VERSION "FM29 IBUS1 + IBUS2, V390.1 20230120, generated by sunnypilot/webhud/tools/gen_ibus.py"

NS_ :

BS_:

BU_: ADAS AMP FloatingButtons GW ICC MFSS PWC_L PWC_R RAC Rotator

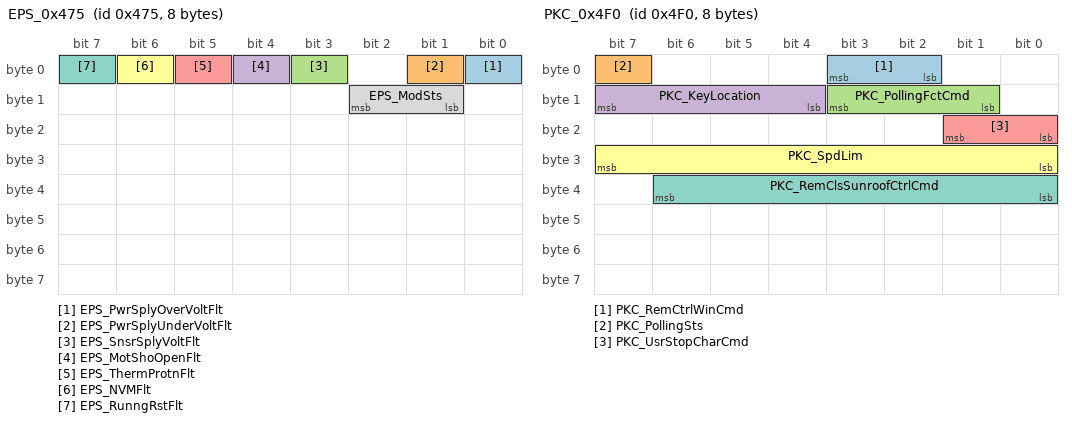
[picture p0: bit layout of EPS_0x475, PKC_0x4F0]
BO_ 1141 EPS_0x475: 8 GW
 SG_ EPS_PwrSplyOverVoltFlt : 0|1@0+ (1,0) [0|1] "" ICC
 SG_ EPS_PwrSplyUnderVoltFlt : 1|1@0+ (1,0) [0|1] "" ICC
 SG_ EPS_SnsrSplyVoltFlt : 3|1@0+ (1,0) [0|1] "" ICC
 SG_ EPS_MotShoOpenFlt : 4|1@0+ (1,0) [0|1] "" ICC
 SG_ EPS_ThermProtnFlt : 5|1@0+ (1,0) [0|1] "" ICC
 SG_ EPS_NVMFlt : 6|1@0+ (1,0) [0|1] "" ICC
 SG_ EPS_RunngRstFlt : 7|1@0+ (1,0) [0|1] "" ICC
 SG_ EPS_ModSts : 10|2@0+ (1,0) [0|3] "" ICC

BO_ 1170 PKC_0x492: 8 GW
 SG_ PKC_UsrID : 39|32@0+ (1,0) [0|4.29497e+09] "" ICC

BO_ 1264 PKC_0x4F0: 8 GW
 SG_ PKC_RemCtrlWinCmd : 3|2@0+ (1,0) [0|3] "" ICC
 SG_ PKC_PollingSts : 7|1@0+ (1,0) [0|1] "" ICC
 SG_ PKC_PollingFctCmd : 11|3@0+ (1,0) [0|7] "" ICC
 SG_ PKC_KeyLocation : 15|4@0+ (1,0) [0|15] "" ICC
 SG_ PKC_UsrStopCharCmd : 17|2@0+ (1,0) [0|3] "" ICC
 SG_ PKC_SpdLim : 31|8@0+ (1,0) [0|255] "km/h" ICC
 SG_ PKC_RemClsSunroofCtrlCmd : 38|7@0+ (1,0) [0|100] "%" ICC

BO_ 1265 DSMC_0x4F1: 8 GW
 SG_ DSMC_DrvrSeatTrackSwtSts : 9|2@0+ (1,0) [0|3] "" ICC
 SG_ DSMC_DrvrSeatHeiAdjSwtSts : 11|2@0+ (1,0) [0|3] "" ICC
 SG_ DSMC_DrvrSeatBackAdjSwtSts : 15|2@0+ (1,0) [0|3] "" ICC
 SG_ DSMC_OTARdy_Fb : 17|2@0+ (1,0) [0|3] "" ICC

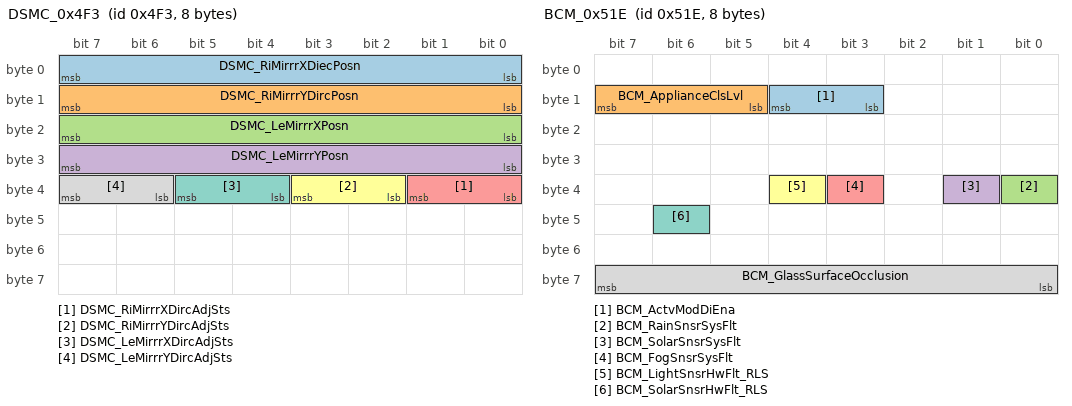
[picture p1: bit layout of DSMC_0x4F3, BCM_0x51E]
BO_ 1267 DSMC_0x4F3: 8 GW
 SG_ DSMC_RiMirrrXDiecPosn : 7|8@0+ (1,0) [0|100] "%" ICC
 SG_ DSMC_RiMirrrYDircPosn : 15|8@0+ (1,0) [0|100] "%" ICC
 SG_ DSMC_LeMirrrXPosn : 23|8@0+ (1,0) [0|100] "%" ICC
 SG_ DSMC_LeMirrrYPosn : 31|8@0+ (1,0) [0|100] "%" ICC
 SG_ DSMC_RiMirrrXDircAdjSts : 33|2@0+ (1,0) [0|3] "" ICC
 SG_ DSMC_RiMirrrYDircAdjSts : 35|2@0+ (1,0) [0|3] "" ICC
 SG_ DSMC_LeMirrrXDircAdjSts : 37|2@0+ (1,0) [0|3] "" ICC
 SG_ DSMC_LeMirrrYDircAdjSts : 39|2@0+ (1,0) [0|3] "" ICC

BO_ 1269 DSMC_0x4F5: 8 GW
 SG_ DSMC_DrvrSeatTrackPosn : 39|8@0+ (1,0) [0|100] "%" ICC
 SG_ DSMC_DrvrSeatHeiPosn : 47|8@0+ (1,0) [0|100] "%" ICC
 SG_ DSMC_DrvrSeatBackPosn : 55|8@0+ (1,0) [0|100] "%" ICC

BO_ 1272 TBOX_0x4F8: 8 GW
 SG_ TBOX_4F4_4F8_CheckSum : 7|8@0+ (1,0) [0|255] "" ICC
 SG_ TBOX_4F4_4F8_AliveCounter : 11|4@0+ (1,0) [0|14] "" ICC
 SG_ TBOX_Sw_upd : 13|2@0+ (1,0) [0|3] "" ICC
 SG_ TBOX_Flsflg : 18|3@0+ (1,0) [0|7] "" ICC
 SG_ TBOX_RemFlsh : 21|3@0+ (1,0) [0|7] "" ICC
 SG_ TBOX_FobdGWPartBUSUDSCom : 23|2@0+ (1,0) [0|3] "" ICC
 SG_ TBOX_RemChrgInsulFctReq : 25|2@0+ (1,0) [0|3] "" ICC
 SG_ TBOX_EHUSetTrvlMod : 27|2@0+ (1,0) [0|3] "" ICC
 SG_ TBOX_ResvACChrgOpenSts : 29|2@0+ (1,0) [0|3] "" ICC
 SG_ TBOX_RemKL15PwrOnReq : 31|2@0+ (1,0) [0|3] "" ICC
 SG_ TBOX_SetChrgEndSOC : 38|7@0+ (1,0) [0|100] "%" ICC
 SG_ TBOX_PreCondTriggerReq : 42|3@0+ (1,0) [0|7] "" ICC
 SG_ TBOX_BlowLvlReq : 45|3@0+ (1,0) [0|7] "" ICC
 SG_ TBOX_ICC_UpdStrt : 47|2@0+ (1,0) [0|3] "" ICC
 SG_ TBOX_VehiMod : 51|4@0+ (1,0) [0|15] "" ICC
 SG_ TBOX_Crash_cfm : 53|2@0+ (1,0) [0|3] "" ICC
 SG_ TBOX_SchedChrgnReq : 57|2@0+ (1,0) [0|3] "" ICC

BO_ 1273 TBOX_0x4F9: 8 GW
 SG_ TBOX_OTAResFb : 14|3@0+ (1,0) [0|7] "" ICC
 SG_ TBOX_SpdLim : 23|8@0+ (1,0) [0|255] "km/h" ICC
 SG_ TBOX_OTA_TiRng : 31|16@0+ (1,0) [0|65534] "mintue" ICC

BO_ 1287 VCU_0x507: 8 GW
 SG_ VCU_OTAVehInhb_QM_Fb : 5|2@0+ (1,0) [0|3] "" ICC
 SG_ VCU_OTAVehCdnChk_QM_sts : 7|2@0+ (1,0) [0|3] "" ICC
 SG_ VCU_DrvAvl : 8|1@0+ (1,0) [0|1] "" ICC
 SG_ VCU_CllsnSigSts : 9|1@0+ (1,0) [0|1] "" ICC
 SG_ VCU_VehSts_GB : 13|2@0+ (1,0) [0|3] "" ICC
 SG_ VCU_MCUOverTFlt_GB : 14|1@0+ (1,0) [0|1] "" ICC
 SG_ VCU_DrvrMotOverTFlt_GB : 15|1@0+ (1,0) [0|1] "" ICC
 SG_ VCU_SOCTooLoAlrm : 16|1@0+ (1,0) [0|1] "" ICC
 SG_ VCU_SOCJumpAlrm : 17|1@0+ (1,0) [0|1] "" ICC
 SG_ VCU_PwrBattPackMismatAlrm : 18|1@0+ (1,0) [0|1] "" ICC
 SG_ VCU_SOCTooHiAlrm : 19|1@0+ (1,0) [0|1] "" ICC
 SG_ VCU_DCDCEnaCmd : 20|1@0+ (1,0) [0|1] "" ICC
 SG_ VCU_PwrBattECCEnaCmd : 22|1@0+ (1,0) [0|1] "" ICC
 SG_ VCU_MstRlyCtrlCmd : 23|1@0+ (1,0) [0|1] "" ICC
 SG_ VCU_DCDCOutpVoltCmd : 31|8@0+ (0.1,0) [0|25.5] "V" ICC
 SG_ VCU_CCCnctnVolt : 39|8@0+ (0.1,0) [0|25.5] "V" ICC
 SG_ VCU_GearSig_GB : 43|4@0+ (1,0) [0|15] "" ICC
 SG_ VCU_DrvrMotNr_GB : 47|4@0+ (1,0) [0|15] "" ICC
 SG_ VCU_BattVolt : 55|16@0+ (0.001,0) [0|65.535] "V" ICC

BO_ 1298 PSM_0x512: 8 GW
 SG_ PSM_PassSeatHeatgSts : 4|3@0+ (1,0) [0|7] "" ICC
 SG_ PSM_PassSeatVentnSts : 7|3@0+ (1,0) [0|7] "" ICC
 SG_ PSM_PassSeatTrackAdjSts : 9|2@0+ (1,0) [0|3] "" ICC
 SG_ PSM_PassSeatBackAdjSts : 11|2@0+ (1,0) [0|3] "" ICC
 SG_ PSM_OTARdy_Fb : 13|2@0+ (1,0) [0|3] "" ICC

BO_ 1300 MFS_0x514: 8 MFSS
 SG_ MFS_0x514_CheckSum : 7|8@0+ (1,0) [0|255] "" ICC
 SG_ MFS_0x514_AliveCounter : 11|4@0+ (1,0) [0|14] "" ICC
 SG_ MFS_LeBtnNorth : 13|2@0+ (1,0) [0|3] "" ICC
 SG_ MFS_LeBtnSouth : 15|2@0+ (1,0) [0|3] "" ICC
 SG_ MFS_LeBtnWest : 17|2@0+ (1,0) [0|3] "" ICC
 SG_ MFS_LeBtnEast : 19|2@0+ (1,0) [0|3] "" ICC
 SG_ MFS_LeRollUp : 22|3@0+ (1,0) [0|7] "" ICC
 SG_ MFS_LeRollDwn : 26|3@0+ (1,0) [0|7] "" ICC
 SG_ MFS_LeRollPress : 28|2@0+ (1,0) [0|3] "" ICC
 SG_ MFS_RiBtnNorth : 30|2@0+ (1,0) [0|3] "" ICC
 SG_ MFS_RiBtnSouth : 33|2@0+ (1,0) [0|3] "" ICC
 SG_ MFS_RiBtnWest : 35|2@0+ (1,0) [0|3] "" ICC
 SG_ MFS_RiBtnEast : 37|2@0+ (1,0) [0|3] "" ICC
 SG_ MFS_RiRollUp : 42|3@0+ (1,0) [0|7] "" ICC
 SG_ MFS_RiRollDwn : 45|3@0+ (1,0) [0|7] "" ICC
 SG_ MFS_RiRollPress : 47|2@0+ (1,0) [0|3] "" ICC
 SG_ MFS_Ri_Fail : 49|2@0+ (1,0) [0|3] "" ICC
 SG_ MFS_Le_Fail : 51|2@0+ (1,0) [0|3] "" ICC

BO_ 1304 DSMC_0x518: 8 GW
 SG_ DSMC_DrvrSeatHeatgSts : 2|3@0+ (1,0) [0|7] "" ICC
 SG_ DSMC_DrvrSeatTrackAdjSts : 7|2@0+ (1,0) [0|3] "" ICC
 SG_ DSMC_DrvrSeatHeiAdjSts : 9|2@0+ (1,0) [0|3] "" ICC
 SG_ DSMC_DrvrSeatBackAdjSts : 11|2@0+ (1,0) [0|3] "" ICC
 SG_ DSMC_RearLeSeatHeatgSts : 26|3@0+ (1,0) [0|7] "" ICC
 SG_ DSMC_RearRiSeatHeatgSts : 29|3@0+ (1,0) [0|7] "" ICC

BO_ 1310 BCM_0x51E: 8 GW
 SG_ BCM_ActvModDiEna : 12|2@0+ (1,0) [0|3] "" ICC
 SG_ BCM_ApplianceClsLvl : 15|3@0+ (1,0) [0|7] "" ICC
 SG_ BCM_RainSnsrSysFlt : 32|1@0+ (1,0) [0|1] "" ICC
 SG_ BCM_SolarSnsrSysFlt : 33|1@0+ (1,0) [0|1] "" ICC
 SG_ BCM_FogSnsrSysFlt : 35|1@0+ (1,0) [0|1] "" ICC
 SG_ BCM_LightSnsrHwFlt_RLS : 36|1@0+ (1,0) [0|1] "" ICC
 SG_ BCM_SolarSnsrHwFlt_RLS : 46|1@0+ (1,0) [0|1] "" ICC
 SG_ BCM_GlassSurfaceOcclusion : 63|8@0+ (1,0) [0|255] "" ICC

BO_ 1314 DSMC_0x522: 8 GW
 SG_ DSMC_IninSts : 0|1@0+ (1,0) [0|1] "" ICC
 SG_ DSMC_CrtSts : 1|1@0+ (1,0) [0|1] "" ICC
 SG_ DSMC_SteerWhlYSts : 3|2@0+ (1,0) [0|3] "" ICC
 SG_ DSMC_SteerWhlZSts : 5|2@0+ (1,0) [0|3] "" ICC
 SG_ DSMC_SteerWhlYDirPosn : 15|8@0+ (1,0) [0|100] "%" ICC
 SG_ DSMC_SteerWhlZDirPosn : 23|8@0+ (1,0) [0|100] "%" ICC
 SG_ DSMC_RotationReqSteerClmnFb : 25|2@0+ (1,0) [0|1] "" ICC

BO_ 1315 PWC_R_0x523: 8 PWC_R
 SG_ PWC_R_ChrgSts : 18|3@0+ (1,0) [0|7] "" ICC
 SG_ PWC_R_PhnForgetRemdSts : 19|1@0+ (1,0) [0|1] "" ICC
 SG_ PWC_R_ModleSwtSts : 20|1@0+ (1,0) [0|1] "" ICC
 SG_ PWC_R_ChrgPhnChkSts : 25|1@0+ (1,0) [0|1] "" ICC

BO_ 1316 PWC_0x524: 8 PWC_L
 SG_ PWC_ChrgSts : 18|3@0+ (1,0) [0|7] "" ICC
 SG_ PWC_PhnForgetRemdSts : 19|1@0+ (1,0) [0|1] "" ICC
 SG_ PWC_ModleSwtSts : 20|1@0+ (1,0) [0|1] "" ICC
 SG_ PWC_ChrgPhnChkSts : 25|1@0+ (1,0) [0|1] "" ICC

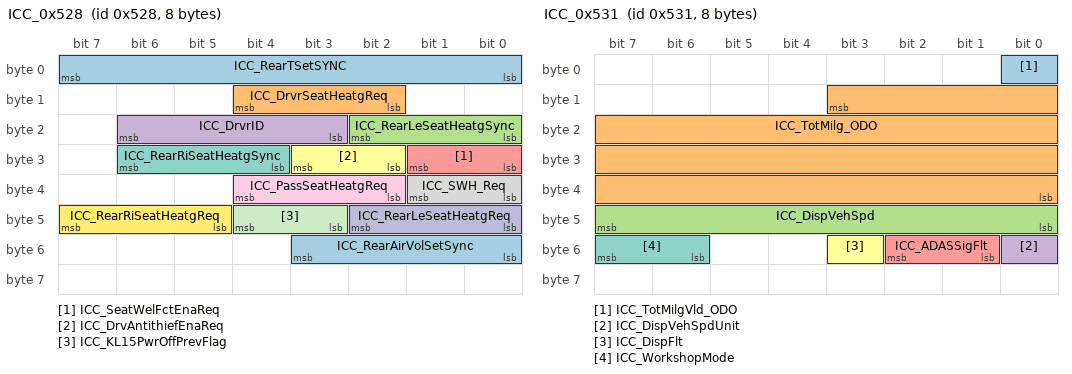
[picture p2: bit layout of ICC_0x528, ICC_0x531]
BO_ 1320 ICC_0x528: 8 ICC
 SG_ ICC_RearTSetSYNC : 7|8@0+ (0.5,0) [0|127.5] "Degree Celsius" ICC
 SG_ ICC_DrvrSeatHeatgReq : 12|3@0+ (1,0) [0|7] "" ICC
 SG_ ICC_RearLeSeatHeatgSync : 18|3@0+ (1,0) [0|7] "" ICC
 SG_ ICC_DrvrID : 22|4@0+ (1,0) [0|15] "" ICC
 SG_ ICC_SeatWelFctEnaReq : 25|2@0+ (1,0) [0|3] "" ICC
 SG_ ICC_DrvAntithiefEnaReq : 27|2@0+ (1,0) [0|3] "" ICC
 SG_ ICC_RearRiSeatHeatgSync : 30|3@0+ (1,0) [0|7] "" ICC
 SG_ ICC_SWH_Req : 33|2@0+ (1,0) [0|3] "" ICC
 SG_ ICC_PassSeatHeatgReq : 36|3@0+ (1,0) [0|7] "" ICC
 SG_ ICC_RearLeSeatHeatgReq : 42|3@0+ (1,0) [0|7] "" ICC
 SG_ ICC_KL15PwrOffPrevFlag : 44|2@0+ (1,0) [0|3] "" ICC
 SG_ ICC_RearRiSeatHeatgReq : 47|3@0+ (1,0) [0|7] "" ICC
 SG_ ICC_RearAirVolSetSync : 51|4@0+ (1,0) [0|15] "" ICC

BO_ 1321 ICC_0x529: 8 ICC
 SG_ ICC_CtrlSts_NFC : 0|1@0+ (1,0) [0|1] "" ICC
 SG_ ICC_CtrlSts_PWC : 1|1@0+ (1,0) [0|1] "" ICC
 SG_ ICC_DispUnit : 3|1@0+ (1,0) [0|1] "" ICC
 SG_ ICC_ReOperPanSwtCmd : 4|1@0+ (1,0) [0|1] "" ICC
 SG_ ICC_ReOperPanSwtSts : 5|1@0+ (1,0) [0|1] "" ICC
 SG_ ICC_SteerWhlPhnKeyBackLi : 7|2@0+ (1,0) [0|3] "" ICC
 SG_ ICC_BackgndBriLvl : 11|4@0+ (1,0) [0|15] "" ICC
 SG_ ICC_TempUnit : 15|1@0+ (1,0) [0|1] "" ICC
 SG_ ICC_V2G_Ena : 19|1@0+ (1,0) [0|1] "" ICC
 SG_ ICC_V2H_Ena : 20|1@0+ (1,0) [0|1] "" ICC
 SG_ ICC_V2V_Ena : 21|1@0+ (1,0) [0|1] "" ICC
 SG_ ICC_V2L_ChrgPortEna : 22|1@0+ (1,0) [0|1] "" ICC
 SG_ ICC_V2L_TrEna : 23|1@0+ (1,0) [0|1] "" ICC
 SG_ ICC_ReOperPanLockCmd : 33|1@0+ (1,0) [0|1] "" ICC
 SG_ ICC_RollingCounter : 39|5@0+ (1,0) [0|31] "" ICC
 SG_ ICC_WiprSrvPosn : 41|2@0+ (1,0) [0|3] "" ICC
 SG_ ICC_SpclTerrainModReq : 44|3@0+ (1,0) [0|7] "" ICC
 SG_ ICC_NavOnSts : 46|2@0+ (1,0) [0|3] "" ICC
 SG_ ICC_DoorCtrlSwtSts : 49|2@0+ (1,0) [0|3] "" ICC
 SG_ ICC_CrtLanguage : 55|6@0+ (1,0) [0|63] "" ICC
 SG_ ICC_NavBarShift : 62|7@0+ (1,0) [0|100] "" ICC

BO_ 1328 ICC_0x530: 8 ICC
 SG_ ICC_DrvrTSet : 7|8@0+ (0.5,0) [0|127.5] "Degree Celsius" ICC
 SG_ ICC_PassTSet : 15|8@0+ (0.5,0) [0|127.5] "Degree Celsius" ICC
 SG_ ICC_VSPVoiceTypSwt : 17|1@0+ (1,0) [0|1] "" ICC
 SG_ ICC_ECCAUTOReq : 19|1@0+ (1,0) [0|1] "" ICC
 SG_ ICC_DrvrSYNCReq : 20|1@0+ (1,0) [0|1] "" ICC
 SG_ ICC_ACSwtReq : 21|1@0+ (1,0) [0|1] "" ICC
 SG_ ICC_AirVolSet : 27|4@0+ (1,0) [0|15] "" ICC
 SG_ ICC_ECCIntExtCircReq : 28|1@0+ (1,0) [0|1] "" ICC
 SG_ ICC_AirClnSwtReq : 29|1@0+ (1,0) [0|1] "" ICC
 SG_ ICC_MaxFrntDefrstSet : 30|1@0+ (1,0) [0|1] "" ICC
 SG_ ICC_VSPCtrlCmd : 31|1@0+ (1,0) [0|1] "" ICC
 SG_ ICC_NavCtryCod : 39|8@0+ (1,0) [0|255] "" ICC
 SG_ ICC_NavRoadTyp : 43|4@0+ (1,0) [0|15] "" ICC
 SG_ ICC_NavSpdLimUnit : 45|2@0+ (1,0) [0|3] "" ICC
 SG_ ICC_NavSpdLimSts : 47|2@0+ (1,0) [0|3] "" ICC
 SG_ ICC_NavSpdLim : 53|6@0+ (1,0) [0|63] "" ICC
 SG_ ICC_BlowWinBtn : 55|1@0+ (1,0) [0|1] "" ICC
 SG_ ICC_NavSpdLimExitDst : 63|8@0+ (10,0) [0|2550] "m" ICC

BO_ 1329 ICC_0x531: 8 ICC
 SG_ ICC_TotMilgVld_ODO : 0|1@0+ (1,0) [0|1] "" ICC
 SG_ ICC_TotMilg_ODO : 11|28@0+ (0.01,0) [0|2e+06] "km" ICC
 SG_ ICC_DispVehSpd : 47|8@0+ (1,0) [0|255] "" ICC
 SG_ ICC_DispVehSpdUnit : 48|1@0+ (1,0) [0|1] "" ICC
 SG_ ICC_ADASSigFlt : 50|2@0+ (1,0) [0|3] "" ICC
 SG_ ICC_DispFlt : 51|1@0+ (1,0) [0|1] "" ICC
 SG_ ICC_WorkshopMode : 55|2@0+ (1,0) [0|3] "" ICC

BO_ 1330 ICC_0x532: 8 ICC
 SG_ ICC_MilgOffs_ODO : 7|8@0+ (1,0) [0|255] "km" ICC
 SG_ ICC_DispTotMilg_ODO : 11|28@0+ (0.01,0) [0|2e+06] "km" ICC
 SG_ ICC_MilgDataVld_ODO : 40|1@0+ (1,0) [0|1] "" ICC
 SG_ ICC_MilgRstCntr_ODO : 42|2@0+ (1,0) [0|3] "" ICC

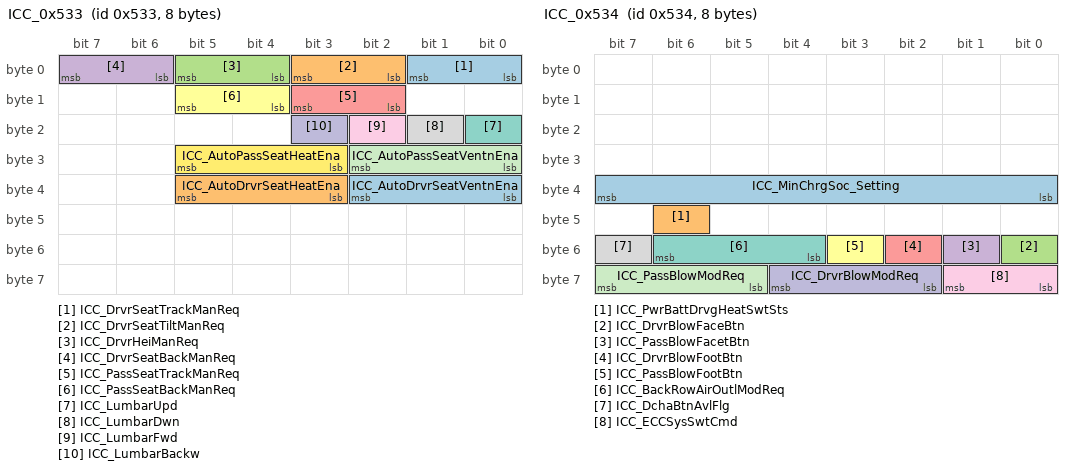
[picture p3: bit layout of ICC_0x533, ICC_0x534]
BO_ 1331 ICC_0x533: 8 ICC
 SG_ ICC_DrvrSeatTrackManReq : 1|2@0+ (1,0) [0|3] "" ICC
 SG_ ICC_DrvrSeatTiltManReq : 3|2@0+ (1,0) [0|3] "" ICC
 SG_ ICC_DrvrHeiManReq : 5|2@0+ (1,0) [0|3] "" ICC
 SG_ ICC_DrvrSeatBackManReq : 7|2@0+ (1,0) [0|3] "" ICC
 SG_ ICC_PassSeatTrackManReq : 11|2@0+ (1,0) [0|3] "" ICC
 SG_ ICC_PassSeatBackManReq : 13|2@0+ (1,0) [0|3] "" ICC
 SG_ ICC_LumbarUpd : 16|1@0+ (1,0) [0|1] "" ICC
 SG_ ICC_LumbarDwn : 17|1@0+ (1,0) [0|1] "" ICC
 SG_ ICC_LumbarFwd : 18|1@0+ (1,0) [0|1] "" ICC
 SG_ ICC_LumbarBackw : 19|1@0+ (1,0) [0|1] "" ICC
 SG_ ICC_AutoPassSeatVentnEna : 26|3@0+ (1,0) [0|7] "" ICC
 SG_ ICC_AutoPassSeatHeatEna : 29|3@0+ (1,0) [0|7] "" ICC
 SG_ ICC_AutoDrvrSeatVentnEna : 34|3@0+ (1,0) [0|7] "" ICC
 SG_ ICC_AutoDrvrSeatHeatEna : 37|3@0+ (1,0) [0|7] "" ICC

BO_ 1332 ICC_0x534: 8 ICC
 SG_ ICC_MinChrgSoc_Setting : 39|8@0+ (1,0) [0|255] "%" ICC
 SG_ ICC_PwrBattDrvgHeatSwtSts : 46|1@0+ (1,0) [0|1] "" ICC
 SG_ ICC_DrvrBlowFaceBtn : 48|1@0+ (1,0) [0|1] "" ICC
 SG_ ICC_PassBlowFacetBtn : 49|1@0+ (1,0) [0|1] "" ICC
 SG_ ICC_DrvrBlowFootBtn : 50|1@0+ (1,0) [0|1] "" ICC
 SG_ ICC_PassBlowFootBtn : 51|1@0+ (1,0) [0|1] "" ICC
 SG_ ICC_BackRowAirOutlModReq : 54|3@0+ (1,0) [0|7] "" ICC
 SG_ ICC_DchaBtnAvlFlg : 55|1@0+ (1,0) [0|1] "" ICC
 SG_ ICC_ECCSysSwtCmd : 57|2@0+ (1,0) [0|3] "" ICC
 SG_ ICC_DrvrBlowModReq : 60|3@0+ (1,0) [0|7] "" ICC
 SG_ ICC_PassBlowModReq : 63|3@0+ (1,0) [0|7] "" ICC

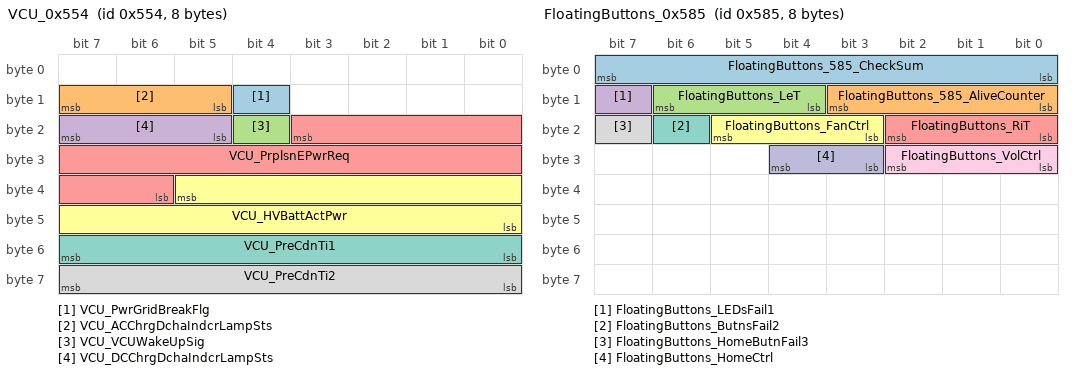
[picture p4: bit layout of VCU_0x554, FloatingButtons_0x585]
BO_ 1364 VCU_0x554: 8 GW
 SG_ VCU_PwrGridBreakFlg : 12|1@0+ (1,0) [0|1] "" ICC
 SG_ VCU_ACChrgDchaIndcrLampSts : 15|3@0+ (1,0) [0|7] "" ICC
 SG_ VCU_VCUWakeUpSig : 20|1@0+ (1,0) [0|1] "" ICC
 SG_ VCU_DCChrgDchaIndcrLampSts : 23|3@0+ (1,0) [0|7] "" ICC
 SG_ VCU_PrplsnEPwrReq : 19|14@0+ (0.1,-600) [-600|600] "KW" ICC
 SG_ VCU_HVBattActPwr : 37|14@0+ (0.1,-600) [-600|600] "KW" ICC
 SG_ VCU_PreCdnTi1 : 55|8@0+ (1,0) [0|255] "min" ICC
 SG_ VCU_PreCdnTi2 : 63|8@0+ (1,0) [0|255] "min" ICC

BO_ 1379 ICC_0x563: 8 ICC
 SG_ ICC_0x563_CheckSum : 7|8@0+ (1,0) [0|255] "" ICC
 SG_ ICC_0x563_AliveCounter : 11|4@0+ (1,0) [0|14] "" ICC
 SG_ ICC_CID_Pos_Learn : 14|3@0+ (1,0) [0|7] "" ICC
 SG_ ICC_CID_Command_Valid : 15|1@0+ (1,0) [0|1] "" ICC
 SG_ ICC_CID_Target_Position : 23|8@0+ (1.8,0) [0|360] "" ICC
 SG_ ICC_CID_Rot_Speed : 31|8@0+ (1,-100) [-100|100] "" ICC

BO_ 1400 VCU_0x578: 8 GW
 SG_ VCU_NotChrgModECCCnseEgy : 7|16@0+ (0.1,0) [0|6553.5] "kWh" ICC
 SG_ VCU_NotChrgModVehDrvCnseEgy : 23|16@0+ (0.1,0) [0|6553.5] "kWh" ICC
 SG_ VCU_NotChrgModBHMCnseEgy : 39|16@0+ (0.1,0) [0|6553.5] "kWh" ICC
 SG_ VCU_NotChrgModExtDchaCnseEgy : 55|16@0+ (0.1,0) [0|6553.5] "kWh" ICC

BO_ 1401 VCU_0x579: 8 GW
 SG_ VCU_NotChrgModAcsyCnseEgy : 7|16@0+ (0.1,0) [0|6553.5] "kWh" ICC
 SG_ VCU_NotChrgModVehTotCnseEgy : 23|16@0+ (0.1,0) [0|6553.5] "kWh" ICC
 SG_ VCU_ChrgModECCCnseEgy : 39|16@0+ (0.1,0) [0|6553.5] "kWh" ICC
 SG_ VCU_ChrgModVehChrgEgy : 55|16@0+ (0.1,0) [0|6553.5] "kWh" ICC

BO_ 1402 VCU_0x57A: 8 GW
 SG_ VCU_ChrgModBattHeatgMngCnseEgy : 7|16@0+ (0.1,0) [0|6553.5] "kWh" ICC
 SG_ VCU_ChrgModAcsyCnseEgy : 23|16@0+ (0.1,0) [0|6553.5] "kWh" ICC
 SG_ VCU_ChrgModChrgEffCnseEgy : 39|16@0+ (0.1,0) [0|6553.5] "kWh" ICC
 SG_ VCU_ChrgModVehTotChrgEgy : 55|16@0+ (0.1,0) [0|6553.5] "kWh" ICC

BO_ 1403 VCU_0x57B: 8 GW
 SG_ VCU_NotChrgModECCCnseEgyPerc : 7|12@0+ (0.1,0) [0|100] "%" ICC
 SG_ VCU_NotChrgModVehDrvCnseEgyPerc : 11|12@0+ (0.1,0) [0|100] "%" ICC
 SG_ VCU_NotChrgModBHMCnseEgyPerc : 31|12@0+ (0.1,0) [0|100] "%" ICC
 SG_ VCU_NotChrgModExtDchaCnseEgyPerc : 35|12@0+ (0.1,0) [0|100] "%" ICC
 SG_ VCU_NotChrgModAcsyCnseEgyPerc : 51|12@0+ (0.1,0) [0|100] "%" ICC

BO_ 1404 VCU_0x57C: 8 GW
 SG_ VCU_ChrgModECCCnseEgyPerc : 7|12@0+ (0.1,0) [0|100] "%" ICC
 SG_ VCU_ChrgModVehChrgEgyPerc : 11|12@0+ (0.1,0) [0|100] "%" ICC
 SG_ VCU_ChrgModBHMCnseEgyPerc : 31|12@0+ (0.1,0) [0|100] "%" ICC
 SG_ VCU_ChrgModAcsyCnseEgyPerc : 35|12@0+ (0.1,0) [0|100] "%" ICC
 SG_ VCU_ActEgyCnsTyp : 53|2@0+ (1,0) [0|3] "" ICC
 SG_ VCU_ChrgModChrgEffCnseEgyPerc : 51|12@0+ (0.1,0) [0|100] "%" ICC

BO_ 1413 FloatingButtons_0x585: 8 FloatingButtons
 SG_ FloatingButtons_585_CheckSum : 7|8@0+ (1,0) [0|255] "" ICC
 SG_ FloatingButtons_585_AliveCounter : 11|4@0+ (1,0) [0|14] "" ICC
 SG_ FloatingButtons_LeT : 14|3@0+ (1,0) [0|7] "" ICC
 SG_ FloatingButtons_LEDsFail1 : 15|1@0+ (1,0) [0|1] "" ICC
 SG_ FloatingButtons_RiT : 18|3@0+ (1,0) [0|7] "" ICC
 SG_ FloatingButtons_FanCtrl : 21|3@0+ (1,0) [0|7] "" ICC
 SG_ FloatingButtons_ButnsFail2 : 22|1@0+ (1,0) [0|1] "" ICC
 SG_ FloatingButtons_HomeButnFail3 : 23|1@0+ (1,0) [0|1] "" ICC
 SG_ FloatingButtons_VolCtrl : 26|3@0+ (1,0) [0|7] "" ICC
 SG_ FloatingButtons_HomeCtrl : 28|2@0+ (1,0) [0|3] "" ICC

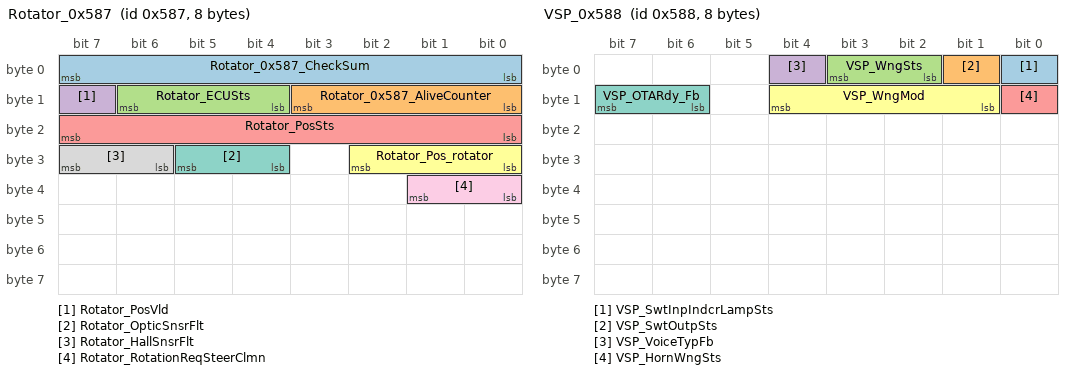
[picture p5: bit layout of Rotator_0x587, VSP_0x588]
BO_ 1415 Rotator_0x587: 8 Rotator
 SG_ Rotator_0x587_CheckSum : 7|8@0+ (1,0) [0|255] "" ICC
 SG_ Rotator_0x587_AliveCounter : 11|4@0+ (1,0) [0|14] "" ICC
 SG_ Rotator_ECUSts : 14|3@0+ (1,0) [0|7] "" ICC
 SG_ Rotator_PosVld : 15|1@0+ (1,0) [0|1] "" ICC
 SG_ Rotator_PosSts : 23|8@0+ (1.8,0) [0|90] "" ICC
 SG_ Rotator_Pos_rotator : 26|3@0+ (1,0) [0|7] "" ICC
 SG_ Rotator_OpticSnsrFlt : 29|2@0+ (1,0) [0|3] "" ICC
 SG_ Rotator_HallSnsrFlt : 31|2@0+ (1,0) [0|3] "" ICC
 SG_ Rotator_RotationReqSteerClmn : 33|2@0+ (1,0) [0|1] "" ICC

BO_ 1416 VSP_0x588: 8 GW
 SG_ VSP_SwtInpIndcrLampSts : 0|1@0+ (1,0) [0|1] "" ICC
 SG_ VSP_SwtOutpSts : 1|1@0+ (1,0) [0|1] "" ICC
 SG_ VSP_WngSts : 3|2@0+ (1,0) [0|3] "" ICC
 SG_ VSP_VoiceTypFb : 4|1@0+ (1,0) [0|1] "" ICC
 SG_ VSP_HornWngSts : 8|1@0+ (1,0) [0|1] "" ICC
 SG_ VSP_WngMod : 12|4@0+ (1,0) [0|15] "" ICC
 SG_ VSP_OTARdy_Fb : 15|2@0+ (1,0) [0|3] "" ICC

BO_ 1450 TBOX_0x5AA: 8 GW
 SG_ TBOX_Wifi_ConnectSts : 13|2@0+ (1,0) [0|3] "" ICC
 SG_ TBOX_Wifi_ConnectStrgthSts : 22|7@0+ (1,-100) [-100|-30] "dBm" ICC

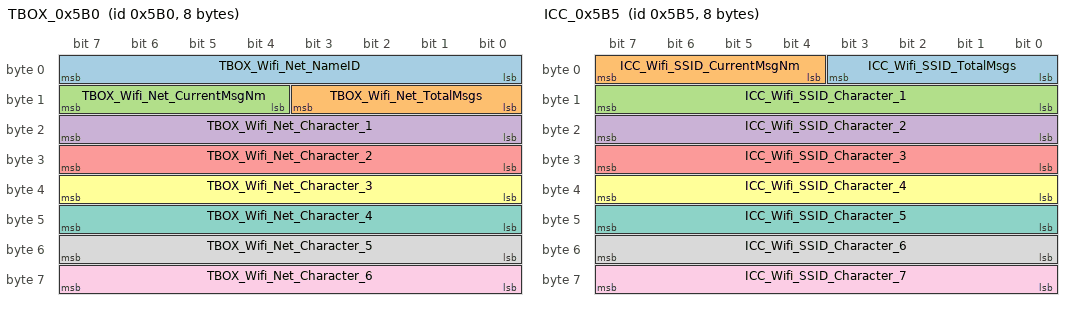
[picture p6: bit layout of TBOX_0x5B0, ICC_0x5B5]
BO_ 1456 TBOX_0x5B0: 8 GW
 SG_ TBOX_Wifi_Net_NameID : 7|8@0+ (1,0) [0|255] "" ICC
 SG_ TBOX_Wifi_Net_TotalMsgs : 11|4@0+ (1,0) [0|15] "" ICC
 SG_ TBOX_Wifi_Net_CurrentMsgNm : 15|4@0+ (1,0) [0|15] "" ICC
 SG_ TBOX_Wifi_Net_Character_1 : 23|8@0+ (1,0) [0|255] "" ICC
 SG_ TBOX_Wifi_Net_Character_2 : 31|8@0+ (1,0) [0|255] "" ICC
 SG_ TBOX_Wifi_Net_Character_3 : 39|8@0+ (1,0) [0|255] "" ICC
 SG_ TBOX_Wifi_Net_Character_4 : 47|8@0+ (1,0) [0|255] "" ICC
 SG_ TBOX_Wifi_Net_Character_5 : 55|8@0+ (1,0) [0|255] "" ICC
 SG_ TBOX_Wifi_Net_Character_6 : 63|8@0+ (1,0) [0|255] "" ICC

BO_ 1461 ICC_0x5B5: 8 ICC
 SG_ ICC_Wifi_SSID_TotalMsgs : 3|4@0+ (1,0) [0|15] "" ICC
 SG_ ICC_Wifi_SSID_CurrentMsgNm : 7|4@0+ (1,0) [0|15] "" ICC
 SG_ ICC_Wifi_SSID_Character_1 : 15|8@0+ (1,0) [0|255] "" ICC
 SG_ ICC_Wifi_SSID_Character_2 : 23|8@0+ (1,0) [0|255] "" ICC
 SG_ ICC_Wifi_SSID_Character_3 : 31|8@0+ (1,0) [0|255] "" ICC
 SG_ ICC_Wifi_SSID_Character_4 : 39|8@0+ (1,0) [0|255] "" ICC
 SG_ ICC_Wifi_SSID_Character_5 : 47|8@0+ (1,0) [0|255] "" ICC
 SG_ ICC_Wifi_SSID_Character_6 : 55|8@0+ (1,0) [0|255] "" ICC
 SG_ ICC_Wifi_SSID_Character_7 : 63|8@0+ (1,0) [0|255] "" ICC

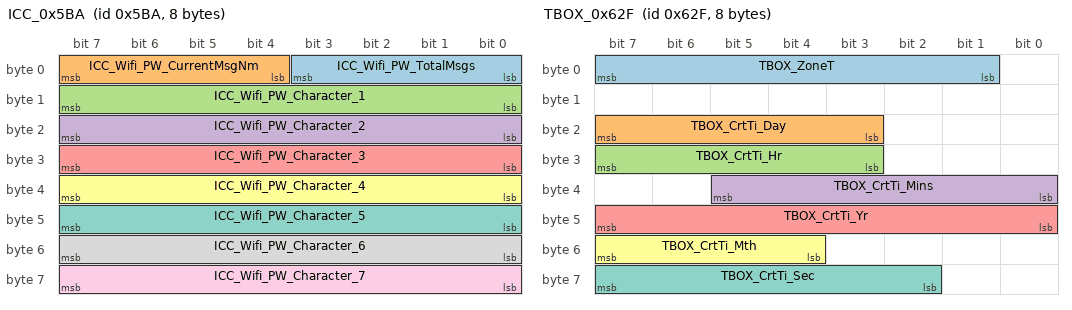
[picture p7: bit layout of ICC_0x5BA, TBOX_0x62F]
BO_ 1466 ICC_0x5BA: 8 ICC
 SG_ ICC_Wifi_PW_TotalMsgs : 3|4@0+ (1,0) [0|15] "" ICC
 SG_ ICC_Wifi_PW_CurrentMsgNm : 7|4@0+ (1,0) [0|15] "" ICC
 SG_ ICC_Wifi_PW_Character_1 : 15|8@0+ (1,0) [0|255] "" ICC
 SG_ ICC_Wifi_PW_Character_2 : 23|8@0+ (1,0) [0|255] "" ICC
 SG_ ICC_Wifi_PW_Character_3 : 31|8@0+ (1,0) [0|255] "" ICC
 SG_ ICC_Wifi_PW_Character_4 : 39|8@0+ (1,0) [0|255] "" ICC
 SG_ ICC_Wifi_PW_Character_5 : 47|8@0+ (1,0) [0|255] "" ICC
 SG_ ICC_Wifi_PW_Character_6 : 55|8@0+ (1,0) [0|255] "" ICC
 SG_ ICC_Wifi_PW_Character_7 : 63|8@0+ (1,0) [0|255] "" ICC

BO_ 1471 TBOX_0x5BF: 8 GW
 SG_ TBOX_Wifi_Net_StrgthID : 7|8@0+ (1,0) [0|255] "" ICC
 SG_ TBOX_Wifi_Net_StrgthSts : 14|7@0+ (1,-100) [-100|-30] "" ICC
 SG_ TBOX_Wifi_Net_Encryp : 17|2@0+ (1,0) [0|3] "" ICC

BO_ 1480 TBOX_0x5C8: 8 GW
 SG_ TBOX_OTA_ownCondchk : 1|2@0+ (1,0) [0|3] "" ICC
 SG_ TBOX_TerminalRemWakeupSig : 2|1@0+ (1,0) [0|1] "" ICC
 SG_ TBOX_RemSCModReq : 4|2@0+ (1,0) [0|3] "" ICC
 SG_ TBOX_RemPwrBattOpenHeatgReq : 6|2@0+ (1,0) [0|3] "" ICC
 SG_ TBOX_RemPwrBattResvHeatgReq : 7|1@0+ (1,0) [0|1] "" ICC
 SG_ TBOX_RemInsdInfoDispEna : 12|1@0+ (1,0) [0|1] "" ICC
 SG_ TBOX_RemECCDefrstModReq : 14|2@0+ (1,0) [0|3] "" ICC
 SG_ TBOX_RemECCResvDefrstReq : 15|1@0+ (1,0) [0|1] "" ICC
 SG_ TBOX_RemECCSetT : 31|8@0+ (0.5,0) [0|127.5] "Degree Celsius" ICC
 SG_ TBOX_RemResvECCSetT : 39|8@0+ (0.5,0) [0|127.5] "Degree Celsius" ICC
 SG_ TBOX_RemSOCMax : 47|8@0+ (1,0) [0|100] "" ICC
 SG_ TBOX_4GSigIND : 49|2@0+ (1,0) [0|3] "" ICC
 SG_ TBOX_Conn_Typ : 52|3@0+ (1,0) [0|7] "" ICC
 SG_ TBOX_TSPNotConn : 53|1@0+ (1,0) [0|1] "" ICC
 SG_ TBOX_EHUNotCONN : 54|1@0+ (1,0) [0|1] "" ICC
 SG_ TBOX_WIFIError : 55|1@0+ (1,0) [0|1] "" ICC
 SG_ TBOX_InnerBattError : 56|1@0+ (1,0) [0|1] "" ICC
 SG_ TBOX_VoltLow : 57|1@0+ (1,0) [0|1] "" ICC
 SG_ TBOX_VoltHigh : 58|1@0+ (1,0) [0|1] "" ICC
 SG_ TBOX_4GLoss : 59|1@0+ (1,0) [0|1] "" ICC
 SG_ TBOX_RemSWH_Req : 61|2@0+ (1,0) [0|3] "" ICC
 SG_ TBOX_OTAInhbReq : 63|2@0+ (1,0) [0|3] "" ICC

BO_ 1514 VCU_0x5EA: 8 GW
 SG_ VCU_TripMilg : 23|16@0+ (0.1,0) [0|6550] "km" ICC
 SG_ VCU_TripAvgEgyConsmd : 39|10@0+ (1,0) [0|1023] "Wh/km" ICC

BO_ 1552 ICC_0x610: 8 ICC
 SG_ ICC_UsrSetChrgRmnMilg : 7|8@0+ (1,0) [0|255] "" ICC
 SG_ ICC_EPedlSts : 9|2@0+ (1,0) [0|3] "" ICC
 SG_ ICC_AccelMod : 11|2@0+ (1,0) [0|3] "" ICC
 SG_ ICC_BoostMode : 13|2@0+ (1,0) [0|3] "" ICC
 SG_ ICC_EgyCnseClrFlg : 15|2@0+ (1,0) [0|3] "" ICC
 SG_ ICC_VehiMod : 21|4@0+ (1,0) [0|15] "" ICC
 SG_ ICC_EgyCnseStcClrFlg : 23|2@0+ (1,0) [0|3] "" ICC
 SG_ ICC_UsrSetDchaEndDrvgMilg : 17|10@0+ (1,0) [0|800] "km" ICC
 SG_ ICC_PollingFctOpenSts : 33|2@0+ (1,0) [0|3] "" ICC
 SG_ ICC_KickFctOpenSts : 35|2@0+ (1,0) [0|3] "" ICC
 SG_ ICC_UsrSetChrgGunAntithft : 36|1@0+ (1,0) [0|1] "" ICC
 SG_ ICC_ChrgInsulFctReq : 38|2@0+ (1,0) [0|3] "" ICC
 SG_ ICC_StopChrgBtn : 39|1@0+ (1,0) [0|1] "" ICC
 SG_ ICC_DrvModSig : 42|3@0+ (1,0) [0|7] "" ICC
 SG_ ICC_SetACChrgLmtCrt : 49|2@0+ (1,0) [0|3] "" ICC
 SG_ ICC_SetTrvlMod : 51|2@0+ (1,0) [0|3] "" ICC
 SG_ ICC_RegenLvl : 54|2@0+ (1,0) [0|3] "" ICC
 SG_ ICC_SetChrgEndSOC : 62|7@0+ (1,0) [0|100] "%" ICC
 SG_ ICC_StartChrgBtn : 63|1@0+ (1,0) [0|1] "" ICC

BO_ 1583 TBOX_0x62F: 8 GW
 SG_ TBOX_ZoneT : 7|7@0+ (15,-720) [-720|1185] "min" ICC
 SG_ TBOX_CrtTi_Day : 23|5@0+ (1,1) [1|31] "day" ICC
 SG_ TBOX_CrtTi_Hr : 31|5@0+ (1,0) [0|23] "hour" ICC
 SG_ TBOX_CrtTi_Mins : 37|6@0+ (1,0) [0|59] "mintue" ICC
 SG_ TBOX_CrtTi_Yr : 47|8@0+ (1,2015) [2015|2270] "year" ICC
 SG_ TBOX_CrtTi_Mth : 55|4@0+ (1,1) [1|12] "month" ICC
 SG_ TBOX_CrtTi_Sec : 63|6@0+ (1,0) [0|59] "second" ICC

BO_ 1649 PWC_R_0x671: 8 PWC_R
 SG_ PWC_R_SwVersS : 15|8@0+ (1,0) [0|255] "" ICC
 SG_ PWC_R_PartVers : 23|32@0+ (1,0) [0|4.29497e+09] "" ICC
 SG_ PWC_R_HwVers : 55|8@0+ (1,0) [0|255] "" ICC
 SG_ PWC_R_SwVersM : 63|8@0+ (1,0) [0|255] "" ICC

BO_ 1652 PWC_0x674: 8 PWC_L
 SG_ PWC_SwVersS : 15|8@0+ (1,0) [0|255] "" ICC
 SG_ PWC_PartVers : 23|32@0+ (1,0) [0|4.29497e+09] "" ICC
 SG_ PWC_HwVers : 55|8@0+ (1,0) [0|255] "" ICC
 SG_ PWC_SwVersM : 63|8@0+ (1,0) [0|255] "" ICC

BO_ 1653 AMP_0x675: 8 AMP
 SG_ AMP_CalHwVers : 7|8@0+ (1,0) [0|255] "" ICC
 SG_ AMP_SwVersS : 15|8@0+ (1,0) [0|255] "" ICC
 SG_ AMP_PartVers : 23|32@0+ (1,0) [0|4.29497e+09] "" ICC
 SG_ AMP_HwVers : 55|8@0+ (1,0) [0|255] "" ICC
 SG_ AMP_SwVersM : 63|8@0+ (1,0) [0|255] "" ICC

BO_ 1672 MFS_0x688: 8 MFSS
 SG_ MFS_SwVersS : 7|8@0+ (1,0) [0|255] "" ICC
 SG_ MFS_PartVers : 23|32@0+ (1,0) [0|4.29497e+09] "" ICC
 SG_ MFS_HwVers : 55|8@0+ (1,0) [0|255] "" ICC
 SG_ MFS_SwVersM : 63|8@0+ (1,0) [0|255] "" ICC

BO_ 1675 RAC_0x68B: 8 RAC
 SG_ RAC_SwVersS : 15|8@0+ (1,0) [0|255] "" ICC
 SG_ RAC_PartVers : 23|32@0+ (1,0) [0|4.29497e+09] "" ICC
 SG_ RAC_HwVers : 55|8@0+ (1,0) [0|255] "" ICC
 SG_ RAC_SwVersM : 63|8@0+ (1,0) [0|255] "" ICC

BO_ 1696 BMS_PVIU_EnergyCounterActual: 8 GW
 SG_ BMS_mxCounterActEnergy : 7|8@0+ (1,0) [0|255] "" ICC
 SG_ BMS_mxEnergyActValue1 : 15|24@0+ (1,0) [0|1.67772e+07] "Wh" ICC
 SG_ BMS_mxEnergyActValue2 : 39|24@0+ (1,0) [0|1.67772e+07] "Wh" ICC
 SG_ DCDC_ActTemp : 63|8@0+ (1,-40) [-40|210] "Degree Celsius" ICC

BO_ 1756 BMS_PVIU_EnergyCounterHistory: 8 GW
 SG_ BMS_mxCounterEnergy : 7|8@0+ (1,0) [0|255] "" ICC
 SG_ BMS_mxEnergyValue1 : 15|24@0+ (1,0) [0|1.67772e+07] "Wh" ICC
 SG_ BMS_mxEnergyValue2 : 39|24@0+ (1,0) [0|1.67772e+07] "Wh" ICC

BO_ 1757 BMS_PVIU_ActualPower: 8 GW
 SG_ BMS_PVIU_actPower : 7|10@0+ (1,0) [0|1023] "W" ICC
 SG_ BMS_PVIU_EnergyOverall : 23|24@0+ (1,0) [0|1.67772e+07] "kWh" ICC
 SG_ BMS_PVIU_ActEngyYear : 47|24@0+ (1,0) [0|1.67772e+07] "Wh" ICC

BO_ 1760 BCM_0x6E0: 8 GW
 SG_ BCM_VIN_Byte1 : 15|8@0+ (1,0) [0|255] "" ICC
 SG_ BCM_VIN_Byte2 : 23|8@0+ (1,0) [0|255] "" ICC
 SG_ BCM_VIN_Byte3 : 31|8@0+ (1,0) [0|255] "" ICC
 SG_ BCM_VIN_Byte4 : 39|8@0+ (1,0) [0|255] "" ICC
 SG_ BCM_VIN_Byte5 : 47|8@0+ (1,0) [0|255] "" ICC
 SG_ BCM_VIN_Byte6 : 55|8@0+ (1,0) [0|255] "" ICC
 SG_ BCM_VIN_Byte7 : 63|8@0+ (1,0) [0|255] "" ICC

BO_ 233 BMS_ActualPack_U_I: 8 GW
 SG_ BMS_Bat_HVmeasure_CheckSum : 7|8@0+ (1,0) [0|255] "" ICC
 SG_ BMS_Bat_HVmeasure_AliveCounter : 11|4@0+ (1,0) [0|14] "" ICC
 SG_ BMS_Bat_HVmeasure_Current : 39|16@0- (0.05,0) [-1250|1250] "A" ICC
 SG_ BMS_Bat_Hvmeasure_V_Pack : 55|16@0+ (0.01,0) [0|655.35] "V" ICC

BO_ 261 VCU_0x105: 8 GW
 SG_ VCU_105_CheckSum : 7|8@0+ (1,0) [0|255] "" ICC
 SG_ VCU_105_AliveCounter : 11|4@0+ (1,0) [0|14] "" ICC
 SG_ VCU_DmdTqFltFlg : 15|1@0+ (1,0) [0|1] "" ICC
 SG_ VCU_AllwMntnIndcrLamp : 16|1@0+ (1,0) [0|1] "" ICC
 SG_ VCU_AlrmLamp_FS : 17|1@0+ (1,0) [0|1] "" ICC
 SG_ VCU_VehTqDistbnRat : 45|14@0+ (0.01,0) [0|100] "" ICC

BO_ 279 ADAS_0x117: 8 ADAS
 SG_ ADAS_117_CheckSum : 7|8@0+ (1,0) [0|255] "" ICC
 SG_ ADAS_117_AliveCounter : 11|4@0+ (1,0) [0|14] "" ICC
 SG_ ADAS_OTARdy_Fb : 13|2@0+ (1,0) [0|3] "" ICC
 SG_ ADAS_OTAInhbRdy : 15|2@0+ (1,0) [0|3] "" ICC
 SG_ ADAS_LgtCtrl_Sts : 18|3@0+ (1,0) [0|7] "" ICC
 SG_ ADAS_LgtCtrl_StsVld : 20|2@0+ (1,0) [0|3] "" ICC
 SG_ ADAS_LgtCtrl_DrvrOvrdSts : 21|1@0+ (1,0) [0|1] "" ICC
 SG_ ADAS_LgtCtrl_DrvrOvrdVld : 23|2@0+ (1,0) [0|3] "" ICC
 SG_ ADAS_HAP_EmgyStandstillVld : 25|2@0+ (1,0) [0|3] "" ICC
 SG_ ADAS_HAP_EmgyEPBVld : 27|2@0+ (1,0) [0|3] "" ICC
 SG_ ADAS_HAP_EmgyStandstillReq : 28|1@0+ (1,0) [0|1] "" ICC
 SG_ ADAS_ParkStandstillReq : 29|1@0+ (1,0) [0|1] "" ICC
 SG_ ADAS_ParkStandstillVld : 31|2@0+ (1,0) [0|3] "" ICC
 SG_ ADAS_ParkGearReq : 35|4@0+ (1,0) [0|15] "" ICC
 SG_ ADAS_ParkGearReqVld : 37|2@0+ (1,0) [0|3] "" ICC
 SG_ ADAS_ISA_CutOffReqVld : 39|2@0+ (1,0) [0|3] "" ICC
 SG_ ADAS_LgtCtrl_Typ : 43|4@0+ (1,0) [0|15] "" ICC
 SG_ ADAS_HAP_EmgyEPBReq : 44|1@0+ (1,0) [0|1] "" ICC
 SG_ ADAS_ISA_CutOffReq : 46|1@0+ (1,0) [0|1] "" ICC
 SG_ ADAS_ISA_SpdLmt_VCU : 63|8@0+ (1,0) [0|255] "kph" ICC

BO_ 280 ADAS_0x118: 8 ADAS
 SG_ ADAS_118_CheckSum : 7|8@0+ (1,0) [0|255] "" ICC
 SG_ ADAS_118_AliveCounter : 11|4@0+ (1,0) [0|14] "" ICC
 SG_ ADAS_LgtCtrl_ESP_Sts : 18|3@0+ (1,0) [0|7] "" ICC
 SG_ ADAS_LgtCtrl_ESP_Vld : 20|2@0+ (1,0) [0|3] "" ICC
 SG_ ADAS_ESP_DrvrOvrdSts : 21|1@0+ (1,0) [0|1] "" ICC
 SG_ ADAS_ESP_DrvrOvrdVld : 23|2@0+ (1,0) [0|3] "" ICC
 SG_ ADAS_HBAReq : 26|3@0+ (1,0) [0|7] "" ICC
 SG_ ADAS_HBAVld : 28|2@0+ (1,0) [0|3] "" ICC
 SG_ ADAS_ESP_StandstillReq : 29|1@0+ (1,0) [0|1] "" ICC
 SG_ ADAS_ESP_StandstillVld : 31|2@0+ (1,0) [0|3] "" ICC
 SG_ ADAS_JerkReq : 33|2@0+ (1,0) [0|3] "" ICC
 SG_ ADAS_JerkReqVld : 35|2@0+ (1,0) [0|3] "" ICC
 SG_ ADAS_BrkPrefillReq : 37|2@0+ (1,0) [0|3] "" ICC
 SG_ ADAS_BrkPrefillVld : 39|2@0+ (1,0) [0|3] "" ICC
 SG_ ADAS_AEB_ActvTyp : 43|4@0+ (1,0) [0|15] "" ICC
 SG_ ADAS_AEB_DecelVld : 45|2@0+ (1,0) [0|3] "" ICC
 SG_ ADAS_AEB_DecelReq : 55|16@0+ (0.0004882,-16) [-16|15.9942] "m/s2" ICC

BO_ 281 iBooster_0x119: 8 GW
 SG_ iBooster_119_CheckSum : 7|8@0+ (1,0) [0|255] "" ICC
 SG_ iBooster_119_AliveCounter : 11|4@0+ (1,0) [0|14] "" ICC
 SG_ iBooster_OTARdy_Fb : 13|2@0+ (1,0) [0|3] "" ICC
 SG_ iBooster_WarnOn : 16|1@0+ (1,0) [0|1] "" ICC
 SG_ iBooster_BrkPedlAppldFlg : 19|1@0+ (1,0) [0|1] "" ICC
 SG_ iBooster_BrkPedlAppldVld : 25|2@0+ (1,0) [0|3] "" ICC

BO_ 369 ICC_0x171: 8 ICC
 SG_ ICC_Start_X_Coordinate : 7|16@0+ (1,0) [0|65534] "" ICC
 SG_ ICC_Start_Y_Coordinate : 23|16@0+ (1,0) [0|65534] "" ICC
 SG_ ICC_dX_Coordinate : 39|16@0+ (1,0) [0|65534] "" ICC
 SG_ ICC_dY_Coordinate : 55|16@0+ (1,0) [0|65534] "" ICC

BO_ 416 VCU_0x1A0: 8 GW
 SG_ VCU_ECC_PwrMax : 23|16@0+ (0.01,0) [0|20] "KW" ICC
 SG_ VCU_ECC_PwrMin : 39|16@0+ (0.01,0) [0|20] "KW" ICC
 SG_ VCU_DCDCPwrLimCmd : 55|11@0+ (0.01,0) [0|20] "KW" ICC

BO_ 425 ECC_0x1A9: 8 GW
 SG_ ECC_VCU_ReqChgPwrLim : 15|3@0+ (1,0) [0|7] "" ICC
 SG_ ECC_VCU_PwrReq : 23|16@0+ (0.01,0) [0|20] "KW" ICC
 SG_ ECC_OTARdy_Fb : 33|2@0+ (1,0) [0|3] "" ICC

BO_ 438 PKC_0x1B6: 8 GW
 SG_ PKC_1B6_CheckSum : 7|8@0+ (1,0) [0|255] "" ICC
 SG_ PKC_1B6_AliveCounter : 11|4@0+ (1,0) [0|14] "" ICC
 SG_ PKC_TpMnvrCancel : 13|2@0+ (1,0) [0|3] "" ICC
 SG_ PKC_TpActDeactInp : 15|2@0+ (1,0) [0|3] "" ICC
 SG_ PKC_RemPwrOnOffReq : 17|2@0+ (1,0) [0|3] "" ICC
 SG_ PKC_RemDrvgReq : 21|4@0+ (1,0) [0|15] "" ICC
 SG_ PKC_RemChrgDchaGunUnlckCmd : 23|2@0+ (1,0) [0|3] "" ICC
 SG_ PKC_RmteDviceBattLvl : 31|8@0+ (1,0) [0|100] "%" ICC
 SG_ PKC_BLE_Online : 32|1@0+ (1,0) [0|1] "" ICC
 SG_ PKC_DviceRngeDist : 34|2@0+ (1,0) [0|3] "" ICC
 SG_ PKC_DviceAliveCnt : 39|4@0+ (1,0) [0|15] "" ICC
 SG_ PKC_MnvreEnblInput : 41|2@0+ (1,0) [0|3] "" ICC
 SG_ PKC_RapActDeactInp : 47|2@0+ (1,0) [0|3] "" ICC
 SG_ PKC_MnvrRemsumeKey : 49|2@0+ (1,0) [0|3] "" ICC
 SG_ PKC_MnvrRtnStartKey : 51|2@0+ (1,0) [0|3] "" ICC
 SG_ PKC_AuthUsr : 59|2@0+ (1,0) [0|3] "" ICC
 SG_ PKC_AlcInterlockReqPromt : 61|2@0+ (1,0) [0|3] "" ICC
 SG_ PKC_NFCReminderPromt : 63|2@0+ (1,0) [0|3] "" ICC

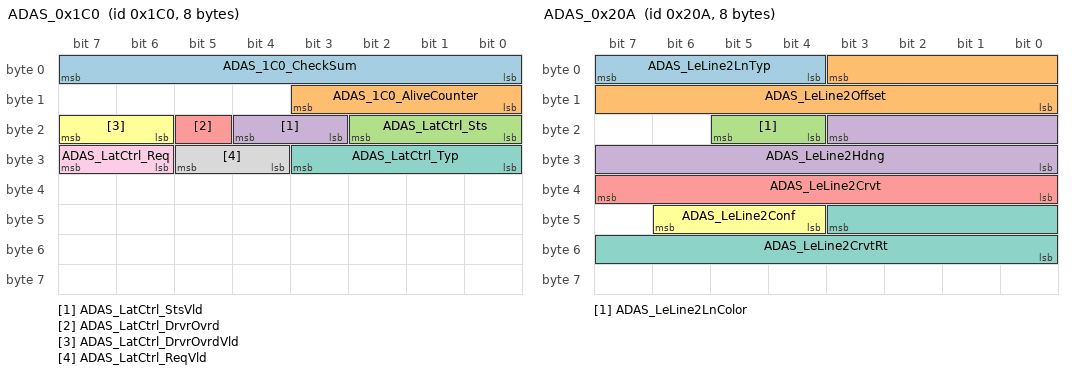
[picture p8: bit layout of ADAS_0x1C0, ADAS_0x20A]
BO_ 448 ADAS_0x1C0: 8 ADAS
 SG_ ADAS_1C0_CheckSum : 7|8@0+ (1,0) [0|255] "" ICC
 SG_ ADAS_1C0_AliveCounter : 11|4@0+ (1,0) [0|14] "" ICC
 SG_ ADAS_LatCtrl_Sts : 18|3@0+ (1,0) [0|7] "" ICC
 SG_ ADAS_LatCtrl_StsVld : 20|2@0+ (1,0) [0|3] "" ICC
 SG_ ADAS_LatCtrl_DrvrOvrd : 21|1@0+ (1,0) [0|1] "" ICC
 SG_ ADAS_LatCtrl_DrvrOvrdVld : 23|2@0+ (1,0) [0|3] "" ICC
 SG_ ADAS_LatCtrl_Typ : 27|4@0+ (1,0) [0|15] "" ICC
 SG_ ADAS_LatCtrl_ReqVld : 29|2@0+ (1,0) [0|3] "" ICC
 SG_ ADAS_LatCtrl_Req : 31|2@0+ (1,0) [0|3] "" ICC

BO_ 522 ADAS_0x20A: 8 ADAS
 SG_ ADAS_LeLine2LnTyp : 7|4@0+ (1,0) [0|15] "" ICC
 SG_ ADAS_LeLine2Offset : 3|12@0+ (0.0125,0) [0|50] "m" ICC
 SG_ ADAS_LeLine2LnColor : 21|2@0+ (1,0) [0|3] "" ICC
 SG_ ADAS_LeLine2Hdng : 19|12@0+ (0.05,0) [0|180] "deg" ICC
 SG_ ADAS_LeLine2Crvt : 39|8@0+ (50,-3150) [-3150|3200] "m" ICC
 SG_ ADAS_LeLine2Conf : 46|3@0+ (1,0) [0|7] "" ICC
 SG_ ADAS_LeLine2CrvtRt : 43|12@0+ (0.05,0) [0|180] "xx" ICC

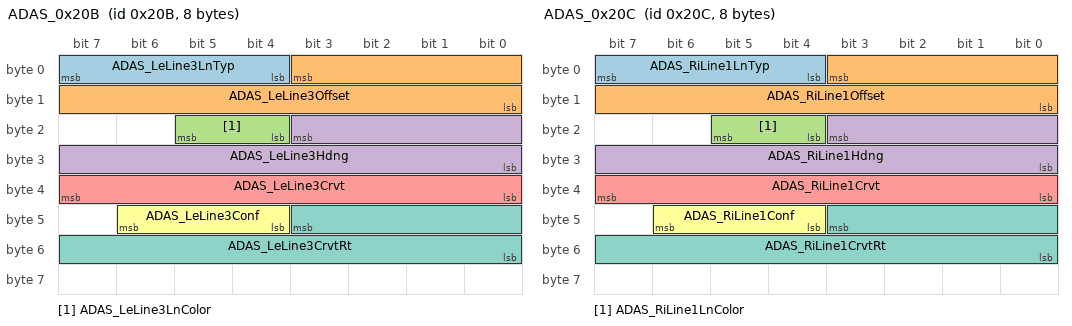
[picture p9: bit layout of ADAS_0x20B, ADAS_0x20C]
BO_ 523 ADAS_0x20B: 8 ADAS
 SG_ ADAS_LeLine3LnTyp : 7|4@0+ (1,0) [0|15] "" ICC
 SG_ ADAS_LeLine3Offset : 3|12@0+ (0.0125,0) [0|50] "m" ICC
 SG_ ADAS_LeLine3LnColor : 21|2@0+ (1,0) [0|3] "" ICC
 SG_ ADAS_LeLine3Hdng : 19|12@0+ (0.05,0) [0|180] "deg" ICC
 SG_ ADAS_LeLine3Crvt : 39|8@0+ (50,-3150) [-3150|3200] "m" ICC
 SG_ ADAS_LeLine3Conf : 46|3@0+ (1,0) [0|7] "" ICC
 SG_ ADAS_LeLine3CrvtRt : 43|12@0+ (0.0125,0) [0|50] "xx" ICC

BO_ 524 ADAS_0x20C: 8 ADAS
 SG_ ADAS_RiLine1LnTyp : 7|4@0+ (1,0) [0|15] "" ICC
 SG_ ADAS_RiLine1Offset : 3|12@0+ (0.0125,0) [0|50] "m" ICC
 SG_ ADAS_RiLine1LnColor : 21|2@0+ (1,0) [0|3] "" ICC
 SG_ ADAS_RiLine1Hdng : 19|12@0+ (0.05,0) [0|180] "deg" ICC
 SG_ ADAS_RiLine1Crvt : 39|8@0+ (50,-3150) [-3150|3200] "m" ICC
 SG_ ADAS_RiLine1Conf : 46|3@0+ (1,0) [0|7] "" ICC
 SG_ ADAS_RiLine1CrvtRt : 43|12@0+ (0.0125,0) [0|50] "xx" ICC

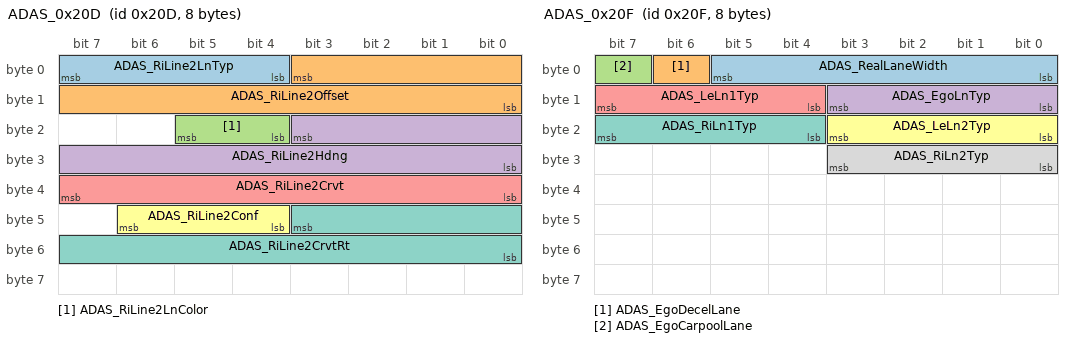
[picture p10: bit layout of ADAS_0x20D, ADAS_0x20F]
BO_ 525 ADAS_0x20D: 8 ADAS
 SG_ ADAS_RiLine2LnTyp : 7|4@0+ (1,0) [0|15] "" ICC
 SG_ ADAS_RiLine2Offset : 3|12@0+ (0.0125,0) [0|50] "m" ICC
 SG_ ADAS_RiLine2LnColor : 21|2@0+ (1,0) [0|3] "" ICC
 SG_ ADAS_RiLine2Hdng : 19|12@0+ (0.05,0) [0|180] "deg" ICC
 SG_ ADAS_RiLine2Crvt : 39|8@0+ (50,-3150) [-3150|3200] "m" ICC
 SG_ ADAS_RiLine2Conf : 46|3@0+ (1,0) [0|7] "" ICC
 SG_ ADAS_RiLine2CrvtRt : 43|12@0+ (0.0125,0) [0|50] "xx" ICC

BO_ 526 ADAS_0x20E: 8 ADAS
 SG_ ADAS_RiLine3LnTyp : 7|4@0+ (1,0) [0|15] "" ICC
 SG_ ADAS_RiLine3Offset : 3|12@0+ (0.0125,0) [0|50] "m" ICC
 SG_ ADAS_RiLine3LnColor : 21|2@0+ (1,0) [0|3] "" ICC
 SG_ ADAS_RiLine3Hdng : 19|12@0+ (0.05,0) [0|180] "deg" ICC
 SG_ ADAS_RiLine3Crvt : 39|8@0+ (50,-3150) [-3150|3200] "m" ICC
 SG_ ADAS_RiLine3Conf : 46|3@0+ (1,0) [0|7] "" ICC
 SG_ ADAS_RiLine3CrvtRt : 43|12@0+ (0.0125,0) [0|50] "xx" ICC

BO_ 527 ADAS_0x20F: 8 ADAS
 SG_ ADAS_RealLaneWidth : 5|6@0+ (0.1,0) [0|6.3] "m" ICC
 SG_ ADAS_EgoDecelLane : 6|1@0+ (1,0) [0|1] "" ICC
 SG_ ADAS_EgoCarpoolLane : 7|1@0+ (1,0) [0|1] "" ICC
 SG_ ADAS_EgoLnTyp : 11|4@0+ (1,0) [0|15] "" ICC
 SG_ ADAS_LeLn1Typ : 15|4@0+ (1,0) [0|15] "" ICC
 SG_ ADAS_LeLn2Typ : 19|4@0+ (1,0) [0|15] "" ICC
 SG_ ADAS_RiLn1Typ : 23|4@0+ (1,0) [0|15] "" ICC
 SG_ ADAS_RiLn2Typ : 27|4@0+ (1,0) [0|15] "" ICC

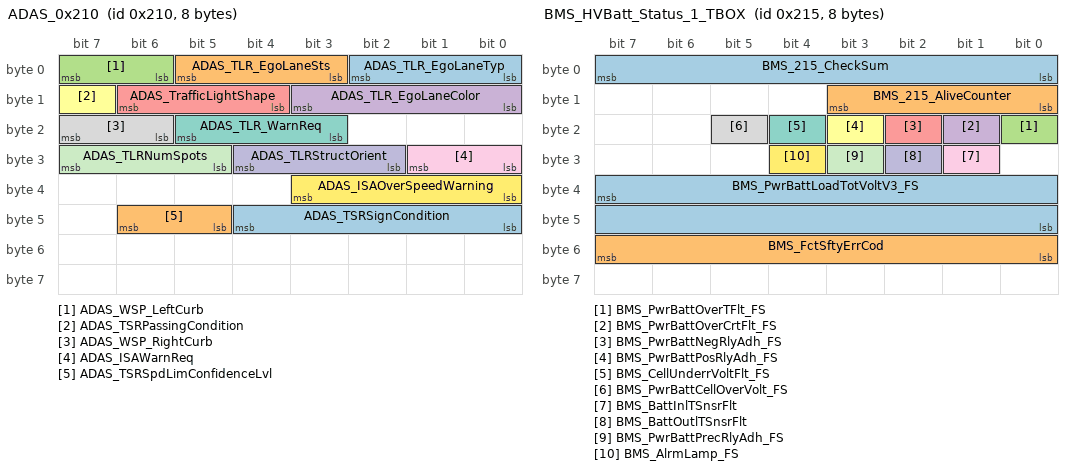
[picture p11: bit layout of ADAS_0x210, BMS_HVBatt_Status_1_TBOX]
BO_ 528 ADAS_0x210: 8 ADAS
 SG_ ADAS_TLR_EgoLaneTyp : 2|3@0+ (1,0) [0|7] "" ICC
 SG_ ADAS_TLR_EgoLaneSts : 5|3@0+ (1,0) [0|7] "" ICC
 SG_ ADAS_WSP_LeftCurb : 7|2@0+ (1,0) [0|3] "" ICC
 SG_ ADAS_TLR_EgoLaneColor : 11|4@0+ (1,0) [0|15] "" ICC
 SG_ ADAS_TrafficLightShape : 14|3@0+ (1,0) [0|7] "" ICC
 SG_ ADAS_TSRPassingCondition : 15|1@0+ (1,0) [0|1] "" ICC
 SG_ ADAS_TLR_WarnReq : 21|3@0+ (1,0) [0|7] "" ICC
 SG_ ADAS_WSP_RightCurb : 23|2@0+ (1,0) [0|3] "" ICC
 SG_ ADAS_ISAWarnReq : 25|2@0+ (1,0) [0|3] "" ICC
 SG_ ADAS_TLRStructOrient : 28|3@0+ (1,0) [0|7] "" ICC
 SG_ ADAS_TLRNumSpots : 31|3@0+ (1,0) [0|7] "" ICC
 SG_ ADAS_ISAOverSpeedWarning : 35|4@0+ (1,0) [0|15] "" ICC
 SG_ ADAS_TSRSignCondition : 44|5@0+ (1,0) [0|31] "" ICC
 SG_ ADAS_TSRSpdLimConfidenceLvl : 46|2@0+ (1,0) [0|3] "" ICC

BO_ 533 BMS_HVBatt_Status_1_TBOX: 8 GW
 SG_ BMS_215_CheckSum : 7|8@0+ (1,0) [0|255] "" ICC
 SG_ BMS_215_AliveCounter : 11|4@0+ (1,0) [0|14] "" ICC
 SG_ BMS_PwrBattOverTFlt_FS : 16|1@0+ (1,0) [0|1] "" ICC
 SG_ BMS_PwrBattOverCrtFlt_FS : 17|1@0+ (1,0) [0|1] "" ICC
 SG_ BMS_PwrBattNegRlyAdh_FS : 18|1@0+ (1,0) [0|1] "" ICC
 SG_ BMS_PwrBattPosRlyAdh_FS : 19|1@0+ (1,0) [0|1] "" ICC
 SG_ BMS_CellUnderrVoltFlt_FS : 20|1@0+ (1,0) [0|1] "" ICC
 SG_ BMS_PwrBattCellOverVolt_FS : 21|1@0+ (1,0) [0|1] "" ICC
 SG_ BMS_BattInlTSnsrFlt : 25|1@0+ (1,0) [0|1] "" ICC
 SG_ BMS_BattOutlTSnsrFlt : 26|1@0+ (1,0) [0|1] "" ICC
 SG_ BMS_PwrBattPrecRlyAdh_FS : 27|1@0+ (1,0) [0|1] "" ICC
 SG_ BMS_AlrmLamp_FS : 28|1@0+ (1,0) [0|1] "" ICC
 SG_ BMS_PwrBattLoadTotVoltV3_FS : 39|16@0+ (0.02,0) [0|1310.7] "V" ICC
 SG_ BMS_FctSftyErrCod : 55|8@0+ (1,0) [0|255] "" ICC

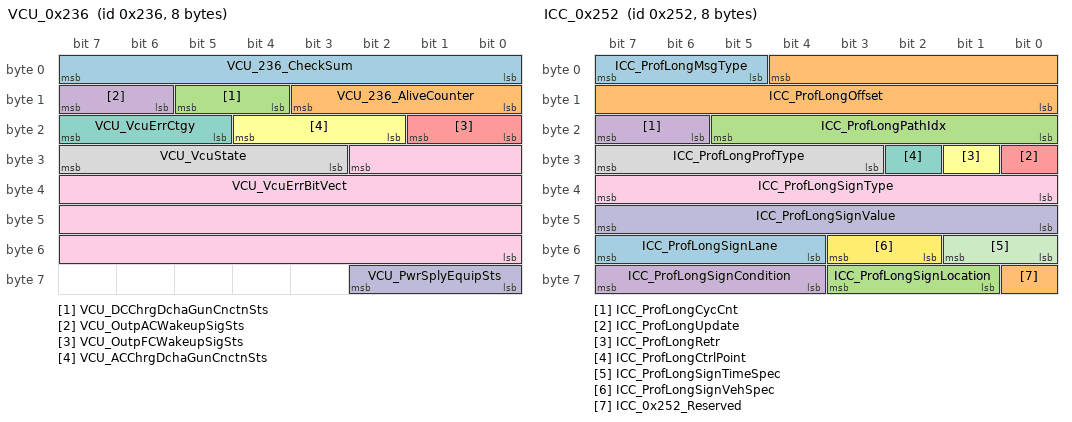
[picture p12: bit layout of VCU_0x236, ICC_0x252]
BO_ 566 VCU_0x236: 8 GW
 SG_ VCU_236_CheckSum : 7|8@0+ (1,0) [0|255] "" ICC
 SG_ VCU_236_AliveCounter : 11|4@0+ (1,0) [0|14] "" ICC
 SG_ VCU_DCChrgDchaGunCnctnSts : 13|2@0+ (1,0) [0|3] "" ICC
 SG_ VCU_OutpACWakeupSigSts : 15|2@0+ (1,0) [0|3] "" ICC
 SG_ VCU_OutpFCWakeupSigSts : 17|2@0+ (1,0) [0|3] "" ICC
 SG_ VCU_ACChrgDchaGunCnctnSts : 20|3@0+ (1,0) [0|7] "" ICC
 SG_ VCU_VcuErrCtgy : 23|3@0+ (1,0) [0|7] "" ICC
 SG_ VCU_VcuState : 31|5@0+ (1,0) [0|31] "" ICC
 SG_ VCU_VcuErrBitVect : 26|27@0+ (1,0) [0|1.34218e+08] "" ICC
 SG_ VCU_PwrSplyEquipSts : 58|3@0+ (1,0) [0|7] "" ICC

BO_ 586 BMS_HVBattCurrent_TBOX: 8 GW
 SG_ BMS_24A_CheckSum : 7|8@0+ (1,0) [0|255] "" ICC
 SG_ BMS_24A_AliveCounter : 11|4@0+ (1,0) [0|14] "" ICC
 SG_ BMS_PwrBattChrgDchaCrt1 : 23|16@0+ (0.04,-1000) [-1000|1621.4] "A" ICC
 SG_ BMS_PwrBattChrgDchaCrt2 : 39|16@0+ (0.04,-1000) [-1000|1621.4] "A" ICC
 SG_ BMS_PwrBattIntTotVoltV1 : 55|16@0+ (0.02,0) [0|1310.7] "V" ICC

BO_ 592 ICC_0x250: 8 ICC
 SG_ ICC_SegMsgType : 7|3@0+ (1,0) [0|7] "" ICC
 SG_ ICC_SegOffset : 4|13@0+ (1,0) [0|8190] "m" ICC
 SG_ ICC_SegPathIdx : 21|6@0+ (1,0) [8|63] "" ICC
 SG_ ICC_SegCycCnt : 23|2@0+ (1,0) [0|3] "" ICC
 SG_ ICC_SegUpdate : 24|1@0+ (1,0) [0|1] "" ICC
 SG_ ICC_SegRetr : 25|1@0+ (1,0) [0|1] "" ICC
 SG_ ICC_SegBuildUpArea : 27|2@0+ (1,0) [0|3] "" ICC
 SG_ ICC_SegBridge : 29|2@0+ (1,0) [0|3] "" ICC
 SG_ ICC_SegTunnel : 31|2@0+ (1,0) [0|3] "" ICC
 SG_ ICC_SegFuncRoadClass : 34|3@0+ (1,0) [0|7] "" ICC
 SG_ ICC_SegRelProbb : 39|5@0+ (3.3333,0) [0|100] "%" ICC
 SG_ ICC_SegFormOfWay : 43|4@0+ (1,0) [0|15] "" ICC
 SG_ ICC_SegCmplxInsct : 45|2@0+ (1,0) [0|3] "" ICC
 SG_ ICC_SegPartOfCalcRoute : 47|2@0+ (1,0) [0|3] "" ICC
 SG_ ICC_SegEffSpdLmtType : 50|3@0+ (1,0) [0|7] "" ICC
 SG_ ICC_SegEffSpdLmt : 55|5@0+ (1,0) [0|31] "km/h or mph" ICC
 SG_ ICC_SegNumOfLaneDrvDir : 58|3@0+ (1,0) [0|7] "" ICC
 SG_ ICC_SegNumOfLaneOppDir : 60|2@0+ (1,0) [0|3] "" ICC
 SG_ ICC_SegDividedRoad : 62|2@0+ (1,0) [0|3] "" ICC

BO_ 593 ICC_0x251: 8 ICC
 SG_ ICC_StubMsgType : 7|3@0+ (1,0) [0|7] "" ICC
 SG_ ICC_StubOffset : 4|13@0+ (1,0) [0|8190] "m" ICC
 SG_ ICC_StubPathIdx : 21|6@0+ (1,0) [8|63] "" ICC
 SG_ ICC_StubCycCnt : 23|2@0+ (1,0) [0|3] "" ICC
 SG_ ICC_StubUpdate : 24|1@0+ (1,0) [0|1] "" ICC
 SG_ ICC_StubRetr : 25|1@0+ (1,0) [0|1] "" ICC
 SG_ ICC_StubStubPathIdx : 31|6@0+ (1,0) [0|63] "" ICC
 SG_ ICC_StubFuncRoadClass : 34|3@0+ (1,0) [0|7] "" ICC
 SG_ ICC_StubRelProbb : 39|5@0+ (3.333,0) [0|100] "%" ICC
 SG_ ICC_StubFormOfWay : 43|4@0+ (1,0) [0|15] "" ICC
 SG_ ICC_StubCmplxInsct : 45|2@0+ (1,0) [0|3] "" ICC
 SG_ ICC_StubPartOfCalcRout : 47|2@0+ (1,0) [0|3] "" ICC
 SG_ ICC_StubTurnAngl : 55|8@0+ (1.417,0) [0|358.583] "degrees" ICC
 SG_ ICC_StubNumOfLaneDrvDir : 58|3@0+ (1,0) [0|7] "" ICC
 SG_ ICC_StubNumOfLaneOppDir : 60|2@0+ (1,0) [0|3] "" ICC
 SG_ ICC_StubRtOfWay : 62|2@0+ (1,0) [0|3] "" ICC
 SG_ ICC_StubLastStub : 63|1@0+ (1,0) [0|1] "" ICC

BO_ 594 ICC_0x252: 8 ICC
 SG_ ICC_ProfLongMsgType : 7|3@0+ (1,0) [0|7] "" ICC
 SG_ ICC_ProfLongOffset : 4|13@0+ (1,0) [0|8190] "m" ICC
 SG_ ICC_ProfLongPathIdx : 21|6@0+ (1,0) [8|63] "" ICC
 SG_ ICC_ProfLongCycCnt : 23|2@0+ (1,0) [0|3] "" ICC
 SG_ ICC_ProfLongUpdate : 24|1@0+ (1,0) [0|1] "" ICC
 SG_ ICC_ProfLongRetr : 25|1@0+ (1,0) [0|1] "" ICC
 SG_ ICC_ProfLongCtrlPoint : 26|1@0+ (1,0) [0|1] "" ICC
 SG_ ICC_ProfLongProfType : 31|5@0+ (1,0) [0|31] "" ICC
 SG_ ICC_ProfLongSignType : 39|8@0+ (1,0) [0|255] "" ICC
 SG_ ICC_ProfLongSignValue : 47|8@0+ (1,0) [0|255] "" ICC
 SG_ ICC_ProfLongSignTimeSpec : 49|2@0+ (1,0) [0|3] "" ICC
 SG_ ICC_ProfLongSignVehSpec : 51|2@0+ (1,0) [0|3] "" ICC
 SG_ ICC_ProfLongSignLane : 55|4@0+ (1,0) [0|15] "" ICC
 SG_ ICC_0x252_Reserved : 56|1@0+ (1,0) [0|1] "" ICC
 SG_ ICC_ProfLongSignLocation : 59|3@0+ (1,0) [0|7] "" ICC
 SG_ ICC_ProfLongSignCondition : 63|4@0+ (1,0) [0|15] "" ICC

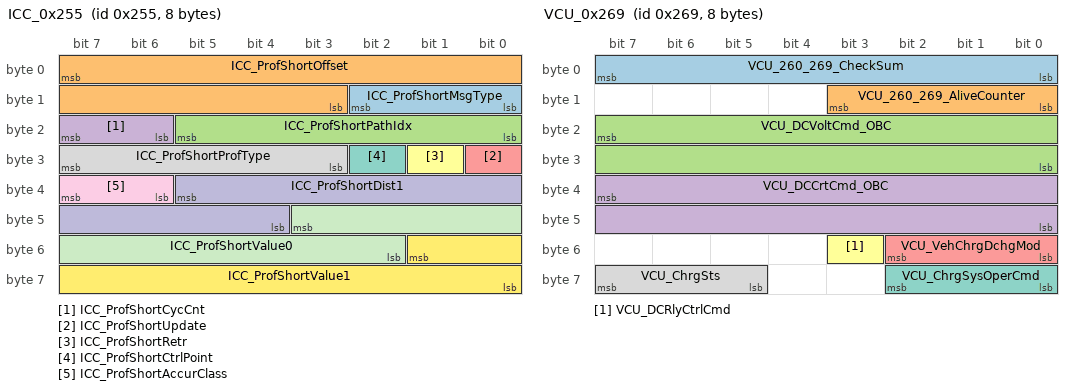
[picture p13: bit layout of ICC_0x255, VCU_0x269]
BO_ 597 ICC_0x255: 8 ICC
 SG_ ICC_ProfShortMsgType : 10|3@0+ (1,0) [0|7] "" ICC
 SG_ ICC_ProfShortOffset : 7|13@0+ (1,0) [0|8190] "m" ICC
 SG_ ICC_ProfShortPathIdx : 21|6@0+ (1,0) [8|63] "" ICC
 SG_ ICC_ProfShortCycCnt : 23|2@0+ (1,0) [0|3] "" ICC
 SG_ ICC_ProfShortUpdate : 24|1@0+ (1,0) [0|1] "" ICC
 SG_ ICC_ProfShortRetr : 25|1@0+ (1,0) [0|1] "" ICC
 SG_ ICC_ProfShortCtrlPoint : 26|1@0+ (1,0) [0|1] "" ICC
 SG_ ICC_ProfShortProfType : 31|5@0+ (1,0) [0|31] "" ICC
 SG_ ICC_ProfShortAccurClass : 39|2@0+ (1,0) [0|3] "" ICC
 SG_ ICC_ProfShortDist1 : 37|10@0+ (1,0) [0|1022] "m" ICC
 SG_ ICC_ProfShortValue0 : 43|10@0+ (1,0) [0|1023] "" ICC
 SG_ ICC_ProfShortValue1 : 49|10@0+ (1,0) [0|1023] "" ICC

BO_ 617 VCU_0x269: 8 GW
 SG_ VCU_260_269_CheckSum : 7|8@0+ (1,0) [0|255] "" ICC
 SG_ VCU_260_269_AliveCounter : 11|4@0+ (1,0) [0|14] "" ICC
 SG_ VCU_DCVoltCmd_OBC : 23|16@0+ (0.02,0) [0|1310.7] "V" ICC
 SG_ VCU_DCCrtCmd_OBC : 39|16@0+ (0.02,0) [0|1310.7] "A" ICC
 SG_ VCU_VehChrgDchgMod : 50|3@0+ (1,0) [0|7] "" ICC
 SG_ VCU_DCRlyCtrlCmd : 51|1@0+ (1,0) [0|1] "" ICC
 SG_ VCU_ChrgSysOperCmd : 58|3@0+ (1,0) [0|7] "" ICC
 SG_ VCU_ChrgSts : 63|3@0+ (1,0) [0|7] "" ICC

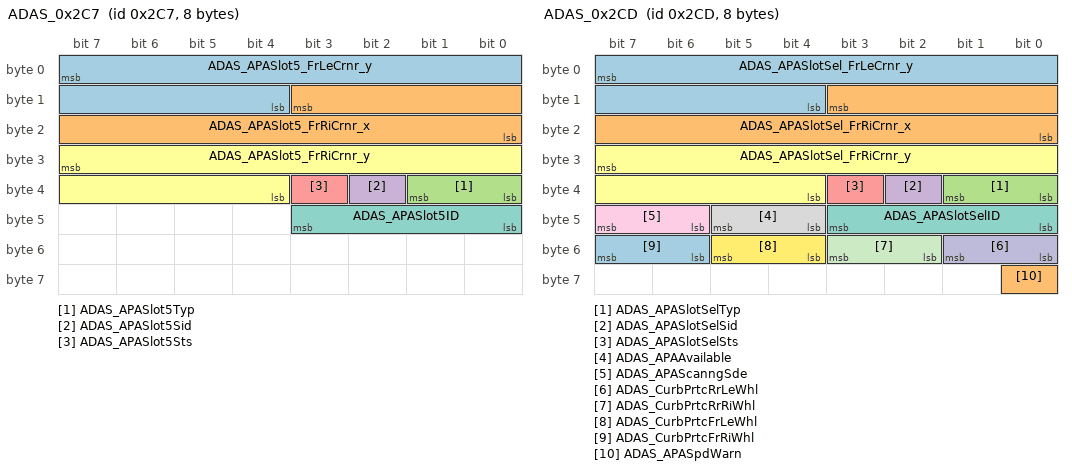
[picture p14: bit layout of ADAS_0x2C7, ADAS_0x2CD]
BO_ 711 ADAS_0x2C7: 8 ADAS
 SG_ ADAS_APASlot5_FrLeCrnr_y : 7|12@0+ (0.05,-100) [-100|100] "m" ICC
 SG_ ADAS_APASlot5_FrRiCrnr_x : 11|12@0+ (0.05,-100) [-100|100] "m" ICC
 SG_ ADAS_APASlot5Typ : 33|2@0+ (1,0) [0|3] "" ICC
 SG_ ADAS_APASlot5Sid : 34|1@0+ (1,0) [0|1] "" ICC
 SG_ ADAS_APASlot5Sts : 35|1@0+ (1,0) [0|1] "" ICC
 SG_ ADAS_APASlot5_FrRiCrnr_y : 31|12@0+ (0.05,-100) [-100|100] "m" ICC
 SG_ ADAS_APASlot5ID : 43|4@0+ (1,0) [0|15] "" ICC

BO_ 714 ADAS_0x2CA: 8 ADAS
 SG_ ADAS_APASlotSel_ReLeCrnr_x : 7|12@0+ (0.05,-100) [-100|100] "m" ICC
 SG_ ADAS_APASlotSel_ReLeCrnr_y : 11|12@0+ (0.05,-100) [-100|100] "m" ICC
 SG_ ADAS_APASlotSel_ReRiCrnr_x : 31|12@0+ (0.05,-100) [-100|100] "m" ICC
 SG_ ADAS_APASlotSel_ReRiCrnr_y : 35|12@0+ (0.05,-100) [-100|100] "m" ICC
 SG_ ADAS_APASlotSel_FrLeCrnr_x : 55|12@0+ (0.05,-100) [-100|100] "m" ICC

BO_ 717 ADAS_0x2CD: 8 ADAS
 SG_ ADAS_APASlotSel_FrLeCrnr_y : 7|12@0+ (0.05,-100) [-100|100] "m" ICC
 SG_ ADAS_APASlotSel_FrRiCrnr_x : 11|12@0+ (0.05,-100) [-100|100] "m" ICC
 SG_ ADAS_APASlotSelTyp : 33|2@0+ (1,0) [0|3] "" ICC
 SG_ ADAS_APASlotSelSid : 34|1@0+ (1,0) [0|1] "" ICC
 SG_ ADAS_APASlotSelSts : 35|1@0+ (1,0) [0|1] "" ICC
 SG_ ADAS_APASlotSel_FrRiCrnr_y : 31|12@0+ (0.05,-100) [-100|100] "m" ICC
 SG_ ADAS_APASlotSelID : 43|4@0+ (1,0) [0|15] "" ICC
 SG_ ADAS_APAAvailable : 45|2@0+ (1,0) [0|3] "" ICC
 SG_ ADAS_APAScanngSde : 47|2@0+ (1,0) [0|3] "" ICC
 SG_ ADAS_CurbPrtcRrLeWhl : 49|2@0+ (1,0) [0|3] "" ICC
 SG_ ADAS_CurbPrtcRrRiWhl : 51|2@0+ (1,0) [0|3] "" ICC
 SG_ ADAS_CurbPrtcFrLeWhl : 53|2@0+ (1,0) [0|3] "" ICC
 SG_ ADAS_CurbPrtcFrRiWhl : 55|2@0+ (1,0) [0|3] "" ICC
 SG_ ADAS_APASpdWarn : 56|1@0+ (1,0) [0|1] "" ICC

BO_ 720 ADAS_0x2D0: 8 ADAS
 SG_ ADAS_APASlot1_ReLeCrnr_x : 7|12@0+ (0.05,-100) [-100|100] "m" ICC
 SG_ ADAS_APASlot1_ReLeCrnr_y : 11|12@0+ (0.05,-100) [-100|100] "m" ICC
 SG_ ADAS_APASlot1_ReRiCrnr_x : 31|12@0+ (0.05,-100) [-100|100] "m" ICC
 SG_ ADAS_APASlot1_ReRiCrnr_y : 35|12@0+ (0.05,-100) [-100|100] "m" ICC
 SG_ ADAS_APASlot1_FrLeCrnr_x : 55|12@0+ (0.05,-100) [-100|100] "m" ICC

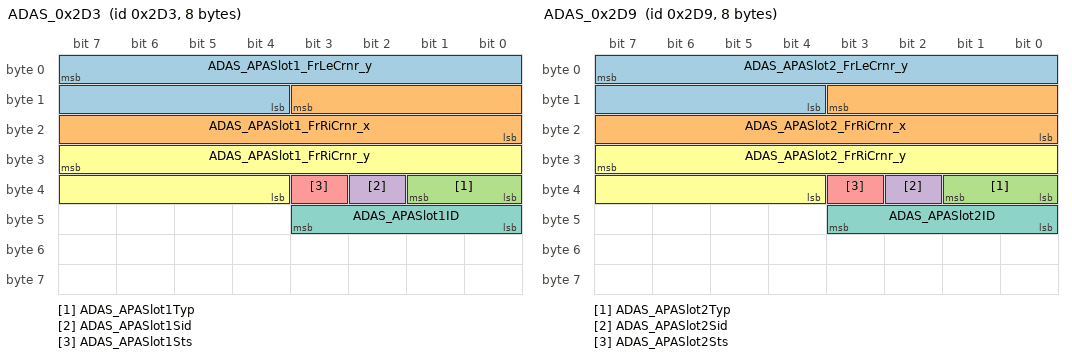
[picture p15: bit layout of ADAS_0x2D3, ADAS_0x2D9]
BO_ 723 ADAS_0x2D3: 8 ADAS
 SG_ ADAS_APASlot1_FrLeCrnr_y : 7|12@0+ (0.05,-100) [-100|100] "m" ICC
 SG_ ADAS_APASlot1_FrRiCrnr_x : 11|12@0+ (0.05,-100) [-100|100] "m" ICC
 SG_ ADAS_APASlot1Typ : 33|2@0+ (1,0) [0|3] "" ICC
 SG_ ADAS_APASlot1Sid : 34|1@0+ (1,0) [0|1] "" ICC
 SG_ ADAS_APASlot1Sts : 35|1@0+ (1,0) [0|1] "" ICC
 SG_ ADAS_APASlot1_FrRiCrnr_y : 31|12@0+ (0.05,-100) [-100|100] "m" ICC
 SG_ ADAS_APASlot1ID : 43|4@0+ (1,0) [0|15] "" ICC

BO_ 726 ADAS_0x2D6: 8 ADAS
 SG_ ADAS_APASlot2_ReLeCrnr_x : 7|12@0+ (0.05,-100) [-100|100] "m" ICC
 SG_ ADAS_APASlot2_ReLeCrnr_y : 11|12@0+ (0.05,-100) [-100|100] "m" ICC
 SG_ ADAS_APASlot2_ReRiCrnr_x : 31|12@0+ (0.05,-100) [-100|100] "m" ICC
 SG_ ADAS_APASlot2_ReRiCrnr_y : 35|12@0+ (0.05,-100) [-100|100] "m" ICC
 SG_ ADAS_APASlot2_FrLeCrnr_x : 55|12@0+ (0.05,-100) [-100|100] "m" ICC

BO_ 729 ADAS_0x2D9: 8 ADAS
 SG_ ADAS_APASlot2_FrLeCrnr_y : 7|12@0+ (0.05,-100) [-100|100] "m" ICC
 SG_ ADAS_APASlot2_FrRiCrnr_x : 11|12@0+ (0.05,-100) [-100|100] "m" ICC
 SG_ ADAS_APASlot2Typ : 33|2@0+ (1,0) [0|3] "" ICC
 SG_ ADAS_APASlot2Sid : 34|1@0+ (1,0) [0|1] "" ICC
 SG_ ADAS_APASlot2Sts : 35|1@0+ (1,0) [0|1] "" ICC
 SG_ ADAS_APASlot2_FrRiCrnr_y : 31|12@0+ (0.05,-100) [-100|100] "m" ICC
 SG_ ADAS_APASlot2ID : 43|4@0+ (1,0) [0|15] "" ICC

BO_ 732 ADAS_0x2DC: 8 ADAS
 SG_ ADAS_APASlot3_ReLeCrnr_x : 7|12@0+ (0.05,-100) [-100|100] "m" ICC
 SG_ ADAS_APASlot3_ReLeCrnr_y : 11|12@0+ (0.05,-100) [-100|100] "m" ICC
 SG_ ADAS_APASlot3_ReRiCrnr_x : 31|12@0+ (0.05,-100) [-100|100] "m" ICC
 SG_ ADAS_APASlot3_ReRiCrnr_y : 35|12@0+ (0.05,-100) [-100|100] "m" ICC
 SG_ ADAS_APASlot3_FrLeCrnr_x : 55|12@0+ (0.05,-100) [-100|100] "m" ICC

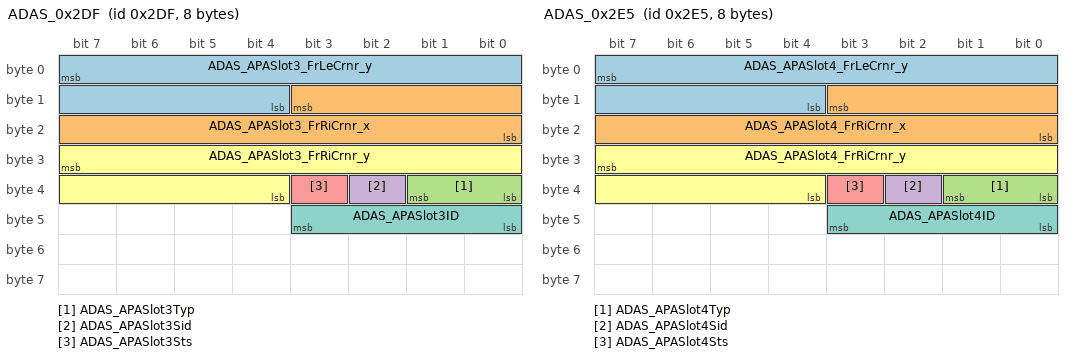
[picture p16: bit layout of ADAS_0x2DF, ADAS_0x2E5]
BO_ 735 ADAS_0x2DF: 8 ADAS
 SG_ ADAS_APASlot3_FrLeCrnr_y : 7|12@0+ (0.05,-100) [-100|100] "m" ICC
 SG_ ADAS_APASlot3_FrRiCrnr_x : 11|12@0+ (0.05,-100) [-100|100] "m" ICC
 SG_ ADAS_APASlot3Typ : 33|2@0+ (1,0) [0|3] "" ICC
 SG_ ADAS_APASlot3Sid : 34|1@0+ (1,0) [0|1] "" ICC
 SG_ ADAS_APASlot3Sts : 35|1@0+ (1,0) [0|1] "" ICC
 SG_ ADAS_APASlot3_FrRiCrnr_y : 31|12@0+ (0.05,-100) [-100|100] "m" ICC
 SG_ ADAS_APASlot3ID : 43|4@0+ (1,0) [0|15] "" ICC

BO_ 738 ADAS_0x2E2: 8 ADAS
 SG_ ADAS_APASlot4_ReLeCrnr_x : 7|12@0+ (0.05,-100) [-100|100] "m" ICC
 SG_ ADAS_APASlot4_ReLeCrnr_y : 11|12@0+ (0.05,-100) [-100|100] "m" ICC
 SG_ ADAS_APASlot4_ReRiCrnr_x : 31|12@0+ (0.05,-100) [-100|100] "m" ICC
 SG_ ADAS_APASlot4_ReRiCrnr_y : 35|12@0+ (0.05,-100) [-100|100] "m" ICC
 SG_ ADAS_APASlot4_FrLeCrnr_x : 55|12@0+ (0.05,-100) [-100|100] "m" ICC

BO_ 741 ADAS_0x2E5: 8 ADAS
 SG_ ADAS_APASlot4_FrLeCrnr_y : 7|12@0+ (0.05,-100) [-100|100] "m" ICC
 SG_ ADAS_APASlot4_FrRiCrnr_x : 11|12@0+ (0.05,-100) [-100|100] "m" ICC
 SG_ ADAS_APASlot4Typ : 33|2@0+ (1,0) [0|3] "" ICC
 SG_ ADAS_APASlot4Sid : 34|1@0+ (1,0) [0|1] "" ICC
 SG_ ADAS_APASlot4Sts : 35|1@0+ (1,0) [0|1] "" ICC
 SG_ ADAS_APASlot4_FrRiCrnr_y : 31|12@0+ (0.05,-100) [-100|100] "m" ICC
 SG_ ADAS_APASlot4ID : 43|4@0+ (1,0) [0|15] "" ICC

BO_ 744 ADAS_0x2E8: 8 ADAS
 SG_ ADAS_APASlot5_ReLeCrnr_x : 7|12@0+ (0.05,-100) [-100|100] "m" ICC
 SG_ ADAS_APASlot5_ReLeCrnr_y : 11|12@0+ (0.05,-100) [-100|100] "m" ICC
 SG_ ADAS_APASlot5_ReRiCrnr_x : 31|12@0+ (0.05,-100) [-100|100] "m" ICC
 SG_ ADAS_APASlot5_ReRiCrnr_y : 35|12@0+ (0.05,-100) [-100|100] "m" ICC
 SG_ ADAS_APASlot5_FrLeCrnr_x : 55|12@0+ (0.05,-100) [-100|100] "m" ICC

BO_ 745 ADAS_0x2E9: 8 ADAS
 SG_ ADAS_APASlot6_ReLeCrnr_x : 7|12@0+ (0.05,-100) [-100|100] "m" ICC
 SG_ ADAS_APASlot6_ReLeCrnr_y : 11|12@0+ (0.05,-100) [-100|100] "m" ICC
 SG_ ADAS_APASlot6_ReRiCrnr_x : 31|12@0+ (0.05,-100) [-100|100] "m" ICC
 SG_ ADAS_APASlot6_ReRiCrnr_y : 35|12@0+ (0.05,-100) [-100|100] "m" ICC
 SG_ ADAS_APASlot6_FrLeCrnr_x : 55|12@0+ (0.05,-100) [-100|100] "m" ICC

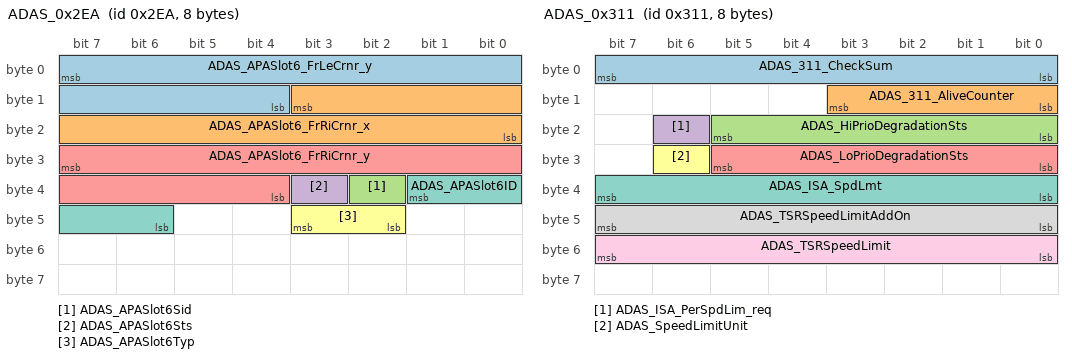
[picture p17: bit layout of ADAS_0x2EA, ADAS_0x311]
BO_ 746 ADAS_0x2EA: 8 ADAS
 SG_ ADAS_APASlot6_FrLeCrnr_y : 7|12@0+ (0.05,-100) [-100|100] "m" ICC
 SG_ ADAS_APASlot6_FrRiCrnr_x : 11|12@0+ (0.05,-100) [-100|100] "m" ICC
 SG_ ADAS_APASlot6Sid : 34|1@0+ (1,0) [0|1] "" ICC
 SG_ ADAS_APASlot6Sts : 35|1@0+ (1,0) [0|1] "" ICC
 SG_ ADAS_APASlot6_FrRiCrnr_y : 31|12@0+ (0.05,-100) [-100|100] "m" ICC
 SG_ ADAS_APASlot6Typ : 43|2@0+ (1,0) [0|3] "" ICC
 SG_ ADAS_APASlot6ID : 33|4@0+ (1,0) [0|15] "" ICC

BO_ 784 CIM_0x310: 8 GW
 SG_ CIM_310_CheckSum : 7|8@0+ (1,0) [0|255] "" ICC
 SG_ CIM_310_AliveCounter : 11|4@0+ (1,0) [0|14] "" ICC
 SG_ CIM_TurnLampSwtSts : 18|3@0+ (1,0) [0|7] "" ICC
 SG_ CIM_HiBeamSwtSts : 20|2@0+ (1,0) [0|3] "" ICC
 SG_ CIM_FrntWshrSwtSts : 22|2@0+ (1,0) [0|3] "" ICC
 SG_ CIM_FrntWiprSwtSts : 26|3@0+ (1,0) [0|7] "" ICC

BO_ 785 ADAS_0x311: 8 ADAS
 SG_ ADAS_311_CheckSum : 7|8@0+ (1,0) [0|255] "" ICC
 SG_ ADAS_311_AliveCounter : 11|4@0+ (1,0) [0|14] "" ICC
 SG_ ADAS_HiPrioDegradationSts : 21|6@0+ (1,0) [0|63] "" ICC
 SG_ ADAS_ISA_PerSpdLim_req : 22|1@0+ (1,0) [0|1] "" ICC
 SG_ ADAS_LoPrioDegradationSts : 29|6@0+ (1,0) [0|63] "" ICC
 SG_ ADAS_SpeedLimitUnit : 30|1@0+ (1,0) [0|1] "" ICC
 SG_ ADAS_ISA_SpdLmt : 39|8@0+ (1,0) [0|255] "kph" ICC
 SG_ ADAS_TSRSpeedLimitAddOn : 47|8@0+ (1,0) [0|255] "" ICC
 SG_ ADAS_TSRSpeedLimit : 55|8@0+ (1,0) [0|255] "" ICC

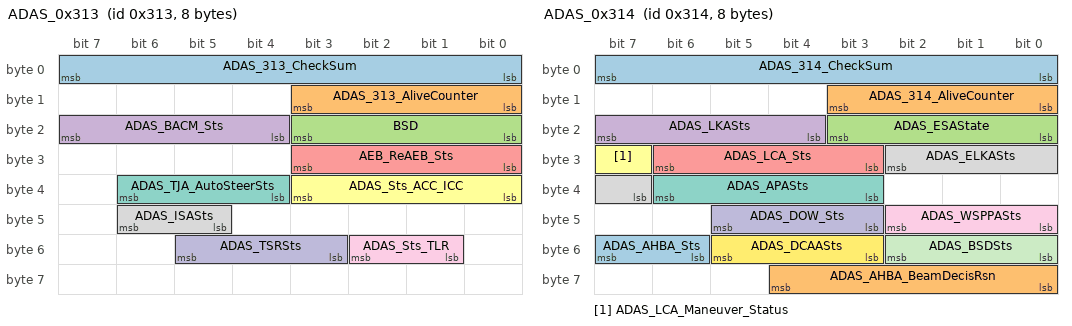
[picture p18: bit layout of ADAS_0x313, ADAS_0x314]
BO_ 787 ADAS_0x313: 8 ADAS
 SG_ ADAS_313_CheckSum : 7|8@0+ (1,0) [0|255] "" ICC
 SG_ ADAS_313_AliveCounter : 11|4@0+ (1,0) [0|14] "" ICC
 SG_ BSD : 19|4@0+ (1,0) [0|15] "" ICC
 SG_ ADAS_BACM_Sts : 23|4@0+ (1,0) [0|15] "" ICC
 SG_ AEB_ReAEB_Sts : 27|4@0+ (1,0) [0|15] "" ICC
 SG_ ADAS_Sts_ACC_ICC : 35|4@0+ (1,0) [0|15] "" ICC
 SG_ ADAS_TJA_AutoSteerSts : 38|3@0+ (1,0) [0|7] "" ICC
 SG_ ADAS_ISASts : 46|2@0+ (1,0) [0|3] "" ICC
 SG_ ADAS_Sts_TLR : 50|2@0+ (1,0) [0|3] "" ICC
 SG_ ADAS_TSRSts : 53|3@0+ (1,0) [0|7] "" ICC

BO_ 788 ADAS_0x314: 8 ADAS
 SG_ ADAS_314_CheckSum : 7|8@0+ (1,0) [0|255] "" ICC
 SG_ ADAS_314_AliveCounter : 11|4@0+ (1,0) [0|14] "" ICC
 SG_ ADAS_ESAState : 19|4@0+ (1,0) [0|15] "" ICC
 SG_ ADAS_LKASts : 23|4@0+ (1,0) [0|15] "" ICC
 SG_ ADAS_LCA_Sts : 30|4@0+ (1,0) [0|15] "" ICC
 SG_ ADAS_LCA_Maneuver_Status : 31|1@0+ (1,0) [0|1] "" ICC
 SG_ ADAS_APASts : 38|4@0+ (1,0) [0|15] "" ICC
 SG_ ADAS_ELKASts : 26|4@0+ (1,0) [0|7] "" ICC
 SG_ ADAS_WSPPASts : 42|3@0+ (1,0) [0|7] "" ICC
 SG_ ADAS_DOW_Sts : 45|3@0+ (1,0) [0|7] "" ICC
 SG_ ADAS_BSDSts : 50|3@0+ (1,0) [0|7] "" ICC
 SG_ ADAS_DCAASts : 53|3@0+ (1,0) [0|7] "" ICC
 SG_ ADAS_AHBA_Sts : 55|2@0+ (1,0) [0|3] "" ICC
 SG_ ADAS_AHBA_BeamDecisRsn : 60|5@0+ (1,0) [0|15] "" ICC

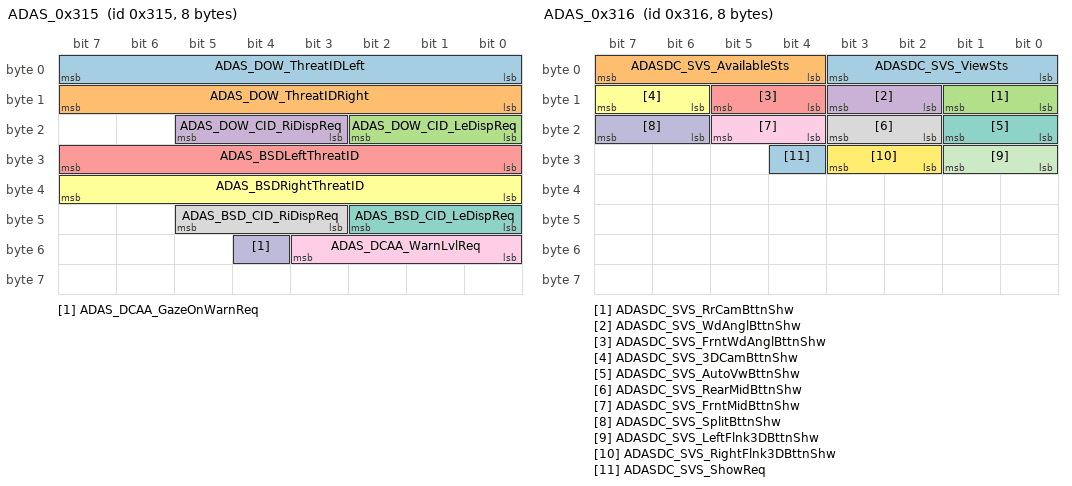
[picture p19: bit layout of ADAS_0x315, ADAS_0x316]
BO_ 789 ADAS_0x315: 8 ADAS
 SG_ ADAS_DOW_ThreatIDLeft : 7|8@0+ (1,0) [0|255] "" ICC
 SG_ ADAS_DOW_ThreatIDRight : 15|8@0+ (1,0) [0|255] "" ICC
 SG_ ADAS_DOW_CID_LeDispReq : 18|3@0+ (1,0) [0|7] "" ICC
 SG_ ADAS_DOW_CID_RiDispReq : 21|3@0+ (1,0) [0|7] "" ICC
 SG_ ADAS_BSDLeftThreatID : 31|8@0+ (1,0) [0|255] "" ICC
 SG_ ADAS_BSDRightThreatID : 39|8@0+ (1,0) [0|255] "" ICC
 SG_ ADAS_BSD_CID_LeDispReq : 42|3@0+ (1,0) [0|7] "" ICC
 SG_ ADAS_BSD_CID_RiDispReq : 45|3@0+ (1,0) [0|7] "" ICC
 SG_ ADAS_DCAA_WarnLvlReq : 51|4@0+ (1,0) [0|15] "" ICC
 SG_ ADAS_DCAA_GazeOnWarnReq : 52|1@0+ (1,0) [0|1] "" ICC

BO_ 790 ADAS_0x316: 8 ADAS
 SG_ ADASDC_SVS_ViewSts : 3|4@0+ (1,0) [0|15] "" ICC
 SG_ ADASDC_SVS_AvailableSts : 7|4@0+ (1,0) [0|15] "" ICC
 SG_ ADASDC_SVS_RrCamBttnShw : 9|2@0+ (1,0) [0|1] "" ICC
 SG_ ADASDC_SVS_WdAnglBttnShw : 11|2@0+ (1,0) [0|1] "" ICC
 SG_ ADASDC_SVS_FrntWdAnglBttnShw : 13|2@0+ (1,0) [0|1] "" ICC
 SG_ ADASDC_SVS_3DCamBttnShw : 15|2@0+ (1,0) [0|1] "" ICC
 SG_ ADASDC_SVS_AutoVwBttnShw : 17|2@0+ (1,0) [0|1] "" ICC
 SG_ ADASDC_SVS_RearMidBttnShw : 19|2@0+ (1,0) [0|1] "" ICC
 SG_ ADASDC_SVS_FrntMidBttnShw : 21|2@0+ (1,0) [0|1] "" ICC
 SG_ ADASDC_SVS_SplitBttnShw : 23|2@0+ (1,0) [0|1] "" ICC
 SG_ ADASDC_SVS_LeftFlnk3DBttnShw : 25|2@0+ (1,0) [0|1] "" ICC
 SG_ ADASDC_SVS_RightFlnk3DBttnShw : 27|2@0+ (1,0) [0|1] "" ICC
 SG_ ADASDC_SVS_ShowReq : 28|1@0+ (1,0) [0|1] "" ICC

CM_ SG_ 1141 EPS_PwrSplyOverVoltFlt "High fault of EPS supply voltage_C20C917_Voltage High Error.";
CM_ SG_ 1141 EPS_PwrSplyUnderVoltFlt "Low fault of EPS supply voltage_C20CA16_Voltage Low Error.";
CM_ SG_ 1141 EPS_SnsrSplyVoltFlt "EPS sensor power supply voltage faulty_C20CB01_C20CC01_Sensor Supply Voltage Error.";
CM_ SG_ 1141 EPS_MotShoOpenFlt "EPS motor short circuit or open fault_C20D196_C20D201_Motor Short or Open Error.";
CM_ SG_ 1141 EPS_ThermProtnFlt "EPS thermal protection fail_C20D698_EPS Thermal Protection Error.";
CM_ SG_ 1141 EPS_NVMFlt "EPS nonvolatile memory faulty_C20D804_NVM Error.";
CM_ SG_ 1141 EPS_RunngRstFlt "EPS operation reset faila_C20D901_Running Reset Error.";
CM_ SG_ 1141 EPS_ModSts "EPS mode status";
CM_ BO_ 1141 "IBUS1, cyclic every 100 ms, sent by GW";
CM_ SG_ 1170 PKC_UsrID "User ID";
CM_ BO_ 1170 "IBUS1, cyclic every 100 ms, sent by GW";
CM_ SG_ 1264 PKC_RemCtrlWinCmd "Remote window regulator command";
CM_ SG_ 1264 PKC_PollingSts "Polling state (PKC)";
CM_ SG_ 1264 PKC_PollingFctCmd "Polling function command";
CM_ SG_ 1264 PKC_KeyLocation "The phone key is outside the vehicle";
CM_ SG_ 1264 PKC_UsrStopCharCmd "Mobile user termination charging request";
CM_ SG_ 1264 PKC_SpdLim "Signal which set the speed limit on ICC";
CM_ SG_ 1264 PKC_RemClsSunroofCtrlCmd "sunroof control via PKC in percentage";
CM_ BO_ 1264 "IBUS1, CE every 100 ms, sent by GW";
CM_ SG_ 1265 DSMC_DrvrSeatTrackSwtSts "State of the driver seat slide switch";
CM_ SG_ 1265 DSMC_DrvrSeatHeiAdjSwtSts "Driver seat height adjustment switch state";
CM_ SG_ 1265 DSMC_DrvrSeatBackAdjSwtSts "State of driver's seat backrest adjustment switch";
CM_ SG_ 1265 DSMC_OTARdy_Fb "DSMC OTA ready status feedback";
CM_ BO_ 1265 "IBUS1, cyclic every 100 ms, sent by GW";
CM_ SG_ 1267 DSMC_RiMirrrXDiecPosn "Position of right rearview mirror inxdirection";
CM_ SG_ 1267 DSMC_RiMirrrYDircPosn "Position of right rearview mirror in Y direction";
CM_ SG_ 1267 DSMC_LeMirrrXPosn "Position of left rearview mirror inxdirection";
CM_ SG_ 1267 DSMC_LeMirrrYPosn "Left rearview mirror Y direction position";
CM_ SG_ 1267 DSMC_RiMirrrXDircAdjSts "Adjustment state of right rearview mirror inxdirection";
CM_ SG_ 1267 DSMC_RiMirrrYDircAdjSts "Adjustment state of right rearview mirror in Y direction";
CM_ SG_ 1267 DSMC_LeMirrrXDircAdjSts "Adjustment state of left rearview mirror inxdirection";
CM_ SG_ 1267 DSMC_LeMirrrYDircAdjSts "Adjustment state of left rearview mirror in Y direction";
CM_ BO_ 1267 "IBUS1, cyclic every 100 ms, sent by GW";
CM_ SG_ 1269 DSMC_DrvrSeatTrackPosn "Driver seat slide position";
CM_ SG_ 1269 DSMC_DrvrSeatHeiPosn "Driver seat height position";
CM_ SG_ 1269 DSMC_DrvrSeatBackPosn "Driver's seat backrest position";
CM_ BO_ 1269 "IBUS1, cyclic every 100 ms, sent by GW";
CM_ SG_ 1272 TBOX_4F4_4F8_CheckSum "TBOX_4F8_message checksum ( E2E data ID:0xC2 )";
CM_ SG_ 1272 TBOX_4F4_4F8_AliveCounter "TBOX_4F8_message counter";
CM_ SG_ 1272 TBOX_Flsflg "TBOX Flash flag";
CM_ SG_ 1272 TBOX_FobdGWPartBUSUDSCom "Forbidden UDS communication of some network segments of GW";
CM_ SG_ 1272 TBOX_RemChrgInsulFctReq "Remote charging insulation function request";
CM_ SG_ 1272 TBOX_EHUSetTrvlMod "TBOX Setup Travel Mode";
CM_ SG_ 1272 TBOX_ResvACChrgOpenSts "TBOX reservation AC charging on state";
CM_ SG_ 1272 TBOX_RemKL15PwrOnReq "TBOX remote KL15 power-on request";
CM_ SG_ 1272 TBOX_SetChrgEndSOC "TBOX Set charge cut-off SOC value";
CM_ SG_ 1272 TBOX_PreCondTriggerReq "TBOX sends a trigger [PreCondTrigger] to start pre-conditioning to VCU";
CM_ SG_ 1272 TBOX_BlowLvlReq "TBOX send blowlevel to ECC";
CM_ SG_ 1272 TBOX_VehiMod "Vehicle Mode(TBD)";
CM_ SG_ 1272 TBOX_Crash_cfm "Crash comfirm signal from TBOX to ESP.";
CM_ SG_ 1272 TBOX_SchedChrgnReq "TBOX send the Scheduled Charging Request to VCU";
CM_ BO_ 1272 "IBUS1, CE every 100 ms, sent by GW";
CM_ SG_ 1273 TBOX_OTAResFb "OTA flash finished result feedback";
CM_ SG_ 1273 TBOX_SpdLim "Signal which set the speed limit on ICC";
CM_ SG_ 1273 TBOX_OTA_TiRng "TBOX OTA flash Time range to ICC";
CM_ BO_ 1273 "IBUS1, cyclic every 200 ms, sent by GW";
CM_ SG_ 1287 VCU_OTAVehInhb_QM_Fb "QM group OTA vehicle Inhibit feedback";
CM_ SG_ 1287 VCU_OTAVehCdnChk_QM_sts "QM group OTA vehicle condition check status";
CM_ SG_ 1287 VCU_DrvAvl "Driving effective";
CM_ SG_ 1287 VCU_CllsnSigSts "Impact signal state_P103C00_E03";
CM_ SG_ 1287 VCU_VehSts_GB "Vehicle state (national standard)";
CM_ SG_ 1287 VCU_MCUOverTFlt_GB "MCU over-temperature fault (national standard)";
CM_ SG_ 1287 VCU_DrvrMotOverTFlt_GB "Over temperature fault of driving motor (national standard)";
CM_ SG_ 1287 VCU_SOCTooLoAlrm "Alarm if SOC is too low_P101221_E00";
CM_ SG_ 1287 VCU_SOCJumpAlrm "SOC jump alarming_P101327_E00";
CM_ SG_ 1287 VCU_PwrBattPackMismatAlrm "Power pack mismatch alarming_P101101_E00";
CM_ SG_ 1287 VCU_SOCTooHiAlrm "Overhigh SOC alarm_P101222_E00";
CM_ SG_ 1287 VCU_DCDCEnaCmd "DCDC Enable Command";
CM_ SG_ 1287 VCU_PwrBattECCEnaCmd "Power battery air conditioning system enable command";
CM_ SG_ 1287 VCU_MstRlyCtrlCmd "VCU main relay control command";
CM_ SG_ 1287 VCU_DCDCOutpVoltCmd "DCDC output voltage command";
CM_ SG_ 1287 VCU_CCCnctnVolt "CC connection voltage value";
CM_ SG_ 1287 VCU_GearSig_GB "Gear signal (national standard)";
CM_ SG_ 1287 VCU_DrvrMotNr_GB "Number of driving motors (national standard)";
CM_ SG_ 1287 VCU_BattVolt "Battery voltage";
CM_ BO_ 1287 "IBUS1, cyclic every 100 ms, sent by GW";
CM_ SG_ 1298 PSM_PassSeatHeatgSts "Heating state of front passenger seat";
CM_ SG_ 1298 PSM_PassSeatVentnSts "Passenger Seat Fan State";
CM_ SG_ 1298 PSM_PassSeatTrackAdjSts "Adjustment state of passenger seat slide";
CM_ SG_ 1298 PSM_PassSeatBackAdjSts "Adjustment state of front passenger seat backrest";
CM_ SG_ 1298 PSM_OTARdy_Fb "PSM OTA ready status feedback";
CM_ BO_ 1298 "IBUS1, cyclic every 100 ms, sent by GW";
CM_ SG_ 1300 MFS_0x514_CheckSum "MFS_0x514_Message check (0xC5)_CheckSum";
CM_ SG_ 1300 MFS_0x514_AliveCounter "MFS_0x514_Message counterAliveCounter";
CM_ SG_ 1300 MFS_LeRollUp "Left roller (up)";
CM_ SG_ 1300 MFS_LeRollDwn "Left roller (roll-down)";
CM_ SG_ 1300 MFS_LeRollPress "Left roller (pressed)- Mute(press)";
CM_ SG_ 1300 MFS_RiBtnNorth "ACC on/off";
CM_ SG_ 1300 MFS_RiRollUp "Right roller (top rolling)";
CM_ SG_ 1300 MFS_RiRollDwn "Right roller (roll-down)";
CM_ SG_ 1300 MFS_RiRollPress "Right roller (pressed-OK,Confirm(press)";
CM_ SG_ 1300 MFS_Ri_Fail "Button Failure right buttons";
CM_ SG_ 1300 MFS_Le_Fail "Button Failure left buttons";
CM_ BO_ 1300 "IBUS1, cyclic every 50 ms, sent by MFSS";
CM_ SG_ 1304 DSMC_DrvrSeatHeatgSts "Driver's seat heating status";
CM_ SG_ 1304 DSMC_DrvrSeatTrackAdjSts "Driver seat slide adjustment state";
CM_ SG_ 1304 DSMC_DrvrSeatHeiAdjSts "Driver seat height adjustment state";
CM_ SG_ 1304 DSMC_DrvrSeatBackAdjSts "Driver seat backrest adjustment state";
CM_ SG_ 1304 DSMC_RearLeSeatHeatgSts "Rear seat heating status_Left";
CM_ SG_ 1304 DSMC_RearRiSeatHeatgSts "Rear seat heating status_Right";
CM_ BO_ 1304 "IBUS1, cyclic every 100 ms, sent by GW";
CM_ SG_ 1310 BCM_ActvModDiEna "Active mode disable enable bit";
CM_ SG_ 1310 BCM_ApplianceClsLvl "Electrical appliance closing level";
CM_ SG_ 1310 BCM_RainSnsrSysFlt "Rain sensor system fault";
CM_ SG_ 1310 BCM_SolarSnsrSysFlt "Sunlight sensor system fault";
CM_ SG_ 1310 BCM_FogSnsrSysFlt "Humidity sensor system fault";
CM_ SG_ 1310 BCM_LightSnsrHwFlt_RLS "Error status light sensorLight sensor hardware fault";
CM_ SG_ 1310 BCM_SolarSnsrHwFlt_RLS "Error status solar sensorSunlight sensor hardware fault";
CM_ SG_ 1310 BCM_GlassSurfaceOcclusion "Shield degree of glass surface";
CM_ BO_ 1310 "IBUS1, cyclic every 100 ms, sent by GW";
CM_ SG_ 1314 DSMC_IninSts "DSMC initialization state";
CM_ SG_ 1314 DSMC_CrtSts "Current status of DSMC";
CM_ SG_ 1314 DSMC_SteerWhlYSts "Y-axis state of steering wheel column";
CM_ SG_ 1314 DSMC_SteerWhlZSts "Z-axis state of steering wheel column";
CM_ SG_ 1314 DSMC_SteerWhlYDirPosn "Y direction of the steering wheel column";
CM_ SG_ 1314 DSMC_SteerWhlZDirPosn "Z direction of the steering wheel column";
CM_ BO_ 1314 "IBUS1, CE every 100 ms, sent by GW";
CM_ SG_ 1315 PWC_R_ChrgSts "Charging state";
CM_ SG_ 1315 PWC_R_PhnForgetRemdSts "Mobile phone forgetting reminder state";
CM_ SG_ 1315 PWC_R_ModleSwtSts "Module switch status";
CM_ SG_ 1315 PWC_R_ChrgPhnChkSts "Detection state of rechargeable mobile phone";
CM_ BO_ 1315 "IBUS1, cyclic every 100 ms, sent by PWC_R";
CM_ SG_ 1316 PWC_ChrgSts "Charging state";
CM_ SG_ 1316 PWC_PhnForgetRemdSts "Mobile phone forgetting reminder state";
CM_ SG_ 1316 PWC_ModleSwtSts "Module switch status";
CM_ SG_ 1316 PWC_ChrgPhnChkSts "Detection state of rechargeable mobile phone";
CM_ BO_ 1316 "IBUS1, cyclic every 100 ms, sent by PWC_L";
CM_ SG_ 1320 ICC_DrvrSeatHeatgReq "Driver seat heating requestSeat heating request on driver seatValues:Off/Low/Medium/High.";
CM_ SG_ 1320 ICC_RearLeSeatHeatgSync "Rear seat heating diplay from ICC to RAC for Display synchronisation";
CM_ SG_ 1320 ICC_DrvrID "Driver IDDriver memory postion request for 1 out 10 saved memory positionsValues:No request/Mem1/Mem2/?. /Mem10/Recall1/Recall2/? /Recall11.";
CM_ SG_ 1320 ICC_SeatWelFctEnaReq "Seat courtesy function enable requestUnactive/Active.";
CM_ SG_ 1320 ICC_DrvAntithiefEnaReq "Driver Seat Anti-theft Function Enabling RequestUnactive/Active.";
CM_ SG_ 1320 ICC_RearRiSeatHeatgSync "Rear seat heating diplay from ICC to RAC for Display synchronisation";
CM_ SG_ 1320 ICC_SWH_Req "SWH on/off request";
CM_ SG_ 1320 ICC_PassSeatHeatgReq "Front passenger seat heating requestSeat heating request on Panssenger seatValues:Off/Low/Medium/High.";
CM_ SG_ 1320 ICC_RearLeSeatHeatgReq "Rear seat heating request_Left";
CM_ SG_ 1320 ICC_KL15PwrOffPrevFlag "ICC will sent an active flag as long as Entertainment Mode, Pet Mode, Karaoke Mode or Camping Mode is activated";
CM_ SG_ 1320 ICC_RearRiSeatHeatgReq "Rear seat heating request_Right";
CM_ BO_ 1320 "IBUS1, cyclic every 100 ms, sent by ICC";
CM_ SG_ 1321 ICC_CtrlSts_NFC "NFC state switch";
CM_ SG_ 1321 ICC_CtrlSts_PWC "Wireless charge state switch";
CM_ SG_ 1321 ICC_DispUnit "meters display units";
CM_ SG_ 1321 ICC_SteerWhlPhnKeyBackLi "Steering wheel phone button backlight";
CM_ SG_ 1321 ICC_BackgndBriLvl "Brightness level of background lightLight intensity level.";
CM_ SG_ 1321 ICC_TempUnit "Temperature Unit Setting";
CM_ SG_ 1321 ICC_V2G_Ena "ICC_V2GEnable";
CM_ SG_ 1321 ICC_V2H_Ena "ICC_V2HEnable";
CM_ SG_ 1321 ICC_V2V_Ena "ICC_V2VEnable";
CM_ SG_ 1321 ICC_V2L_ChrgPortEna "ICC_V2LChargePortEnable";
CM_ SG_ 1321 ICC_V2L_TrEna "ICC_V2LTrunkEnable";
CM_ SG_ 1321 ICC_ReOperPanLockCmd "Rear operating panel locking instruction";
CM_ SG_ 1321 ICC_RollingCounter "Rolling counter";
CM_ SG_ 1321 ICC_WiprSrvPosn "Wiper service location";
CM_ SG_ 1321 ICC_SpclTerrainModReq "ICC all terrain driving mode request";
CM_ SG_ 1321 ICC_NavOnSts "Navigation ON state";
CM_ SG_ 1321 ICC_DoorCtrlSwtSts "Door control switch state";
CM_ SG_ 1321 ICC_CrtLanguage "ICC current language";
CM_ SG_ 1321 ICC_NavBarShift "Navigation bar gear value";
CM_ BO_ 1321 "IBUS1, cyclic every 100 ms, sent by ICC";
CM_ SG_ 1328 ICC_DrvrTSet "Main driving temperature setting";
CM_ SG_ 1328 ICC_PassTSet "Temperature setting of front passenger";
CM_ SG_ 1328 ICC_VSPVoiceTypSwt "VSP sound type switching switch";
CM_ SG_ 1328 ICC_ECCAUTOReq "Air conditioning AUTO request";
CM_ SG_ 1328 ICC_DrvrSYNCReq "Driver SYNC request";
CM_ SG_ 1328 ICC_ACSwtReq "A/C switch request";
CM_ SG_ 1328 ICC_AirVolSet "Air volume setting";
CM_ SG_ 1328 ICC_ECCIntExtCircReq "Requirement of A/C interior/exterior circulation";
CM_ SG_ 1328 ICC_AirClnSwtReq "Air purification switch request";
CM_ SG_ 1328 ICC_MaxFrntDefrstSet "MaxFront defroster setting";
CM_ SG_ 1328 ICC_VSPCtrlCmd "VSP control instruction";
CM_ SG_ 1328 ICC_NavCtryCod "Navigation-country code";
CM_ SG_ 1328 ICC_NavRoadTyp "Navigation-road typeRoad type from navigation.";
CM_ SG_ 1328 ICC_NavSpdLimUnit "Navigation-speed limit unitSpeed limit unit from naviation.";
CM_ SG_ 1328 ICC_NavSpdLimSts "Navigation-Speed limit stateNavigation state.";
CM_ SG_ 1328 ICC_NavSpdLim "Navigation-speed limitSpeed limit from navigation.";
CM_ SG_ 1328 ICC_BlowWinBtn "Window blowing button";
CM_ SG_ 1328 ICC_NavSpdLimExitDst "Navigation-Speed limit exit distance";
CM_ BO_ 1328 "IBUS1, NoMsgSendType, sent by ICC";
CM_ SG_ 1329 ICC_TotMilgVld_ODO "Effective bit of ODO total mileage";
CM_ SG_ 1329 ICC_TotMilg_ODO "ODO total mileage";
CM_ SG_ 1329 ICC_DispVehSpd "Display speed";
CM_ SG_ 1329 ICC_DispVehSpdUnit "Display vehicle speed unit";
CM_ SG_ 1329 ICC_ADASSigFlt "Instrument ADAS signal fault";
CM_ SG_ 1329 ICC_DispFlt "Instrument display failure";
CM_ SG_ 1329 ICC_WorkshopMode "Setting by customer over display before he wants to tow the vehicle (=Rescue (Workshop Mode)";
CM_ BO_ 1329 "IBUS1, cyclic every 100 ms, sent by ICC";
CM_ SG_ 1330 ICC_MilgOffs_ODO "Mileage offset";
CM_ SG_ 1330 ICC_DispTotMilg_ODO "Display total mileage";
CM_ SG_ 1330 ICC_MilgDataVld_ODO "Mileage effective signal";
CM_ SG_ 1330 ICC_MilgRstCntr_ODO "Mileage clearing times";
CM_ BO_ 1330 "IBUS1, cyclic every 100 ms, sent by ICC";
CM_ SG_ 1331 ICC_DrvrSeatTrackManReq "Front and rear adjustment request of driver's seatDriver seat track manual movement directionValues:Off/Fwd/Rwd.";
CM_ SG_ 1331 ICC_DrvrSeatTiltManReq "Driver's seat cushion angle adjustment requestDriver seat tilt manual movement directionValues:Off/Up/Down.";
CM_ SG_ 1331 ICC_DrvrHeiManReq "Driver seat height adjustment requestDriver seat height manual movement directionValues:Off/Up/Down.";
CM_ SG_ 1331 ICC_DrvrSeatBackManReq "Adjustment of driver's seat backrestDriver seat recliner manual movement directionValues:Off/Up/Down.";
CM_ SG_ 1331 ICC_PassSeatTrackManReq "Front passenger seat forward and backward adjustment requestPanssenger seat track manual movement directionValues:Off/Fwd/Rwd.";
CM_ SG_ 1331 ICC_PassSeatBackManReq "Adjustment of front passenger seat backrestPanssenger seat recliner manual movement directionValues:Off/Up/Down.";
CM_ SG_ 1331 ICC_LumbarUpd "Lumbar support up adjustment";
CM_ SG_ 1331 ICC_LumbarDwn "Lumbar support downwards adjustment";
CM_ SG_ 1331 ICC_LumbarFwd "Forward lumbar support adjustment";
CM_ SG_ 1331 ICC_LumbarBackw "Backward adjustment of lumbar support";
CM_ SG_ 1331 ICC_AutoPassSeatVentnEna "The automatic ventilation function of the front passenger seat is enabled";
CM_ SG_ 1331 ICC_AutoPassSeatHeatEna "The automatic heating function of the front passenger seat is enabled";
CM_ SG_ 1331 ICC_AutoDrvrSeatVentnEna "The automatic ventilation function of the driver's seat is enabled";
CM_ SG_ 1331 ICC_AutoDrvrSeatHeatEna "The automatic heating function of the driver's seat is enabled";
CM_ BO_ 1331 "IBUS1, cyclic every 100 ms, sent by ICC";
CM_ SG_ 1332 ICC_MinChrgSoc_Setting "Minimum SOC setting value for scheduled charging.";
CM_ SG_ 1332 ICC_PwrBattDrvgHeatSwtSts "State of traction battery on-board heating function switch";
CM_ SG_ 1332 ICC_DrvrBlowFaceBtn "Face-blowing button of driver";
CM_ SG_ 1332 ICC_PassBlowFacetBtn "Face-blowing button of front passenger";
CM_ SG_ 1332 ICC_DrvrBlowFootBtn "Feet-blowing button of driver";
CM_ SG_ 1332 ICC_PassBlowFootBtn "Front passenger foot-blowing button";
CM_ SG_ 1332 ICC_BackRowAirOutlModReq "Rear exhaust mode request";
CM_ SG_ 1332 ICC_DchaBtnAvlFlg "Effective flag bit of discharge button";
CM_ SG_ 1332 ICC_ECCSysSwtCmd "Air conditioning system switch instruction";
CM_ SG_ 1332 ICC_DrvrBlowModReq "Voice driver blowing mode request";
CM_ SG_ 1332 ICC_PassBlowModReq "Voice front passenger blowing mode request";
CM_ BO_ 1332 "IBUS1, NoMsgSendType, sent by ICC";
CM_ SG_ 1364 VCU_PwrGridBreakFlg "Grid outage flag bit";
CM_ SG_ 1364 VCU_ACChrgDchaIndcrLampSts "AC charge and discharge indicator state";
CM_ SG_ 1364 VCU_VCUWakeUpSig "VCU wake-up CCU signal";
CM_ SG_ 1364 VCU_DCChrgDchaIndcrLampSts "DC charging indicator state";
CM_ SG_ 1364 VCU_PrplsnEPwrReq "Propulsion power request (pos&negative)";
CM_ SG_ 1364 VCU_HVBattActPwr "HV battery in/out total actual power (- for discharge, + for charge)";
CM_ SG_ 1364 VCU_PreCdnTi1 "pre-conditioning time t1";
CM_ SG_ 1364 VCU_PreCdnTi2 "pre-conditioning time t2";
CM_ BO_ 1364 "IBUS1, cyclic every 100 ms, sent by GW";
CM_ SG_ 1379 ICC_0x563_CheckSum "ICC_0x563_Message Verification (0x65)ICC_0x563_CheckSum";
CM_ SG_ 1379 ICC_0x563_AliveCounter "ICC_0x563_AliveCounter";
CM_ SG_ 1379 ICC_CID_Pos_Learn "ICC_CID_Pos_Learn";
CM_ SG_ 1379 ICC_CID_Command_Valid "ICC_CID_Command_Valid";
CM_ SG_ 1379 ICC_CID_Target_Position "ICC_CID_Target_Position";
CM_ SG_ 1379 ICC_CID_Rot_Speed "ICC_CID_Rot_Speed";
CM_ BO_ 1379 "IBUS1, cyclic every 200 ms, sent by ICC";
CM_ SG_ 1400 VCU_NotChrgModECCCnseEgy "Energy consumption of A/C in the passenger compartment in non-charging mode";
CM_ SG_ 1400 VCU_NotChrgModVehDrvCnseEgy "Energy consumption of vehicle driving in non-charging mode";
CM_ SG_ 1400 VCU_NotChrgModBHMCnseEgy "Energy consumption of battery thermal management in non-charging mode";
CM_ SG_ 1400 VCU_NotChrgModExtDchaCnseEgy "Energy consumption of battery thermal management in non-charging mode";
CM_ BO_ 1400 "IBUS1, cyclic every 500 ms, sent by GW";
CM_ SG_ 1401 VCU_NotChrgModAcsyCnseEgy "Energy consumption of accessories in non-charging mode";
CM_ SG_ 1401 VCU_NotChrgModVehTotCnseEgy "Total energy consumption of vehicle in non-charging mode";
CM_ SG_ 1401 VCU_ChrgModECCCnseEgy "Energy consumption of A/C in the passenger compartment in charging mode";
CM_ SG_ 1401 VCU_ChrgModVehChrgEgy "Vehicle charging energy in charging mode";
CM_ BO_ 1401 "IBUS1, cyclic every 500 ms, sent by GW";
CM_ SG_ 1402 VCU_ChrgModBattHeatgMngCnseEgy "Energy consumption of battery thermal management in charging mode";
CM_ SG_ 1402 VCU_ChrgModAcsyCnseEgy "Energy consumption of accessories in charging mode";
CM_ SG_ 1402 VCU_ChrgModChrgEffCnseEgy "Charging efficiency energy loss in charging mode";
CM_ SG_ 1402 VCU_ChrgModVehTotChrgEgy "Total charging energy of vehicle in charging mode";
CM_ BO_ 1402 "IBUS1, cyclic every 500 ms, sent by GW";
CM_ SG_ 1403 VCU_NotChrgModECCCnseEgyPerc "Percentage of energy consumption of the A/C in the passenger compartment in the non-charging mode";
CM_ SG_ 1403 VCU_NotChrgModVehDrvCnseEgyPerc "Percentage of energy consumption in non-charging mode";
CM_ SG_ 1403 VCU_NotChrgModBHMCnseEgyPerc "Percentage energy consumption of battery thermal management in non-charging mode";
CM_ SG_ 1403 VCU_NotChrgModExtDchaCnseEgyPerc "Percentage of energy consumption of external discharge in non-charge mode";
CM_ SG_ 1403 VCU_NotChrgModAcsyCnseEgyPerc "Percentage energy consumption of accessories in non-charging mode";
CM_ BO_ 1403 "IBUS1, cyclic every 500 ms, sent by GW";
CM_ SG_ 1404 VCU_ChrgModECCCnseEgyPerc "Percentage of energy consumption of A/C in passenger compartment in charging mode";
CM_ SG_ 1404 VCU_ChrgModVehChrgEgyPerc "Percentage of charging energy in charging mode";
CM_ SG_ 1404 VCU_ChrgModBHMCnseEgyPerc "Percentage energy consumption of battery thermal management in charging mode";
CM_ SG_ 1404 VCU_ChrgModAcsyCnseEgyPerc "Percentage energy consumption of accessories in charging mode";
CM_ SG_ 1404 VCU_ActEgyCnsTyp "Energy consumption visualization type, discriminated by vehicle speed, FB208";
CM_ SG_ 1404 VCU_ChrgModChrgEffCnseEgyPerc "Percentage energy loss at charging efficiency in charging mode";
CM_ BO_ 1404 "IBUS1, cyclic every 500 ms, sent by GW";
CM_ SG_ 1413 FloatingButtons_585_CheckSum "FloatingButtons Buttons_0x585_Message Verification (0x68)FloatingButtons Buttons_0x585_CheckSum";
CM_ SG_ 1413 FloatingButtons_585_AliveCounter "FloatingButtons Buttons_0x585_AliveCounter";
CM_ SG_ 1413 FloatingButtons_LeT "TDS_Left_temp";
CM_ SG_ 1413 FloatingButtons_LEDsFail1 "TDS_Failure1_LEDs";
CM_ SG_ 1413 FloatingButtons_RiT "TDS_Right_temp";
CM_ SG_ 1413 FloatingButtons_FanCtrl "TDS_Fan_Control";
CM_ SG_ 1413 FloatingButtons_ButnsFail2 "TDS_Failure2_Buttons";
CM_ SG_ 1413 FloatingButtons_HomeButnFail3 "TDS_Failure3_HomeButton";
CM_ SG_ 1413 FloatingButtons_VolCtrl "TDS_Volume_Control";
CM_ SG_ 1413 FloatingButtons_HomeCtrl "TDS_Home_Control";
CM_ BO_ 1413 "IBUS1, cyclic every 50 ms, sent by FloatingButtons";
CM_ SG_ 1415 Rotator_0x587_CheckSum "Rotator_0x587_Message Verification (0x6C)Rotator_0x587_CheckSum";
CM_ SG_ 1415 Rotator_0x587_AliveCounter "Rotator_0x587_AliveCounter";
CM_ SG_ 1415 Rotator_ECUSts "CID_ECU_status";
CM_ SG_ 1415 Rotator_PosVld "CID_Pos_valid";
CM_ SG_ 1415 Rotator_PosSts "CID_Pos_status";
CM_ SG_ 1415 Rotator_Pos_rotator "CID_Pos_rotator";
CM_ SG_ 1415 Rotator_OpticSnsrFlt "Optical Sensor Fail A/B";
CM_ SG_ 1415 Rotator_HallSnsrFlt "Hall Sensor Fail A/B";
CM_ BO_ 1415 "IBUS1, CE every 200 ms, sent by Rotator";
CM_ SG_ 1416 VSP_SwtInpIndcrLampSts "VSP-OFF switch output indicator statusVSP-OFF switch indicator status.";
CM_ SG_ 1416 VSP_SwtOutpSts "VSP-OFF switch input stateVSP_OFF switch output status.";
CM_ SG_ 1416 VSP_WngSts "VSP operating stateVSP working status.";
CM_ SG_ 1416 VSP_VoiceTypFb "VSP sound type feedback";
CM_ SG_ 1416 VSP_HornWngSts "VSP horn working stateVSP speaker working status.";
CM_ SG_ 1416 VSP_WngMod "VSP operating modeVSP working mode.";
CM_ SG_ 1416 VSP_OTARdy_Fb "VSP OTA ready status feedback";
CM_ BO_ 1416 "IBUS1, cyclic every 500 ms, sent by GW";
CM_ SG_ 1450 TBOX_Wifi_ConnectSts "Signal from TBOX to ICC to indicate connection status-Connection successful - Yes/No";
CM_ SG_ 1450 TBOX_Wifi_ConnectStrgthSts "Signal from TBOX to ICC to indicate connection status-Signal strength - RSSI indication";
CM_ BO_ 1450 "IBUS1, NoMsgSendType, sent by GW";
CM_ SG_ 1456 TBOX_Wifi_Net_NameID "Character 7(ASCII)";
CM_ SG_ 1456 TBOX_Wifi_Net_TotalMsgs "Total number of messages.? Signals from TBOX to ICC to indicate available Wifi networks as a list of null terminated strings";
CM_ SG_ 1456 TBOX_Wifi_Net_CurrentMsgNm "Current number of messages. ?; CM_ SG_ 1456 TBOX_Wifi_Net_Character_1 Character 1(ASCII)";
CM_ SG_ 1456 TBOX_Wifi_Net_Character_2 "Character 2(ASCII)";
CM_ SG_ 1456 TBOX_Wifi_Net_Character_3 "Character 3(ASCII)";
CM_ SG_ 1456 TBOX_Wifi_Net_Character_4 "Character 4(ASCII)";
CM_ SG_ 1456 TBOX_Wifi_Net_Character_5 "Character 5(ASCII)";
CM_ SG_ 1456 TBOX_Wifi_Net_Character_6 "Character 6(ASCII)";
CM_ BO_ 1456 "IBUS1, NoMsgSendType, sent by GW";
CM_ SG_ 1461 ICC_Wifi_SSID_TotalMsgs "Total number of messages.? Signal from ICC to TBOX to communicate user selected SSID as a null terminated string.";
CM_ SG_ 1461 ICC_Wifi_SSID_CurrentMsgNm "Current number of messages. ?; CM_ SG_ 1461 ICC_Wifi_SSID_Character_1 Character 1(ASCII)";
CM_ SG_ 1461 ICC_Wifi_SSID_Character_2 "Character 2(ASCII)";
CM_ SG_ 1461 ICC_Wifi_SSID_Character_3 "Character 3(ASCII)";
CM_ SG_ 1461 ICC_Wifi_SSID_Character_4 "Character 4(ASCII)";
CM_ SG_ 1461 ICC_Wifi_SSID_Character_5 "Character 5(ASCII)";
CM_ SG_ 1461 ICC_Wifi_SSID_Character_6 "Character 6(ASCII)";
CM_ SG_ 1461 ICC_Wifi_SSID_Character_7 "Character 7(ASCII)";
CM_ BO_ 1461 "IBUS1, NoMsgSendType, sent by ICC";
CM_ SG_ 1466 ICC_Wifi_PW_TotalMsgs "Total number of messages.? Signal from ICC to TBOX to communicate user entered password for the network as a null terminated string";
CM_ SG_ 1466 ICC_Wifi_PW_CurrentMsgNm "Current number of messages. ?; CM_ SG_ 1466 ICC_Wifi_PW_Character_1 Character 1(ASCII)";
CM_ SG_ 1466 ICC_Wifi_PW_Character_2 "Character 2(ASCII)";
CM_ SG_ 1466 ICC_Wifi_PW_Character_3 "Character 3(ASCII)";
CM_ SG_ 1466 ICC_Wifi_PW_Character_4 "Character 4(ASCII)";
CM_ SG_ 1466 ICC_Wifi_PW_Character_5 "Character 5(ASCII)";
CM_ SG_ 1466 ICC_Wifi_PW_Character_6 "Character 6(ASCII)";
CM_ SG_ 1466 ICC_Wifi_PW_Character_7 "Character 7(ASCII)";
CM_ BO_ 1466 "IBUS1, NoMsgSendType, sent by ICC";
CM_ SG_ 1471 TBOX_Wifi_Net_StrgthID "The number of current wifi network for strength status";
CM_ SG_ 1471 TBOX_Wifi_Net_StrgthSts "Signal from TBOX to ICC to indicate connection status-Signal strength - RSSI indication";
CM_ SG_ 1471 TBOX_Wifi_Net_Encryp "encryption of the wifi network status (Yes/No)";
CM_ BO_ 1471 "IBUS1, NoMsgSendType, sent by GW";
CM_ SG_ 1480 TBOX_OTA_ownCondchk "TBOX request ECUs to check own conditions for OTA";
CM_ SG_ 1480 TBOX_TerminalRemWakeupSig "Terminal remote wake-up signal";
CM_ SG_ 1480 TBOX_RemSCModReq "Remote charging mode request";
CM_ SG_ 1480 TBOX_RemPwrBattOpenHeatgReq "Remote traction battery ON heating request";
CM_ SG_ 1480 TBOX_RemPwrBattResvHeatgReq "Remote traction battery heating reservation request";
CM_ SG_ 1480 TBOX_RemInsdInfoDispEna "Remote interior information display enabling";
CM_ SG_ 1480 TBOX_RemECCDefrstModReq "A/C defrosting mode request";
CM_ SG_ 1480 TBOX_RemECCResvDefrstReq "Remote A/C Reservation Defrosting Request";
CM_ SG_ 1480 TBOX_RemECCSetT "Remote A/C set temperature value";
CM_ SG_ 1480 TBOX_RemResvECCSetT "Reserved A/C set temperature value remotely";
CM_ SG_ 1480 TBOX_RemSOCMax "User setting of remote power battery heating cutoff SOC value";
CM_ SG_ 1480 TBOX_4GSigIND "4 G signal strength indication";
CM_ SG_ 1480 TBOX_TSPNotConn "Cannot connect to TSP";
CM_ SG_ 1480 TBOX_EHUNotCONN "Fault of USB communication with audio and entertainment system";
CM_ SG_ 1480 TBOX_WIFIError "WIFI fault";
CM_ SG_ 1480 TBOX_InnerBattError "Built-in battery fault";
CM_ SG_ 1480 TBOX_VoltLow "Low voltage fault";
CM_ SG_ 1480 TBOX_VoltHigh "Overvoltage fault";
CM_ SG_ 1480 TBOX_4GLoss "4 G signal loss fault";
CM_ SG_ 1480 TBOX_RemSWH_Req "Remote Function Steering Wheel Heating Request";
CM_ SG_ 1480 TBOX_OTAInhbReq "TBOX request inhibit function to VCU";
CM_ BO_ 1480 "IBUS1, cyclic every 100 ms, sent by GW";
CM_ SG_ 1514 VCU_TripMilg "Distance travelled in a Trip ( km )";
CM_ SG_ 1514 VCU_TripAvgEgyConsmd "Average energy consumed during the trip (Wh/km)";
CM_ BO_ 1514 "IBUS1, cyclic every 500 ms, sent by GW";
CM_ SG_ 1552 ICC_UsrSetChrgRmnMilg "User setting charging reminder mileage";
CM_ SG_ 1552 ICC_EPedlSts "Pedal Comport Setting (One Pedal Drive / Roll / Creep) command to VCU";
CM_ SG_ 1552 ICC_AccelMod "Acceleration Mode setting (Low/Mid/High) command to VCU";
CM_ SG_ 1552 ICC_BoostMode "Setting Boost mode active / inactive";
CM_ SG_ 1552 ICC_EgyCnseClrFlg "Energy consumption reset flag bit";
CM_ SG_ 1552 ICC_VehiMod "Vehicle mode";
CM_ SG_ 1552 ICC_EgyCnseStcClrFlg "Energy consumption statistics reset flag bit";
CM_ SG_ 1552 ICC_UsrSetDchaEndDrvgMilg "The user sets the driving range of the discharge cut-off";
CM_ SG_ 1552 ICC_PollingFctOpenSts "Polling function ON status";
CM_ SG_ 1552 ICC_KickFctOpenSts "Foot kicking function is on";
CM_ SG_ 1552 ICC_UsrSetChrgGunAntithft "The user sets whether the charging gun is anti-theft";
CM_ SG_ 1552 ICC_ChrgInsulFctReq "Central control charging insulation function request";
CM_ SG_ 1552 ICC_StopChrgBtn "Stop charging button of central control";
CM_ SG_ 1552 ICC_DrvModSig "Drive mode setting command to all ECUs that behave different basing on active drive mode";
CM_ SG_ 1552 ICC_SetACChrgLmtCrt "Central control setting AC charging current limit";
CM_ SG_ 1552 ICC_SetTrvlMod "Central control setting travel mode";
CM_ SG_ 1552 ICC_RegenLvl "Coasting Mode settings (Off, Normal, high) command to VCU";
CM_ SG_ 1552 ICC_SetChrgEndSOC "Set cut-off charging SOC value with central control";
CM_ SG_ 1552 ICC_StartChrgBtn "Start charging button of central control";
CM_ BO_ 1552 "IBUS1, CE every 1000 ms, sent by ICC";
CM_ SG_ 1583 TBOX_CrtTi_Day "Current time_day";
CM_ SG_ 1583 TBOX_CrtTi_Hr "Current time_hour";
CM_ SG_ 1583 TBOX_CrtTi_Mins "Current time_min";
CM_ SG_ 1583 TBOX_CrtTi_Yr "Current time_year";
CM_ SG_ 1583 TBOX_CrtTi_Mth "Current time_month";
CM_ SG_ 1583 TBOX_CrtTi_Sec "Current time_seconds";
CM_ BO_ 1583 "IBUS1, cyclic every 1000 ms, sent by GW";
CM_ SG_ 1649 PWC_R_SwVersS "PWC_R software version number";
CM_ SG_ 1649 PWC_R_PartVers "PWC_R part No.";
CM_ SG_ 1649 PWC_R_HwVers "PWC_R hardware version number";
CM_ SG_ 1649 PWC_R_SwVersM "PWC_R main software version number";
CM_ BO_ 1649 "IBUS1, cyclic every 1000 ms, sent by PWC_R";
CM_ SG_ 1652 PWC_SwVersS "PWC software version number";
CM_ SG_ 1652 PWC_PartVers "PWC part No.";
CM_ SG_ 1652 PWC_HwVers "PWC hardware version number";
CM_ SG_ 1652 PWC_SwVersM "PWC main software version number";
CM_ BO_ 1652 "IBUS1, cyclic every 1000 ms, sent by PWC_L";
CM_ SG_ 1653 AMP_CalHwVers "AMP secondary hardware version number";
CM_ SG_ 1653 AMP_SwVersS "AMP software version number";
CM_ SG_ 1653 AMP_PartVers "AMP part number";
CM_ SG_ 1653 AMP_HwVers "AMP main hardware version number";
CM_ SG_ 1653 AMP_SwVersM "AMP major software version number";
CM_ BO_ 1653 "IBUS1, cyclic every 1000 ms, sent by AMP";
CM_ SG_ 1672 MFS_SwVersS "MFS software version number last two bits";
CM_ SG_ 1672 MFS_PartVers "MFS part number";
CM_ SG_ 1672 MFS_HwVers "MFS hardware version number last two digits";
CM_ SG_ 1672 MFS_SwVersM "MFS major software version number last two bits";
CM_ BO_ 1672 "IBUS1, cyclic every 50 ms, sent by MFSS";
CM_ SG_ 1675 RAC_SwVersS "RAC software version number";
CM_ SG_ 1675 RAC_PartVers "RAC part number";
CM_ SG_ 1675 RAC_HwVers "RAC hardware version number";
CM_ SG_ 1675 RAC_SwVersM "RAC main software version number";
CM_ BO_ 1675 "IBUS1, cyclic every 1000 ms, sent by RAC";
CM_ SG_ 1696 BMS_mxCounterActEnergy "Date type for this message";
CM_ SG_ 1696 BMS_mxEnergyActValue1 "Signal according valuetable or mxCounterActEnergy";
CM_ SG_ 1696 BMS_mxEnergyActValue2 "Signal according valuetable or mxCounterActEnergy";
CM_ SG_ 1696 DCDC_ActTemp "DCDC actual temperature";
CM_ BO_ 1696 "IBUS1, cyclic every 500 ms, sent by GW";
CM_ SG_ 1756 BMS_mxCounterEnergy "Date type for this message";
CM_ SG_ 1756 BMS_mxEnergyValue1 "Signal according valuetable or mxCounterEnergy";
CM_ SG_ 1756 BMS_mxEnergyValue2 "Signal according valuetable or mxCounterEnergy";
CM_ BO_ 1756 "IBUS1, NoMsgSendType, sent by GW";
CM_ SG_ 1757 BMS_PVIU_actPower "actual delivered Power from PV-Panel";
CM_ SG_ 1757 BMS_PVIU_EnergyOverall "overall gathered energy";
CM_ SG_ 1757 BMS_PVIU_ActEngyYear "gathered actual energy of this year";
CM_ BO_ 1757 "IBUS1, cyclic every 1000 ms, sent by GW";
CM_ SG_ 1760 BCM_VIN_Byte1 "This Signal contains the seventh-last position of the vehicle identification number (positions are coded in ASCII).";
CM_ SG_ 1760 BCM_VIN_Byte2 "This Signal contains the sixth-last position of the vehicle identification number (positions are coded in ASCII).";
CM_ SG_ 1760 BCM_VIN_Byte3 "This Signal contains the fifth-last position of the vehicle identification number (positions are coded in ASCII).";
CM_ SG_ 1760 BCM_VIN_Byte4 "This Signal contains the fourth-last position of the vehicle identification number (positions are coded in ASCII).";
CM_ SG_ 1760 BCM_VIN_Byte5 "This Signal contains the third-last position of the vehicle identification number (positions are coded in ASCII).";
CM_ SG_ 1760 BCM_VIN_Byte6 "This Signal contains the second-last position of the vehicle identification number (positions are coded in ASCII).";
CM_ SG_ 1760 BCM_VIN_Byte7 "This Signal contains the last position of the vehicle identification number (positions are coded in ASCII).";
CM_ BO_ 1760 "IBUS1, cyclic every 5000 ms, sent by GW";
CM_ SG_ 233 BMS_Bat_HVmeasure_CheckSum "Message CheckSum(E2E data ID: 0x26)";
CM_ SG_ 233 BMS_Bat_HVmeasure_AliveCounter "Rolling counter";
CM_ SG_ 233 BMS_Bat_HVmeasure_Current "Values from IVT [A], actual current in HV circuit";
CM_ SG_ 233 BMS_Bat_Hvmeasure_V_Pack "Values from IVT [V], (U1) - Battery voltage";
CM_ BO_ 233 "IBUS2, cyclic every 20 ms, sent by GW";
CM_ SG_ 261 VCU_105_CheckSum "VCU_105_Message checksum( E2E data ID: 0x16)";
CM_ SG_ 261 VCU_105_AliveCounter "VCU_105 _Message counterVCU_105_AliveCounter";
CM_ SG_ 261 VCU_DmdTqFltFlg "Required torque fault flag bit";
CM_ SG_ 261 VCU_AllwMntnIndcrLamp "Allowable service indicator lamp";
CM_ SG_ 261 VCU_AlrmLamp_FS "Warning lamp_VCU (functional safety)";
CM_ SG_ 261 VCU_VehTqDistbnRat "Vehicle torque distribution ratio";
CM_ BO_ 261 "IBUS2, cyclic every 20 ms, sent by GW";
CM_ SG_ 279 ADAS_117_CheckSum "ADAS_117_CheckSum (0x48)";
CM_ SG_ 279 ADAS_117_AliveCounter "ADAS_117_AliveCounter";
CM_ SG_ 279 ADAS_OTARdy_Fb "ADAS OTA ready status feedback";
CM_ SG_ 279 ADAS_LgtCtrl_Sts "Longitudinal controler status";
CM_ SG_ 279 ADAS_LgtCtrl_StsVld "Longitudinal controller validity (for initialization)";
CM_ SG_ 279 ADAS_LgtCtrl_DrvrOvrdSts "Longitudinal controler driver override status";
CM_ SG_ 279 ADAS_LgtCtrl_DrvrOvrdVld "Longitudinal controler driver roverride validity.";
CM_ SG_ 279 ADAS_HAP_EmgyStandstillVld "ADAS Highly Automated Parking Emergency Standstill request validity";
CM_ SG_ 279 ADAS_HAP_EmgyEPBVld "ADAS Highly Automated Parking Emergency EPB request validity";
CM_ SG_ 279 ADAS_HAP_EmgyStandstillReq "ADAS Highly Automated Parking Emergency Standstill request";
CM_ SG_ 279 ADAS_ParkStandstillReq "Longitudinal controler Standstill request";
CM_ SG_ 279 ADAS_ParkStandstillVld "Longitudinal controler Standstill request validity";
CM_ SG_ 279 ADAS_ParkGearReq "Park gear request";
CM_ SG_ 279 ADAS_ParkGearReqVld "Park gear request validity";
CM_ SG_ 279 ADAS_LgtCtrl_Typ "Longitudinal controler type of request";
CM_ SG_ 279 ADAS_HAP_EmgyEPBReq "ADAS Highly Automated Parking Emergency EPB request";
CM_ SG_ 279 ADAS_ISA_CutOffReq "ISA cutoff request";
CM_ SG_ 279 ADAS_ISA_SpdLmt_VCU "ISA detected speed limit + user selected offset. Signal used for VCU";
CM_ BO_ 279 "IBUS2, CE every 10 ms, sent by GW";
CM_ SG_ 280 ADAS_118_CheckSum "ADAS_118_CheckSum (0x51)";
CM_ SG_ 280 ADAS_118_AliveCounter "ADAS_118_AliveCounter";
CM_ SG_ 280 ADAS_LgtCtrl_ESP_Sts "Longitudinal controler ADAS-ESP status";
CM_ SG_ 280 ADAS_LgtCtrl_ESP_Vld "Longitudinal controler ADAS-ESP validity";
CM_ SG_ 280 ADAS_ESP_DrvrOvrdSts "Driver override status to ESP?";
CM_ SG_ 280 ADAS_ESP_DrvrOvrdVld "Driver override validity to ESP";
CM_ SG_ 280 ADAS_HBAReq "Hydraulic Brake Assist (HBA) request";
CM_ SG_ 280 ADAS_HBAVld "Hydraulic brake assist (HBA) validity";
CM_ SG_ 280 ADAS_ESP_StandstillReq "Standstill request to ESP";
CM_ SG_ 280 ADAS_ESP_StandstillVld "Standstill request to ESP validity";
CM_ SG_ 280 ADAS_JerkReq "AEB jerk request";
CM_ SG_ 280 ADAS_JerkReqVld "Jerk validity. Do not use, keep as reserved";
CM_ SG_ 280 ADAS_BrkPrefillReq "Brake prefill request";
CM_ SG_ 280 ADAS_BrkPrefillVld "Brake prefill request validity";
CM_ SG_ 280 ADAS_AEB_ActvTyp "AEB type of request";
CM_ SG_ 280 ADAS_AEB_DecelVld "AEB deceleration request valid";
CM_ SG_ 280 ADAS_AEB_DecelReq "AEB deceleration request value";
CM_ BO_ 280 "IBUS2, cyclic every 10 ms, sent by GW";
CM_ SG_ 281 iBooster_119_CheckSum "iBooster_119_Message Checksum (E2E data ID: 0xA4)";
CM_ SG_ 281 iBooster_119_AliveCounter "iBooster_119_Message CounteriBooster_119_AliveCounter";
CM_ SG_ 281 iBooster_OTARdy_Fb "iBooster OTA ready status feedback";
CM_ SG_ 281 iBooster_WarnOn "Required instrument display fault warning lamp With this signal eBooster requests the warning lamp in the dashboard.";
CM_ SG_ 281 iBooster_BrkPedlAppldFlg "Press the brake pedal to the mark position information about the driver attendance.";
CM_ SG_ 281 iBooster_BrkPedlAppldVld "State bit of the brake pedal depressed flag position Qualifier for Brake Pedal Applied.";
CM_ BO_ 281 "IBUS2, cyclic every 20 ms, sent by GW";
CM_ SG_ 369 ICC_Start_X_Coordinate "X position of finger in all touch events";
CM_ SG_ 369 ICC_Start_Y_Coordinate "Y position of finger in all touch events";
CM_ SG_ 369 ICC_dX_Coordinate "For PAN operation, change in X for TOUCH and TOUCH_END events only";
CM_ SG_ 369 ICC_dY_Coordinate "For PAN operation, change in Y for TOUCH and TOUCH_END events only";
CM_ BO_ 369 "IBUS2, NoMsgSendType, sent by ICC";
CM_ SG_ 416 VCU_ECC_PwrMax "maximal power that can be used by ECC HV components";
CM_ SG_ 416 VCU_ECC_PwrMin "minimal power that must be used by the ECC HV components.";
CM_ SG_ 416 VCU_DCDCPwrLimCmd "DC/DC power limit command";
CM_ BO_ 416 "IBUS2, cyclic every 100 ms, sent by GW";
CM_ SG_ 425 ECC_VCU_PwrReq "actual power requested(used) by the ECC HV components";
CM_ SG_ 425 ECC_OTARdy_Fb "ECC OTA ready status feedback";
CM_ BO_ 425 "IBUS2, cyclic every 100 ms, sent by GW";
CM_ SG_ 438 PKC_1B6_CheckSum "PKC_1B6_Message inspection (0x19)PKC_1B6_CheckSum";
CM_ SG_ 438 PKC_1B6_AliveCounter "PKC_1B6_AliveCounter";
CM_ SG_ 438 PKC_TpMnvrCancel "Cancel of trained parking maneuver";
CM_ SG_ 438 PKC_TpActDeactInp "Activation and deactivation of trained parking";
CM_ SG_ 438 PKC_RemPwrOnOffReq "Remote power on/off request";
CM_ SG_ 438 PKC_RemDrvgReq "Remote driving request";
CM_ SG_ 438 PKC_RemChrgDchaGunUnlckCmd "Remote charge and discharge gun unlocking command";
CM_ SG_ 438 PKC_RmteDviceBattLvl "Remote control device battery power Indicates the remote device battery percentage.";
CM_ SG_ 438 PKC_BLE_Online "Mobile APP online signal";
CM_ SG_ 438 PKC_DviceRngeDist "Remote control device distance Remote device distance from vehicle.";
CM_ SG_ 438 PKC_DviceAliveCnt "Heartbeat signal Remote device heart beat.";
CM_ SG_ 438 PKC_MnvreEnblInput "RPA parking switch state Remote control deadman switch pressed or unpressed.";
CM_ SG_ 438 PKC_RapActDeactInp "RPA Cancel Request Parking maneuvering cancel request.";
CM_ SG_ 438 PKC_MnvrRemsumeKey "RPA recovery request Parking maneuverin Remsume request.";
CM_ SG_ 438 PKC_MnvrRtnStartKey "RPA return start position request Request return to original point.";
CM_ SG_ 438 PKC_AlcInterlockReqPromt "Alcohol test result";
CM_ SG_ 438 PKC_NFCReminderPromt "If more than 30 seconds elapsed since the unlocking the vehicle with the NFC";
CM_ BO_ 438 "IBUS2, cyclic every 10 ms, sent by GW";
CM_ SG_ 448 ADAS_1C0_CheckSum "ADAS_1C0_CheckSum (E2E data ID: 0xC3); Calculation E2E from byte 1~3";
CM_ SG_ 448 ADAS_1C0_AliveCounter "ADAS_1C0_AliveCounter";
CM_ SG_ 448 ADAS_LatCtrl_Sts "Lateral control function status";
CM_ SG_ 448 ADAS_LatCtrl_StsVld "Lateral control function status validity";
CM_ SG_ 448 ADAS_LatCtrl_DrvrOvrd "Lateral control driver overide";
CM_ SG_ 448 ADAS_LatCtrl_DrvrOvrdVld "Lateral control driver overide validity";
CM_ SG_ 448 ADAS_LatCtrl_Typ "Lateral control type of request";
CM_ SG_ 448 ADAS_LatCtrl_ReqVld "Lateral control request validity";
CM_ SG_ 448 ADAS_LatCtrl_Req "Lateral control command for activation of the request";
CM_ BO_ 448 "IBUS2, cyclic every 10 ms, sent by GW";
CM_ SG_ 522 ADAS_LeLine2LnTyp "True left lane line 2 type (observed)";
CM_ SG_ 522 ADAS_LeLine2Offset "offset of the left lane line 2";
CM_ SG_ 522 ADAS_LeLine2LnColor "Real right lane line 2 color (observation)";
CM_ SG_ 522 ADAS_LeLine2Hdng "Heading of the left lane line 2";
CM_ SG_ 522 ADAS_LeLine2Crvt "Real left lane 2 curvature (observed)";
CM_ SG_ 522 ADAS_LeLine2Conf "Left lane line 2 confidence";
CM_ SG_ 522 ADAS_LeLine2CrvtRt "Rate of curvature of the left lane line 2";
CM_ BO_ 522 "IBUS2, cyclic every 50 ms, sent by GW";
CM_ SG_ 523 ADAS_LeLine3LnTyp "True left lane line 3 type (observed)";
CM_ SG_ 523 ADAS_LeLine3Offset "offset of the left lane line 3";
CM_ SG_ 523 ADAS_LeLine3LnColor "Real right lane line 3 color (observation)";
CM_ SG_ 523 ADAS_LeLine3Hdng "Heading of the left lane line 3";
CM_ SG_ 523 ADAS_LeLine3Crvt "Real left lane 3 curvature (observed)";
CM_ SG_ 523 ADAS_LeLine3Conf "Left lane line 3 confidence";
CM_ SG_ 523 ADAS_LeLine3CrvtRt "Rate of curvature of the left lane line 3";
CM_ BO_ 523 "IBUS2, cyclic every 50 ms, sent by GW";
CM_ SG_ 524 ADAS_RiLine1LnTyp "True right lane line 1 type (observation)";
CM_ SG_ 524 ADAS_RiLine1Offset "offset of the Right lane line 1";
CM_ SG_ 524 ADAS_RiLine1LnColor "Real right lane line 1 color (observation)";
CM_ SG_ 524 ADAS_RiLine1Hdng "Heading of the Right lane line 1";
CM_ SG_ 524 ADAS_RiLine1Crvt "Real Right lane 1 curvature (observed)";
CM_ SG_ 524 ADAS_RiLine1Conf "Right lane line 1 confidence";
CM_ SG_ 524 ADAS_RiLine1CrvtRt "Rate of curvature of the Right lane line 1";
CM_ BO_ 524 "IBUS2, cyclic every 50 ms, sent by GW";
CM_ SG_ 525 ADAS_RiLine2LnTyp "True right lane line 2 type (observation)";
CM_ SG_ 525 ADAS_RiLine2Offset "offset of the Right lane line 2";
CM_ SG_ 525 ADAS_RiLine2LnColor "Real right lane line 2 color (observation)";
CM_ SG_ 525 ADAS_RiLine2Hdng "Heading of the Right lane line 2";
CM_ SG_ 525 ADAS_RiLine2Crvt "Real Right lane 2 curvature (observed)";
CM_ SG_ 525 ADAS_RiLine2Conf "Right lane line 2 confidence";
CM_ SG_ 525 ADAS_RiLine2CrvtRt "Rate of curvature of the Right lane line 2";
CM_ BO_ 525 "IBUS2, cyclic every 50 ms, sent by GW";
CM_ SG_ 526 ADAS_RiLine3LnTyp "True right lane line 3 type (observation)";
CM_ SG_ 526 ADAS_RiLine3Offset "offset of the Right lane line 3";
CM_ SG_ 526 ADAS_RiLine3LnColor "Real right lane line 3 color (observation)";
CM_ SG_ 526 ADAS_RiLine3Hdng "Heading of the Right lane line 3";
CM_ SG_ 526 ADAS_RiLine3Crvt "Real Right lane 3 curvature (observed)";
CM_ SG_ 526 ADAS_RiLine3Conf "Right lane line 3 confidence";
CM_ SG_ 526 ADAS_RiLine3CrvtRt "Rate of curvature of the Right lane line 3";
CM_ BO_ 526 "IBUS2, cyclic every 50 ms, sent by GW";
CM_ SG_ 527 ADAS_RealLaneWidth "Real lane width (observed)";
CM_ SG_ 527 ADAS_EgoDecelLane "Ego deceleration lane";
CM_ SG_ 527 ADAS_EgoCarpoolLane "Ego carpool Lane";
CM_ BO_ 527 "IBUS2, cyclic every 50 ms, sent by GW";
CM_ SG_ 528 ADAS_TLR_EgoLaneTyp "ADAS TLR object 1";
CM_ SG_ 528 ADAS_TLR_EgoLaneSts "ADAS TLR object 1 status";
CM_ SG_ 528 ADAS_WSP_LeftCurb "Left Curb Detection";
CM_ SG_ 528 ADAS_TLR_EgoLaneColor "TLR Ego lane color";
CM_ SG_ 528 ADAS_TrafficLightShape "Status of the Detected Traffic light shpe ( Circle / Arrorw / Square)";
CM_ SG_ 528 ADAS_TSRPassingCondition "Dispaly Overtaking Available or Not";
CM_ SG_ 528 ADAS_TLR_WarnReq "TLR warning request";
CM_ SG_ 528 ADAS_WSP_RightCurb "Right Curb Detection";
CM_ SG_ 528 ADAS_ISAOverSpeedWarning "ISA overspeed warning request";
CM_ SG_ 528 ADAS_TSRSignCondition "Stop, No Entry, School Zone, Caution, Construction Zone";
CM_ SG_ 528 ADAS_TSRSpdLimConfidenceLvl "signal shall be added to provide the Confidence of SLIF Percieved Speed Limit for ISA.";
CM_ BO_ 528 "IBUS2, cyclic every 50 ms, sent by GW";
CM_ SG_ 533 BMS_215_CheckSum "BMS_215_Message checksum( E2E data ID: 0x13)";
CM_ SG_ 533 BMS_215_AliveCounter "BMS_215 _Message counterBMS_215_AliveCounter";
CM_ SG_ 533 BMS_PwrBattOverTFlt_FS "Power battery temperature too high (functional safety)";
CM_ SG_ 533 BMS_PwrBattOverCrtFlt_FS "Power battery overcurrent fault (functional safety)";
CM_ SG_ 533 BMS_PwrBattNegRlyAdh_FS "Connection of relay at negative terminal of traction battery (functional safety)";
CM_ SG_ 533 BMS_PwrBattPosRlyAdh_FS "Traction battery positive terminal relay sticking (functional safety)";
CM_ SG_ 533 BMS_CellUnderrVoltFlt_FS "Single undervoltage fault (functional safety)";
CM_ SG_ 533 BMS_PwrBattCellOverVolt_FS "Power battery cell overvoltage (functional safety)";
CM_ SG_ 533 BMS_BattInlTSnsrFlt "Battery inlet water temperature sensor fault";
CM_ SG_ 533 BMS_BattOutlTSnsrFlt "Battery outlet water temperature sensor fault";
CM_ SG_ 533 BMS_PwrBattPrecRlyAdh_FS "Traction battery pre-charge relay blocking (functional safety)";
CM_ SG_ 533 BMS_AlrmLamp_FS "Warning lamp_BMS (functional safety)";
CM_ SG_ 533 BMS_PwrBattLoadTotVoltV3_FS "Total voltage of traction battery load end V3 (functional safety)";
CM_ SG_ 533 BMS_FctSftyErrCod "Functional safety fault codeFunctional safety code";
CM_ BO_ 533 "IBUS2, cyclic every 20 ms, sent by GW";
CM_ SG_ 566 VCU_236_CheckSum "VCU_236_Message checksum (E2E data ID: 0x94)";
CM_ SG_ 566 VCU_236_AliveCounter "VCU_236_Message counterVCU_236_AliveCounter";
CM_ SG_ 566 VCU_DCChrgDchaGunCnctnSts "DC Connection state of charge/discharge gun";
CM_ SG_ 566 VCU_OutpACWakeupSigSts "VCU output AC charge and discharge wake-up signal state";
CM_ SG_ 566 VCU_OutpFCWakeupSigSts "VCU output fast charge wake-up signal state";
CM_ SG_ 566 VCU_ACChrgDchaGunCnctnSts "AC Connection state of charge/discharge gun";
CM_ SG_ 566 VCU_VcuErrCtgy "VCU Error Category";
CM_ SG_ 566 VCU_VcuState "VCU state signal";
CM_ SG_ 566 VCU_VcuErrBitVect "VCU error bit signal";
CM_ SG_ 566 VCU_PwrSplyEquipSts "State of power supply equipment";
CM_ BO_ 566 "IBUS2, cyclic every 20 ms, sent by GW";
CM_ SG_ 586 BMS_24A_CheckSum "BMS_24A_message checksum (E2E data ID: 0xA8)";
CM_ SG_ 586 BMS_24A_AliveCounter "BMS_24A message counterBMS_24A_AliveCounter";
CM_ SG_ 586 BMS_PwrBattChrgDchaCrt1 "Traction battery charge and discharge current (functional safety channel 1)";
CM_ SG_ 586 BMS_PwrBattChrgDchaCrt2 "Traction battery charge and discharge current (functional safety channel 2)";
CM_ SG_ 586 BMS_PwrBattIntTotVoltV1 "Total internal voltage V1 of traction battery";
CM_ BO_ 586 "IBUS2, cyclic every 20 ms, sent by GW";
CM_ SG_ 592 ICC_SegMsgType "Identify the message as the segment message";
CM_ SG_ 592 ICC_SegOffset "The distance from the starting point of the current segment to the starting point of the PathOffset of this segment from start position of the path modulo 8191; Value 8191 is invalid";
CM_ SG_ 592 ICC_SegPathIdx "Index value of path to which this segment belongsValue is Index of path of which this segment is part";
CM_ SG_ 592 ICC_SegCycCnt "Loop counter of SEGMENT Message: The reconstructor can use this value to detect missing messagesCyclic counter of this message type:Reconstructor can use this value to detect missing messages";
CM_ SG_ 592 ICC_SegUpdate "UpdateValue true indicates that this message contains updated information of already transmitted SEGMENT.";
CM_ SG_ 592 ICC_SegRetr "If true, the message has been sent once before (Seg)";
CM_ SG_ 592 ICC_SegBuildUpArea "segment built-up information";
CM_ SG_ 592 ICC_SegBridge "Informationsegment bridge";
CM_ SG_ 592 ICC_SegTunnel "segment tunnel information";
CM_ SG_ 592 ICC_SegFuncRoadClass "segment FRC information (corresponding road type, main road)Functional Road Class indicates relative importance of the road in the routing network and lower values indicate higher priority. This information is usually map-provider specific.";
CM_ SG_ 592 ICC_SegRelProbb "resolution should use 100/30 %.";
CM_ SG_ 592 ICC_SegFormOfWay "segment road facilities information (for ramp information, refer to sheet3, where 9 corresponding ramp information) see sheet3 for details";
CM_ SG_ 592 ICC_SegCmplxInsct "Whether the segment is the information on the complex intersection";
CM_ SG_ 592 ICC_SegPartOfCalcRoute "whether the information on the planning path is on the segment";
CM_ SG_ 592 ICC_SegEffSpdLmtType "segment Effective speed limit type information";
CM_ SG_ 592 ICC_SegEffSpdLmt "information of speed limit (current speed limit)see sheet5 for details";
CM_ SG_ 592 ICC_SegNumOfLaneDrvDir "Number of lanes in driving direction: also indicates driving direction.";
CM_ SG_ 592 ICC_SegNumOfLaneOppDir "Number of lanes in opposite direction";
CM_ SG_ 592 ICC_SegDividedRoad "segment Divided Road";
CM_ BO_ 592 "IBUS2, cyclic every 100 ms, sent by ICC";
CM_ SG_ 593 ICC_StubMsgType "Identify the message as a St<UNK> Message";
CM_ SG_ 593 ICC_StubOffset "Distance between the start point of the st<UNK> and the start point of the pathOffset of the position of the crossing from the start path position modulo 8191. Offset 8191 is invalid.";
CM_ SG_ 593 ICC_StubPathIdx "Index value of the parent path, 0 represents the first path in horizon starting from this STUBIndex of parent path; zero indicates this STUB starts first path in the Horizon";
CM_ SG_ 593 ICC_StubCycCnt "Cyclic counter of STUB Message: The reconstructor can detect lost messages with this valueCyclic counter of this message type:Reconstructor can use this value to detect missing messages.";
CM_ SG_ 593 ICC_StubUpdate "UpdateStub Segment";
CM_ SG_ 593 ICC_StubRetr "If true, this message has been sent once before (St<UNK>)";
CM_ SG_ 593 ICC_StubStubPathIdx "st<UNK> path indexValues 8 to 63:“Normal” STUB message, defining the origin of a new path; subsequent messages referring to this Index value will provide more data about it.";
CM_ SG_ 593 ICC_StubRelProbb "Resolution should be 100/30 %";
CM_ SG_ 593 ICC_StubFormOfWay "Road facilities information of st<UNK> (corresponding ramp information, branch)Form of Way of new path";
CM_ SG_ 593 ICC_StubCmplxInsct "Is the information on complex intersections";
CM_ SG_ 593 ICC_StubPartOfCalcRout "if the information on the planned path is the st<UNK>";
CM_ SG_ 593 ICC_StubTurnAngl "Angle of the new path relative to the main path. Resolution should be 360/254 degrees";
CM_ SG_ 593 ICC_StubNumOfLaneDrvDir "Number of lanes in driving direction: also indicates driving direction.";
CM_ SG_ 593 ICC_StubNumOfLaneOppDir "Number of lanes in opposite direction";
CM_ SG_ 593 ICC_StubRtOfWay "Road priority information";
CM_ SG_ 593 ICC_StubLastStub "Last Stub at OffsetValue true indicates that this STUB message is last one that refers to given parent path and offset; value false says that more STUB messages for this offset on parent path will be sent";
CM_ BO_ 593 "IBUS2, cyclic every 100 ms, sent by ICC";
CM_ SG_ 594 ICC_ProfLongMsgType "Identify the message as Profile long";
CM_ SG_ 594 ICC_ProfLongOffset "The position of the first contour point from the start position 8191 is offset.Offset of position of the first profile spot from start position modulo 8191. Offset 8191 is invalid";
CM_ SG_ 594 ICC_ProfLongPathIdx "Index value of path to which this profile (s) belongsIndex of the path where this profile(s) is located";
CM_ SG_ 594 ICC_ProfLongCycCnt "Loop counter of this message type and profile type: The reconstructor can use this value to detect missing messagesCyclic counter of this message type and profile type:Reconstructor can use this value to detect missing messages";
CM_ SG_ 594 ICC_ProfLongUpdate "PROFILE LONG updateValue true indicates that this message contains updated information of already transmitted PROFILE LONG";
CM_ SG_ 594 ICC_ProfLongRetr "If true, this message has been sent once before";
CM_ SG_ 594 ICC_ProfLongCtrlPoint "Control PointIf true, values in this message specifies additional control points required for the interpolation of this profile; if false, actual profile values are specified.";
CM_ SG_ 594 ICC_ProfLongSignType "Types of traffic signSee table TrafficSign:Traffic signs and situations";
CM_ SG_ 594 ICC_ProfLongSignTimeSpec "The traffic sign is valid for a specific timeThis field marks a sign that is valid only on specific days or at specific times:";
CM_ SG_ 594 ICC_ProfLongSignVehSpec "The traffic sign is valid for a specific vehicleThis field marks a sign that is valid only for specific vehicles. This includes signs valid only for vehicles with specific dimensions or loads:";
CM_ SG_ 594 ICC_0x252_Reserved "Reserved space";
CM_ SG_ 594 ICC_ProfLongSignLocation "Traffic sign position";
CM_ SG_ 594 ICC_ProfLongSignCondition "Other Dependencies of Traffic signThis field describes other conditions and dependencies. Time and vehicle type/load dependencies are not taken into account here.";
CM_ BO_ 594 "IBUS2, cyclic every 100 ms, sent by ICC";
CM_ SG_ 597 ICC_ProfShortMsgType "Identify the message as Profile Short";
CM_ SG_ 597 ICC_ProfShortOffset "The position of the first contour point from the start position 8191 is offset.";
CM_ SG_ 597 ICC_ProfShortPathIdx "Index value of path to which this profile (s) belongsIndex of the path where this profile(s) is located.";
CM_ SG_ 597 ICC_ProfShortCycCnt "Loop counter of this message type and profile type: The reconstructor can use this value to detect missing messagesCyclic counter of this message type and profile type:Reconstructor can use this value to detect missing messages";
CM_ SG_ 597 ICC_ProfShortUpdate "PROFILE SHORT updateValue true indicates that this message contains updated information of already transmitted PROFILE SHORT";
CM_ SG_ 597 ICC_ProfShortRetr "If true, this message has been sent once before";
CM_ SG_ 597 ICC_ProfShortCtrlPoint "Control PointIf true, values in this message specifies additional control points required for the interpolation of this profile; if false, actual profile values are specified.";
CM_ SG_ 597 ICC_ProfShortProfType "Standard PROFILE SHORT type";
CM_ SG_ 597 ICC_ProfShortAccurClass "Accuracy of profile values Accuracy of profile value is implementation specific.";
CM_ SG_ 597 ICC_ProfShortDist1 "Distance from the first profile to the second profile.Distance from first profile spot to the second one.";
CM_ SG_ 597 ICC_ProfShortValue0 "Profile value of Offset;Profile value at Offset;a special value (usually 1023) signals an invalid, unknown or N/A value.";
CM_ SG_ 597 ICC_ProfShortValue1 "Configuration file value of Offset + Distance1;Profile value at Offset+Distance1;a special value (usually 1023) signals an invalid, unknown or N/A value.";
CM_ BO_ 597 "IBUS2, cyclic every 100 ms, sent by ICC";
CM_ SG_ 617 VCU_260_269_CheckSum "VCU_260_269_CheckSum (E2E data ID: 0x5D)";
CM_ SG_ 617 VCU_260_269_AliveCounter "VCU_260_269_AliveCounter";
CM_ SG_ 617 VCU_DCVoltCmd_OBC "DC terminal voltage command of on-board charger";
CM_ SG_ 617 VCU_DCCrtCmd_OBC "On-board charger DC terminal current command";
CM_ SG_ 617 VCU_VehChrgDchgMod "Vehicle charge and discharge mode";
CM_ SG_ 617 VCU_DCRlyCtrlCmd "DC charging relay control command";
CM_ SG_ 617 VCU_ChrgSysOperCmd "Operating instructions of charging system";
CM_ SG_ 617 VCU_ChrgSts "VCU charging status";
CM_ BO_ 617 "IBUS2, cyclic every 20 ms, sent by GW";
CM_ SG_ 711 ADAS_APASlot5_FrLeCrnr_y "Front left corner y in body frame - slot 5";
CM_ SG_ 711 ADAS_APASlot5_FrRiCrnr_x "Front right corner x in body frame - slot 5";
CM_ SG_ 711 ADAS_APASlot5Typ "Slot 5 type";
CM_ SG_ 711 ADAS_APASlot5Sid "Slot 5 side";
CM_ SG_ 711 ADAS_APASlot5Sts "Slot 5 status";
CM_ SG_ 711 ADAS_APASlot5_FrRiCrnr_y "Front right corner y in body frame - slot 5";
CM_ SG_ 711 ADAS_APASlot5ID "Slot ID (1 - 15). Only tracks 6 parking slots. IDs shall rotate back to 1 after 6";
CM_ BO_ 711 "IBUS2, cyclic every 100 ms, sent by GW";
CM_ SG_ 714 ADAS_APASlotSel_ReLeCrnr_x "Rear left corner x in body frame - Selected slot";
CM_ SG_ 714 ADAS_APASlotSel_ReLeCrnr_y "Rear left corner y in body frame - Selected slot";
CM_ SG_ 714 ADAS_APASlotSel_ReRiCrnr_x "Rear right corner x in body frame - Selected slot";
CM_ SG_ 714 ADAS_APASlotSel_ReRiCrnr_y "Rear right corner y in body frame - Selected slot";
CM_ SG_ 714 ADAS_APASlotSel_FrLeCrnr_x "Front left corner x in body frame - Selected slot";
CM_ BO_ 714 "IBUS2, cyclic every 100 ms, sent by GW";
CM_ SG_ 717 ADAS_APASlotSel_FrLeCrnr_y "Front left corner y in body frame - Selected slot";
CM_ SG_ 717 ADAS_APASlotSel_FrRiCrnr_x "Front right corner x in body frame - Selected slot";
CM_ SG_ 717 ADAS_APASlotSelTyp "Selected slot type";
CM_ SG_ 717 ADAS_APASlotSelSid "Selected slot side";
CM_ SG_ 717 ADAS_APASlotSelSts "Selected slot status";
CM_ SG_ 717 ADAS_APASlotSel_FrRiCrnr_y "Front right corner y in body frame - Selected slot";
CM_ SG_ 717 ADAS_APASlotSelID "Slot ID (1 - 15). Only tracks 6 parking slots. IDs shall rotate back to 1 after 6";
CM_ SG_ 717 ADAS_APAAvailable "Status flag to indicate park in or out is available to HMI";
CM_ SG_ 717 ADAS_APAScanngSde "Scanning direction to HMI";
CM_ SG_ 717 ADAS_CurbPrtcRrLeWhl "Curb warning side - rear left";
CM_ SG_ 717 ADAS_CurbPrtcRrRiWhl "Curb warning side - rear right";
CM_ SG_ 717 ADAS_CurbPrtcFrLeWhl "Curb warning side - front left";
CM_ SG_ 717 ADAS_CurbPrtcFrRiWhl "Curb warning side - front right";
CM_ SG_ 717 ADAS_APASpdWarn "Warning seek speed exceed status to HMI";
CM_ BO_ 717 "IBUS2, cyclic every 100 ms, sent by GW";
CM_ SG_ 720 ADAS_APASlot1_ReLeCrnr_x "Rear left corner x in body frame - slot 1";
CM_ SG_ 720 ADAS_APASlot1_ReLeCrnr_y "Rear left corner y in body frame - slot 1";
CM_ SG_ 720 ADAS_APASlot1_ReRiCrnr_x "Rear right corner x in body frame - slot 1";
CM_ SG_ 720 ADAS_APASlot1_ReRiCrnr_y "Rear right corner y in body frame - slot 1";
CM_ SG_ 720 ADAS_APASlot1_FrLeCrnr_x "Front left corner x in body frame - slot 1";
CM_ BO_ 720 "IBUS2, cyclic every 100 ms, sent by GW";
CM_ SG_ 723 ADAS_APASlot1_FrLeCrnr_y "Front left corner y in body frame - slot 1";
CM_ SG_ 723 ADAS_APASlot1_FrRiCrnr_x "Front right corner x in body frame - slot 1";
CM_ SG_ 723 ADAS_APASlot1Typ "Slot 1 type";
CM_ SG_ 723 ADAS_APASlot1Sid "Slot 1 side";
CM_ SG_ 723 ADAS_APASlot1Sts "Slot 1 status";
CM_ SG_ 723 ADAS_APASlot1_FrRiCrnr_y "Front right corner y in body frame - slot 1";
CM_ SG_ 723 ADAS_APASlot1ID "Slot ID (1 - 15). Only tracks 6 parking slots. IDs shall rotate back to 1 after 6";
CM_ BO_ 723 "IBUS2, cyclic every 100 ms, sent by GW";
CM_ SG_ 726 ADAS_APASlot2_ReLeCrnr_x "Rear left corner x in body frame - slot 2";
CM_ SG_ 726 ADAS_APASlot2_ReLeCrnr_y "Rear left corner y in body frame - slot 2";
CM_ SG_ 726 ADAS_APASlot2_ReRiCrnr_x "Rear right corner x in body frame - slot 2";
CM_ SG_ 726 ADAS_APASlot2_ReRiCrnr_y "Rear right corner y in body frame - slot 2";
CM_ SG_ 726 ADAS_APASlot2_FrLeCrnr_x "Front left corner x in body frame - slot 2";
CM_ BO_ 726 "IBUS2, cyclic every 100 ms, sent by GW";
CM_ SG_ 729 ADAS_APASlot2_FrLeCrnr_y "Front left corner y in body frame - slot 2";
CM_ SG_ 729 ADAS_APASlot2_FrRiCrnr_x "Front right corner x in body frame - slot 2";
CM_ SG_ 729 ADAS_APASlot2Typ "Slot 2 type";
CM_ SG_ 729 ADAS_APASlot2Sid "Slot 2 side";
CM_ SG_ 729 ADAS_APASlot2Sts "Slot 2 status";
CM_ SG_ 729 ADAS_APASlot2_FrRiCrnr_y "Front right corner y in body frame - slot 2";
CM_ SG_ 729 ADAS_APASlot2ID "Slot ID (1 - 15). Only tracks 6 parking slots. IDs shall rotate back to 1 after 6";
CM_ BO_ 729 "IBUS2, cyclic every 100 ms, sent by GW";
CM_ SG_ 732 ADAS_APASlot3_ReLeCrnr_x "Rear left corner x in body frame - slot 3";
CM_ SG_ 732 ADAS_APASlot3_ReLeCrnr_y "Rear left corner y in body frame - slot 3";
CM_ SG_ 732 ADAS_APASlot3_ReRiCrnr_x "Rear right corner x in body frame - slot 3";
CM_ SG_ 732 ADAS_APASlot3_ReRiCrnr_y "Rear right corner y in body frame - slot 3";
CM_ SG_ 732 ADAS_APASlot3_FrLeCrnr_x "Front left corner x in body frame - slot 3";
CM_ BO_ 732 "IBUS2, cyclic every 100 ms, sent by GW";
CM_ SG_ 735 ADAS_APASlot3_FrLeCrnr_y "Front left corner y in body frame - slot 3";
CM_ SG_ 735 ADAS_APASlot3_FrRiCrnr_x "Front right corner x in body frame - slot 3";
CM_ SG_ 735 ADAS_APASlot3Typ "Slot 3 type";
CM_ SG_ 735 ADAS_APASlot3Sid "Slot 3 side";
CM_ SG_ 735 ADAS_APASlot3Sts "Slot 3 status";
CM_ SG_ 735 ADAS_APASlot3_FrRiCrnr_y "Front right corner y in body frame - slot 3";
CM_ SG_ 735 ADAS_APASlot3ID "Slot ID (1 - 15). Only tracks 6 parking slots. IDs shall rotate back to 1 after 6";
CM_ BO_ 735 "IBUS2, cyclic every 100 ms, sent by GW";
CM_ SG_ 738 ADAS_APASlot4_ReLeCrnr_x "Rear left corner x in body frame - slot 4";
CM_ SG_ 738 ADAS_APASlot4_ReLeCrnr_y "Rear left corner y in body frame - slot 4";
CM_ SG_ 738 ADAS_APASlot4_ReRiCrnr_x "Rear right corner x in body frame - slot 4";
CM_ SG_ 738 ADAS_APASlot4_ReRiCrnr_y "Rear right corner y in body frame - slot 4";
CM_ SG_ 738 ADAS_APASlot4_FrLeCrnr_x "Front left corner x in body frame - slot 4";
CM_ BO_ 738 "IBUS2, cyclic every 100 ms, sent by GW";
CM_ SG_ 741 ADAS_APASlot4_FrLeCrnr_y "Front left corner y in body frame - slot 4";
CM_ SG_ 741 ADAS_APASlot4_FrRiCrnr_x "Front right corner x in body frame - slot 4";
CM_ SG_ 741 ADAS_APASlot4Typ "Slot 4 type";
CM_ SG_ 741 ADAS_APASlot4Sid "Slot 4 side";
CM_ SG_ 741 ADAS_APASlot4Sts "Slot 4 status";
CM_ SG_ 741 ADAS_APASlot4_FrRiCrnr_y "Front right corner y in body frame - slot 4";
CM_ SG_ 741 ADAS_APASlot4ID "Slot ID (1 - 15). Only tracks 6 parking slots. IDs shall rotate back to 1 after 6";
CM_ BO_ 741 "IBUS2, cyclic every 100 ms, sent by GW";
CM_ SG_ 744 ADAS_APASlot5_ReLeCrnr_x "Rear left corner x in body frame - slot 5";
CM_ SG_ 744 ADAS_APASlot5_ReLeCrnr_y "Rear left corner y in body frame - slot 5";
CM_ SG_ 744 ADAS_APASlot5_ReRiCrnr_x "Rear right corner x in body frame - slot 5";
CM_ SG_ 744 ADAS_APASlot5_ReRiCrnr_y "Rear right corner y in body frame - slot 5";
CM_ SG_ 744 ADAS_APASlot5_FrLeCrnr_x "Front left corner x in body frame - slot 5";
CM_ BO_ 744 "IBUS2, cyclic every 100 ms, sent by GW";
CM_ SG_ 745 ADAS_APASlot6_ReLeCrnr_x "Rear left corner x in body frame - slot 6";
CM_ SG_ 745 ADAS_APASlot6_ReLeCrnr_y "Rear left corner y in body frame - slot 6";
CM_ SG_ 745 ADAS_APASlot6_ReRiCrnr_x "Rear right corner x in body frame - slot 6";
CM_ SG_ 745 ADAS_APASlot6_ReRiCrnr_y "Rear right corner y in body frame - slot 6";
CM_ SG_ 745 ADAS_APASlot6_FrLeCrnr_x "Front left corner x in body frame - slot 6";
CM_ BO_ 745 "IBUS2, cyclic every 100 ms, sent by GW";
CM_ SG_ 746 ADAS_APASlot6_FrLeCrnr_y "Front left corner y in body frame - slot 6";
CM_ SG_ 746 ADAS_APASlot6_FrRiCrnr_x "Front right corner x in body frame - slot 6";
CM_ SG_ 746 ADAS_APASlot6Sid "Slot 6 side";
CM_ SG_ 746 ADAS_APASlot6Sts "Slot 6 status";
CM_ SG_ 746 ADAS_APASlot6_FrRiCrnr_y "Front right corner y in body frame - slot 6";
CM_ SG_ 746 ADAS_APASlot6Typ "Slot 6 type";
CM_ SG_ 746 ADAS_APASlot6ID "Slot ID (1 - 15). Only tracks 6 parking slots. IDs shall rotate back to 1 after 6";
CM_ BO_ 746 "IBUS2, cyclic every 100 ms, sent by GW";
CM_ SG_ 784 CIM_310_CheckSum "CIM_310_Message checksum ( 0xC8)CIM_310_CheckSum";
CM_ SG_ 784 CIM_310_AliveCounter "CIM_310_Message counterCIM_310_AliveCounter";
CM_ SG_ 784 CIM_TurnLampSwtSts "Turn signal lamp switch stateturn signal lever status.";
CM_ SG_ 784 CIM_HiBeamSwtSts "High beam switch stateHigh beam switch status.";
CM_ SG_ 784 CIM_FrntWshrSwtSts "Status of front washer switchWasherFrontCommand.";
CM_ SG_ 784 CIM_FrntWiprSwtSts "Front wiper wiper switch stateWiper front command.";
CM_ BO_ 784 "IBUS2, cyclic every 20 ms, sent by GW";
CM_ SG_ 785 ADAS_311_CheckSum "ADAS_0x311_message checksum (E2E data ID: 0x4F)";
CM_ SG_ 785 ADAS_311_AliveCounter "ADAS_311_Message counter";
CM_ SG_ 785 ADAS_HiPrioDegradationSts "ADAS high priority feature degradation status, used to popup a window on central display when the feature reaches the safe state";
CM_ SG_ 785 ADAS_ISA_PerSpdLim_req "Signal to notify the driver for the speed limit change between SLIF percieved speed limit and Speedometer speed.";
CM_ SG_ 785 ADAS_LoPrioDegradationSts "ADAS low priority feature degradation status, used to popup a window on central display when the feature reaches the safe state";
CM_ SG_ 785 ADAS_SpeedLimitUnit "Change speed Unit (kmh /Mph)";
CM_ SG_ 785 ADAS_ISA_SpdLmt "ISA detected speed limit + user selected offset";
CM_ SG_ 785 ADAS_TSRSpeedLimitAddOn "TSR speed limit add on";
CM_ SG_ 785 ADAS_TSRSpeedLimit "TSR speed limit";
CM_ BO_ 785 "IBUS2, cyclic every 20 ms, sent by GW";
CM_ SG_ 787 ADAS_313_CheckSum "ADAS_313_Message checksum ( E2E data ID: 0x4B)";
CM_ SG_ 787 ADAS_313_AliveCounter "ADAS_313_Message counter";
CM_ SG_ 787 ADAS_BACM_Sts "BACM status";
CM_ SG_ 787 AEB_ReAEB_Sts "Status of Rear AEB function";
CM_ SG_ 787 ADAS_Sts_ACC_ICC "Automatic Cruise Control (ACC) status";
CM_ SG_ 787 ADAS_TJA_AutoSteerSts "Traffic Jam Assist (TJA) autosteer status";
CM_ SG_ 787 ADAS_ISASts "ISA status_for ICC use to display either fault and confirm on_off";
CM_ SG_ 787 ADAS_Sts_TLR "TLR status";
CM_ SG_ 787 ADAS_TSRSts "TSR Information receive status ( Camera / Navi / fusion )";
CM_ BO_ 787 "IBUS2, cyclic every 20 ms, sent by GW";
CM_ SG_ 788 ADAS_314_CheckSum "ADAS_314_Message checksum ( E2E data ID:0x4E)";
CM_ SG_ 788 ADAS_314_AliveCounter "ADAS_314_Message counter";
CM_ SG_ 788 ADAS_LKASts "This signal indicates the lane keeping system state. It is used to illuminate the lane line ego vehicle is about to cross.";
CM_ SG_ 788 ADAS_LCA_Sts "Lane Change Assist status";
CM_ SG_ 788 ADAS_LCA_Maneuver_Status "Indication to the driver when LCA maneuver is suppressed";
CM_ SG_ 788 ADAS_APASts "Advanced Park Assist (APA) status";
CM_ SG_ 788 ADAS_ELKASts "This signal indicates the emergency lane keeping system state. It is used to illuminate the lane line ego vehicle is about to cross.";
CM_ SG_ 788 ADAS_WSPPASts "Wheel Scratch Prevention feature State";
CM_ SG_ 788 ADAS_DOW_Sts "Door Open Warning (DOW) status";
CM_ SG_ 788 ADAS_BSDSts "Blind Spot Detection (BSD) feature status";
CM_ SG_ 788 ADAS_DCAASts "Driver Condition and Attention Assist (DCAA) status";
CM_ SG_ 788 ADAS_AHBA_Sts "Auto high beam status";
CM_ SG_ 788 ADAS_AHBA_BeamDecisRsn "Beam Decision Reason to request low beam or high beam For Development use only";
CM_ BO_ 788 "IBUS2, cyclic every 20 ms, sent by GW";
CM_ SG_ 789 ADAS_DOW_ThreatIDLeft "Object ID of the left threat";
CM_ SG_ 789 ADAS_DOW_ThreatIDRight "Object ID of the right threat";
CM_ SG_ 789 ADAS_DOW_CID_LeDispReq "Door Open Warning (DOW) display request on CID left side (central screen)";
CM_ SG_ 789 ADAS_DOW_CID_RiDispReq "Door Open Warning (DOW) display request on CID right side (central screen)";
CM_ SG_ 789 ADAS_BSDLeftThreatID "BSD Threat Object ID Left side";
CM_ SG_ 789 ADAS_BSDRightThreatID "BSD Threat Object ID Right Side";
CM_ SG_ 789 ADAS_BSD_CID_LeDispReq "Blind Spot Detection (BSD) display request on CID left side (central screen)";
CM_ SG_ 789 ADAS_BSD_CID_RiDispReq "Blind Spot Detection (BSD) display request on CID right side (central screen)";
CM_ SG_ 789 ADAS_DCAA_WarnLvlReq "Driver Condition and Attention Assist (DCAA) warning level request";
CM_ SG_ 789 ADAS_DCAA_GazeOnWarnReq "Driver Condition and Attention Assist (DCAA) gaze on warning request. Reserved for future development, could be the additional requirement to launch the vehicle after long ACC stop (> 3 sec)";
CM_ BO_ 789 "IBUS2, cyclic every 50 ms, sent by GW";
CM_ SG_ 790 ADASDC_SVS_ViewSts "Signal from ADAS transmitting current Surround View display view";
CM_ SG_ 790 ADASDC_SVS_AvailableSts "Reasons for SVS not available";
CM_ SG_ 790 ADASDC_SVS_RrCamBttnShw "This signal controls when the rear view camera button will be drawn on the CID.";
CM_ SG_ 790 ADASDC_SVS_WdAnglBttnShw "This signal controls when the wide angle camera view toggle button will be drawn on the CID.";
CM_ SG_ 790 ADASDC_SVS_FrntWdAnglBttnShw "This signal controls when the front wide angle camera view button will be drawn on the CID.";
CM_ SG_ 790 ADASDC_SVS_3DCamBttnShw "This signal controls when the 3D camera view button will be drawn on the CID.";
CM_ SG_ 790 ADASDC_SVS_AutoVwBttnShw "This signal controls when the automatic camera view button will be drawn on the CID.";
CM_ SG_ 790 ADASDC_SVS_RearMidBttnShw "Propose this CAN signal to enable the rear button on birdseye view";
CM_ SG_ 790 ADASDC_SVS_FrntMidBttnShw "Propose this CAN signal to enable the Front button on birdseye view";
CM_ SG_ 790 ADASDC_SVS_SplitBttnShw "Propose this CAN signal to enable the split curb button on birdseye view";
CM_ SG_ 790 ADASDC_SVS_LeftFlnk3DBttnShw "Propose this CAN signal to enable the Left Flank button on birdseye view";
CM_ SG_ 790 ADASDC_SVS_RightFlnk3DBttnShw "Propose this CAN signal to enable the right Flank button on birdseye view";
CM_ SG_ 790 ADASDC_SVS_ShowReq "Request from ADAS to show SVS on screen";
CM_ BO_ 790 "IBUS2, cyclic every 50 ms, sent by GW";

BA_DEF_ BO_ "GenMsgCycleTime" INT 0 65535;
BA_DEF_DEF_ "GenMsgCycleTime" 0;
BA_ "GenMsgCycleTime" BO_ 1141 100;
BA_ "GenMsgCycleTime" BO_ 1170 100;
BA_ "GenMsgCycleTime" BO_ 1264 100;
BA_ "GenMsgCycleTime" BO_ 1265 100;
BA_ "GenMsgCycleTime" BO_ 1267 100;
BA_ "GenMsgCycleTime" BO_ 1269 100;
BA_ "GenMsgCycleTime" BO_ 1272 100;
BA_ "GenMsgCycleTime" BO_ 1273 200;
BA_ "GenMsgCycleTime" BO_ 1287 100;
BA_ "GenMsgCycleTime" BO_ 1298 100;
BA_ "GenMsgCycleTime" BO_ 1300 50;
BA_ "GenMsgCycleTime" BO_ 1304 100;
BA_ "GenMsgCycleTime" BO_ 1310 100;
BA_ "GenMsgCycleTime" BO_ 1314 100;
BA_ "GenMsgCycleTime" BO_ 1315 100;
BA_ "GenMsgCycleTime" BO_ 1316 100;
BA_ "GenMsgCycleTime" BO_ 1320 100;
BA_ "GenMsgCycleTime" BO_ 1321 100;
BA_ "GenMsgCycleTime" BO_ 1329 100;
BA_ "GenMsgCycleTime" BO_ 1330 100;
BA_ "GenMsgCycleTime" BO_ 1331 100;
BA_ "GenMsgCycleTime" BO_ 1364 100;
BA_ "GenMsgCycleTime" BO_ 1379 200;
BA_ "GenMsgCycleTime" BO_ 1400 500;
BA_ "GenMsgCycleTime" BO_ 1401 500;
BA_ "GenMsgCycleTime" BO_ 1402 500;
BA_ "GenMsgCycleTime" BO_ 1403 500;
BA_ "GenMsgCycleTime" BO_ 1404 500;
BA_ "GenMsgCycleTime" BO_ 1413 50;
BA_ "GenMsgCycleTime" BO_ 1415 200;
BA_ "GenMsgCycleTime" BO_ 1416 500;
BA_ "GenMsgCycleTime" BO_ 1480 100;
BA_ "GenMsgCycleTime" BO_ 1514 500;
BA_ "GenMsgCycleTime" BO_ 1552 1000;
BA_ "GenMsgCycleTime" BO_ 1583 1000;
BA_ "GenMsgCycleTime" BO_ 1649 1000;
BA_ "GenMsgCycleTime" BO_ 1652 1000;
BA_ "GenMsgCycleTime" BO_ 1653 1000;
BA_ "GenMsgCycleTime" BO_ 1672 50;
BA_ "GenMsgCycleTime" BO_ 1675 1000;
BA_ "GenMsgCycleTime" BO_ 1696 500;
BA_ "GenMsgCycleTime" BO_ 1757 1000;
BA_ "GenMsgCycleTime" BO_ 1760 5000;
BA_ "GenMsgCycleTime" BO_ 233 20;
BA_ "GenMsgCycleTime" BO_ 261 20;
BA_ "GenMsgCycleTime" BO_ 279 10;
BA_ "GenMsgCycleTime" BO_ 280 10;
BA_ "GenMsgCycleTime" BO_ 281 20;
BA_ "GenMsgCycleTime" BO_ 416 100;
BA_ "GenMsgCycleTime" BO_ 425 100;
BA_ "GenMsgCycleTime" BO_ 438 10;
BA_ "GenMsgCycleTime" BO_ 448 10;
BA_ "GenMsgCycleTime" BO_ 522 50;
BA_ "GenMsgCycleTime" BO_ 523 50;
BA_ "GenMsgCycleTime" BO_ 524 50;
BA_ "GenMsgCycleTime" BO_ 525 50;
BA_ "GenMsgCycleTime" BO_ 526 50;
BA_ "GenMsgCycleTime" BO_ 527 50;
BA_ "GenMsgCycleTime" BO_ 528 50;
BA_ "GenMsgCycleTime" BO_ 533 20;
BA_ "GenMsgCycleTime" BO_ 566 20;
BA_ "GenMsgCycleTime" BO_ 586 20;
BA_ "GenMsgCycleTime" BO_ 592 100;
BA_ "GenMsgCycleTime" BO_ 593 100;
BA_ "GenMsgCycleTime" BO_ 594 100;
BA_ "GenMsgCycleTime" BO_ 597 100;
BA_ "GenMsgCycleTime" BO_ 617 20;
BA_ "GenMsgCycleTime" BO_ 711 100;
BA_ "GenMsgCycleTime" BO_ 714 100;
BA_ "GenMsgCycleTime" BO_ 717 100;
BA_ "GenMsgCycleTime" BO_ 720 100;
BA_ "GenMsgCycleTime" BO_ 723 100;
BA_ "GenMsgCycleTime" BO_ 726 100;
BA_ "GenMsgCycleTime" BO_ 729 100;
BA_ "GenMsgCycleTime" BO_ 732 100;
BA_ "GenMsgCycleTime" BO_ 735 100;
BA_ "GenMsgCycleTime" BO_ 738 100;
BA_ "GenMsgCycleTime" BO_ 741 100;
BA_ "GenMsgCycleTime" BO_ 744 100;
BA_ "GenMsgCycleTime" BO_ 745 100;
BA_ "GenMsgCycleTime" BO_ 746 100;
BA_ "GenMsgCycleTime" BO_ 784 20;
BA_ "GenMsgCycleTime" BO_ 785 20;
BA_ "GenMsgCycleTime" BO_ 787 20;
BA_ "GenMsgCycleTime" BO_ 788 20;
BA_ "GenMsgCycleTime" BO_ 789 50;
BA_ "GenMsgCycleTime" BO_ 790 50;
VAL_ 1141 EPS_PwrSplyOverVoltFlt 0 "Normal" 1 "Abnormal" ;
VAL_ 1141 EPS_PwrSplyUnderVoltFlt 0 "Normal" 1 "Abnormal" ;
VAL_ 1141 EPS_SnsrSplyVoltFlt 0 "Normal" 1 "Abnormal" ;
VAL_ 1141 EPS_MotShoOpenFlt 0 "Normal" 1 "Abnormal" ;
VAL_ 1141 EPS_ThermProtnFlt 0 "Normal" 1 "Abnormal" ;
VAL_ 1141 EPS_NVMFlt 0 "Normal" 1 "Abnormal" ;
VAL_ 1141 EPS_RunngRstFlt 0 "Normal" 1 "Abnormal" ;
VAL_ 1141 EPS_ModSts 0 "Normal" 1 "ECO" 2 "Sport" 3 "Invalid" ;
VAL_ 1264 PKC_RemCtrlWinCmd 0 "Inactive" 1 "Up" 2 "Down" 3 "Reserved" ;
VAL_ 1264 PKC_PollingSts 0 "Inactive" 1 "Active" ;
VAL_ 1264 PKC_PollingFctCmd 0 "Initial/Welcome_Light_0ff" 1 "Welcome_Light_On" 4 "Lock" 5 "Unlock" ;
VAL_ 1264 PKC_KeyLocation 0 "Unknown" 1 "Outside" 2 "Inside" 3 "Outside_Driver_Side" 4 "Outside_Passenger_Side" 5 "Inside_Driver_Seat" 6 "Inside_Passenger_Sea" 7 "Outside_Trunk" 8 "Inside_Trunk" 15 "Invalid" ;
VAL_ 1264 PKC_UsrStopCharCmd 0 "Initial" 1 "do_not_terminate_charging_command" 2 "End_charging_instruction" 3 "Invalid" ;
VAL_ 1264 PKC_SpdLim 255 "no_speed_limit" ;
VAL_ 1264 PKC_RemClsSunroofCtrlCmd 127 "Invalid" ;
VAL_ 1265 DSMC_DrvrSeatTrackSwtSts 0 "Off" 1 "Fwd" 2 "Rwd" 3 "Defect" ;
VAL_ 1265 DSMC_DrvrSeatHeiAdjSwtSts 0 "Off" 1 "Up" 2 "Down" 3 "Defect" ;
VAL_ 1265 DSMC_DrvrSeatBackAdjSwtSts 0 "Off" 1 "Fwd" 2 "Rwd" 3 "Defect" ;
VAL_ 1265 DSMC_OTARdy_Fb 0 "Initial" 1 "Ready" 2 "Not_Ready" 3 "Invalid" ;
VAL_ 1267 DSMC_RiMirrrXDircAdjSts 0 "Off" 1 "Left" 2 "Right" 3 "Defect" ;
VAL_ 1267 DSMC_RiMirrrYDircAdjSts 0 "Off" 1 "Down" 2 "Up" 3 "Defect" ;
VAL_ 1267 DSMC_LeMirrrXDircAdjSts 0 "Off" 1 "Left" 2 "Right" 3 "Defect" ;
VAL_ 1267 DSMC_LeMirrrYDircAdjSts 0 "Off" 1 "Down" 2 "Up" 3 "Defect" ;
VAL_ 1272 TBOX_Sw_upd 0 "Initial" 1 "Flashing" 2 "Coding" 3 "Invalid" ;
VAL_ 1272 TBOX_Flsflg 0 "Initial_Value" 1 "HV_Flash_Mode" 2 "LV_Flash_Mode" 3 "HV_Light_Flash_Mode" 7 "Invalid" ;
VAL_ 1272 TBOX_RemFlsh 0 "Without_Request" 1 "RemFlash_Req_Active" 2 "RemCoding_Req_Active" 3 "Precheck_Req_Active" 7 "Invalid" ;
VAL_ 1272 TBOX_FobdGWPartBUSUDSCom 0 "Initial_value" 1 "Not_allowed" 2 "Recovery" 3 "Void" ;
VAL_ 1272 TBOX_RemChrgInsulFctReq 0 "No_action" 1 "On" 2 "Off" 3 "Reserved" ;
VAL_ 1272 TBOX_EHUSetTrvlMod 0 "Initial_value" 1 "Daily_commuter_mode" 2 "Long-distance_travel_mode" 3 "Reserved" ;
VAL_ 1272 TBOX_ResvACChrgOpenSts 0 "Initial_value" 1 "On" 2 "Off" 3 "Reserved" ;
VAL_ 1272 TBOX_RemKL15PwrOnReq 0 "Init_value" 1 "Request" 2 "No_Request" 3 "Invalid" ;
VAL_ 1272 TBOX_PreCondTriggerReq 0 "no_trigger" 1 "Start_Precond._Battery" 2 "Start_Precond._Battery_+_Cabin" 3 "Start_Precond._Cabin" 4 "Stop_Precond." ;
VAL_ 1272 TBOX_BlowLvlReq 0 "off" 1 "Step1" 2 "Step2" 3 "Step3" 4 "Step4" 5 "Step5" 6 "Step6" 7 "Step7" ;
VAL_ 1272 TBOX_ICC_UpdStrt 0 "Initial_Value" 1 "With_Request" 2 "Reserved" ;
VAL_ 1272 TBOX_VehiMod 0 "Default_Mode" 1 "California_mode" 2 "Pet_mode" 3 "Camping_mode" 4 "Mode4" 5 "Mode5" 6 "Mode6" 7 "Mode7" 8 "Mode8" 9 "Mode9" 10 "Mode10" 11 "Mode11" 12 "Mode12" 13 "Mode13" 14 "Mode14" 15 "Mode15" ;
VAL_ 1272 TBOX_Crash_cfm 0 "No_Crash" 1 "Crash_Happened" 2 "Reserved" 3 "Invalid" ;
VAL_ 1272 TBOX_SchedChrgnReq 0 "Scheduled_Charging_Req_Inactive" 1 "Scheduled_Charging_Req_Active" 2 "Reserved" 3 "Invalid" ;
VAL_ 1273 TBOX_OTAResFb 0 "OTA_no_request" 1 "OTA_on_going" 2 "OTA_completed" 3 "OTA_rollback_completed" 4 "OTA_error" 7 "Invalid" ;
VAL_ 1273 TBOX_SpdLim 255 "no_speed_limit" ;
VAL_ 1273 TBOX_OTA_TiRng 65535 "Invalid" ;
VAL_ 1287 VCU_OTAVehInhb_QM_Fb 0 "OTA_veh_cond_not_ok" 1 "OTA_veh_cond_ok" 2 "Fault" 3 "Invalid" ;
VAL_ 1287 VCU_OTAVehCdnChk_QM_sts 0 "OTA_veh_cond_not_ok" 1 "OTA_veh_cond_ok" 2 "Fault" 3 "Invalid" ;
VAL_ 1287 VCU_DrvAvl 0 "Invalid" 1 "Valid" ;
VAL_ 1287 VCU_CllsnSigSts 0 "Not_collided" 1 "Collided" ;
VAL_ 1287 VCU_VehSts_GB 0 "Initial_value" 1 "Vehicle_starting" 2 "Flameout" 3 "Other_states" ;
VAL_ 1287 VCU_MCUOverTFlt_GB 0 "Normal" 1 "Abnormal" ;
VAL_ 1287 VCU_DrvrMotOverTFlt_GB 0 "Normal" 1 "Abnormal" ;
VAL_ 1287 VCU_SOCTooLoAlrm 0 "No_fault" 1 "faulty" ;
VAL_ 1287 VCU_SOCJumpAlrm 0 "No_fault" 1 "faulty" ;
VAL_ 1287 VCU_PwrBattPackMismatAlrm 0 "No_fault" 1 "faulty" ;
VAL_ 1287 VCU_SOCTooHiAlrm 0 "No_fault" 1 "faulty" ;
VAL_ 1287 VCU_DCDCEnaCmd 0 "Disable" 1 "Enable" ;
VAL_ 1287 VCU_PwrBattECCEnaCmd 0 "Disable" 1 "Enable" ;
VAL_ 1287 VCU_MstRlyCtrlCmd 0 "Disconnect" 1 "Closed" ;
VAL_ 1287 VCU_GearSig_GB 0 "Neutral" 1 "1st_gear" 2 "2nd_gear" 3 "3rd_gear" 4 "4th_gear" 5 "5th_gear" 6 "6th_gear" 13 "Reverse_gear" 14 "automatic_D_gear" 15 "parking_gear_P" ;
VAL_ 1287 VCU_DrvrMotNr_GB 0 "Initial_value" 1 "1" 2 "2" 3 "3" 4 "4_pieces" ;
VAL_ 1287 VCU_BattVolt 65535 "Invalid" ;
VAL_ 1298 PSM_PassSeatHeatgSts 0 "Reserved" 1 "High" 2 "Med" 3 "Low" 4 "Off" ;
VAL_ 1298 PSM_PassSeatVentnSts 0 "Not_Change" 1 "High" 2 "Med" 3 "Low" 4 "Off" ;
VAL_ 1298 PSM_PassSeatTrackAdjSts 0 "Off" 1 "Fwd" 2 "Rwd" 3 "Defect" ;
VAL_ 1298 PSM_PassSeatBackAdjSts 0 "Off" 1 "Fwd" 2 "Rwd" 3 "Defect" ;
VAL_ 1298 PSM_OTARdy_Fb 0 "Initial" 1 "Ready" 2 "Not_Ready" 3 "Invalid" ;
VAL_ 1300 MFS_LeBtnNorth 0 "No_Pressed" 1 "Pressed" 2 "Long_Press" 3 "Reserved" ;
VAL_ 1300 MFS_LeBtnSouth 0 "No_Pressed" 1 "Pressed" 2 "Long_Press" 3 "Reserved" ;
VAL_ 1300 MFS_LeBtnWest 0 "No_Pressed" 1 "Pressed" 2 "Long_Press" 3 "Reserved" ;
VAL_ 1300 MFS_LeBtnEast 0 "No_Pressed" 1 "Pressed" 2 "Long_Press" 3 "Reserved" ;
VAL_ 1300 MFS_LeRollUp 0 "No_Pressed_Not_pressed" 1 "1_unit_up_focus" 2 "2_units_focus_up" 3 "3_units_up_focus" 4 "4_units_focus_up" 5 "5_units_focus_up" 6 "6_units_in_focus_up" 7 "7_units_up_focus" ;
VAL_ 1300 MFS_LeRollDwn 0 "No_Pressed_Not_pressed" 1 "Focus_1_unit_down" 2 "Focus_by_2_units" 3 "Focus_3_units_down" 4 "4_units_down_focus" 5 "Focus_down_5_units" 6 "Focus_down:6_units" 7 "Focus_7_units_down" ;
VAL_ 1300 MFS_LeRollPress 0 "No_Pressed" 1 "Pressed" ;
VAL_ 1300 MFS_RiBtnNorth 0 "No_Pressed" 1 "Pressed" 2 "Long_Press" 3 "Reserved" ;
VAL_ 1300 MFS_RiBtnSouth 0 "No_Pressed" 1 "Pressed" 2 "Long_Press" 3 "Reserved" ;
VAL_ 1300 MFS_RiBtnWest 0 "No_Pressed" 1 "Pressed" 2 "Long_Press" 3 "Reserved" ;
VAL_ 1300 MFS_RiBtnEast 0 "No_Pressed" 1 "Pressed" 2 "Long_Press" 3 "Reserved" ;
VAL_ 1300 MFS_RiRollUp 0 "No_Pressed_Not_pressed" 1 "1_unit_up_focus" 2 "2_units_focus_up" 3 "3_units_up_focus" 4 "4_units_focus_up" 5 "5_units_focus_up" 6 "6_units_in_focus_up" 7 "7_units_up_focus" ;
VAL_ 1300 MFS_RiRollDwn 0 "No_Pressed_Not_pressed" 1 "Focus_1_unit_down" 2 "Focus_by_2_units" 3 "Focus_3_units_down" 4 "4_units_down_focus" 5 "Focus_down_5_units" 6 "Focus_down:6_units" 7 "Focus_7_units_down" ;
VAL_ 1300 MFS_RiRollPress 0 "No_Pressed" 1 "Pressed" ;
VAL_ 1300 MFS_Ri_Fail 0 "No_failure" 1 "Connection_failure" 2 "Button_stuck" 3 "Reserved" ;
VAL_ 1300 MFS_Le_Fail 0 "No_failure" 1 "Controller_failure" 2 "Button_stuck" 3 "Reserved" ;
VAL_ 1304 DSMC_DrvrSeatHeatgSts 0 "Reserved" 1 "High" 2 "Med" 3 "Low" 4 "Off" ;
VAL_ 1304 DSMC_DrvrSeatTrackAdjSts 0 "Off" 1 "Fwd" 2 "Rwd" 3 "Defect" ;
VAL_ 1304 DSMC_DrvrSeatHeiAdjSts 0 "Off" 1 "Up" 2 "Down" 3 "Defect" ;
VAL_ 1304 DSMC_DrvrSeatBackAdjSts 0 "Off" 1 "Fwd" 2 "Rwd" 3 "Defect" ;
VAL_ 1304 DSMC_RearLeSeatHeatgSts 0 "Reserved" 1 "High" 2 "Med" 3 "Low" 4 "Off" ;
VAL_ 1304 DSMC_RearRiSeatHeatgSts 0 "Reserved" 1 "High" 2 "Med" 3 "Low" 4 "Off" ;
VAL_ 1310 BCM_ActvModDiEna 0 "Invalid" 1 "Prohibited_active_mode" 2 "Active_mode_allowed" 3 "Reserved" ;
VAL_ 1310 BCM_ApplianceClsLvl 0 "Not_closed" 1 "Closing_level_1" 2 "Off_level_2" 3 "Closing_level_3" ;
VAL_ 1310 BCM_RainSnsrSysFlt 0 "Normal" 1 "fault" ;
VAL_ 1310 BCM_SolarSnsrSysFlt 0 "Normal" 1 "fault" ;
VAL_ 1310 BCM_FogSnsrSysFlt 0 "Normal" 1 "fault" ;
VAL_ 1310 BCM_LightSnsrHwFlt_RLS 0 "Normal" 1 "fault" ;
VAL_ 1310 BCM_SolarSnsrHwFlt_RLS 0 "Normal" 1 "Abnormal" ;
VAL_ 1310 BCM_GlassSurfaceOcclusion 255 "Invalid" ;
VAL_ 1314 DSMC_IninSts 0 "Incomplete_initialization" 1 "initialization_completed" ;
VAL_ 1314 DSMC_CrtSts 0 "Normal_operating_state" 1 "Fault_state" ;
VAL_ 1314 DSMC_SteerWhlYSts 0 "Off" 1 "Fwd" 2 "Rwd" 3 "Defect" ;
VAL_ 1314 DSMC_SteerWhlZSts 0 "Off" 1 "Fwd" 2 "Rwd" 3 "Defect" ;
VAL_ 1314 DSMC_RotationReqSteerClmnFb 0 "Rotation_allowed" 1 "Rotation_not_allowed" ;
VAL_ 1315 PWC_R_ChrgSts 0 "No_Charge" 1 "Charging" 2 "Charge_Full" 3 "FOD" 4 "RxError" 5 "TxError" ;
VAL_ 1315 PWC_R_PhnForgetRemdSts 0 "No_Forget" 1 "Forget" ;
VAL_ 1315 PWC_R_ModleSwtSts 0 "Default" 1 "Module_Off" ;
VAL_ 1315 PWC_R_ChrgPhnChkSts 0 "NO_Exist" 1 "Exist" ;
VAL_ 1316 PWC_ChrgSts 0 "No_Charge" 1 "Charging" 2 "Charge_Full" 3 "FOD" 4 "RxError" 5 "TxError" ;
VAL_ 1316 PWC_PhnForgetRemdSts 0 "No_Forget" 1 "Forget" ;
VAL_ 1316 PWC_ModleSwtSts 0 "Default" 1 "Module_Off" ;
VAL_ 1316 PWC_ChrgPhnChkSts 0 "NO_Exist" 1 "Exist" ;
VAL_ 1320 ICC_RearTSetSYNC 0 "Inactive" 36 "18℃" 37 "18.5℃" 38 "19℃" 39 "19.5℃" 40 "20℃" 41 "20.5℃" 42 "21℃" 43 "21.5℃" 44 "22℃" 45 "22.5℃" 46 "23℃" 47 "23.5℃" 48 "24℃" 49 "24.5℃" 50 "25℃" 51 "25.5℃" 52 "26℃" 53 "26.5℃" 54 "27℃" 55 "27.5℃" 56 "28℃" 57 "28.5℃" 58 "29℃" 59 "29.5℃" 60 "30℃" 61 "30.5℃" 62 "31℃" 63 "31.5℃" 64 "32℃" 255 "Invalid" ;
VAL_ 1320 ICC_DrvrSeatHeatgReq 0 "Not_Change" 1 "High" 2 "Med" 3 "Low" 4 "Off" ;
VAL_ 1320 ICC_RearLeSeatHeatgSync 0 "Not_Change" 1 "High" 2 "Med" 3 "Low" 4 "Off" ;
VAL_ 1320 ICC_DrvrID 0 "Reserved(Nobody)" 1 "No_Request(Somebody)" 2 "Mem_1" 3 "Mem_2" 4 "Mem_3" 5 "Mem_4" 6 "Mem_5" 7 "Mem_6" 8 "Mem_7" 9 "Mem_8" 10 "Mem_9" 11 "Mem_10" ;
VAL_ 1320 ICC_SeatWelFctEnaReq 0 "Not_Change" 1 "Unactive" 2 "Active" 3 "Reserved" ;
VAL_ 1320 ICC_DrvAntithiefEnaReq 0 "Not_Change" 1 "Unactive" 2 "Active" 3 "Reserved" ;
VAL_ 1320 ICC_RearRiSeatHeatgSync 0 "Not_Change" 1 "High" 2 "Med" 3 "Low" 4 "Off" ;
VAL_ 1320 ICC_SWH_Req 0 "No_Request" 1 "SWH_ON" 2 "Reserved" 3 "Invalid" ;
VAL_ 1320 ICC_PassSeatHeatgReq 0 "Not_Change" 1 "High" 2 "Med" 3 "Low" 4 "Off" ;
VAL_ 1320 ICC_RearLeSeatHeatgReq 0 "Not_Change" 1 "High" 2 "Med" 3 "Low" 4 "Off" ;
VAL_ 1320 ICC_KL15PwrOffPrevFlag 0 "Init" 1 "Prevent_switching_Off_of_KL15" 2 "No_prevent_request" 3 "Invalid" ;
VAL_ 1320 ICC_RearRiSeatHeatgReq 0 "Not_Change" 1 "High" 2 "Med" 3 "Low" 4 "Off" ;
VAL_ 1320 ICC_RearAirVolSetSync 0 "Inactive" 1 "First_gear_of_wind_speed" 2 "Wind_speed_second_gear" 3 "third_gear_of_wind_speed" 4 "wind_speed_fourth_gear" 5 "Wind_speed_fifth_gear" 6 "Wind_speed_six" 7 "Wind_speed_seven_gear" 15 "windless_gear" ;
VAL_ 1321 ICC_CtrlSts_NFC 0 "Closed" 1 "Open" ;
VAL_ 1321 ICC_CtrlSts_PWC 0 "Closed" 1 "Open" ;
VAL_ 1321 ICC_DispUnit 0 "KM_(metric_km)" 1 "mi_(miles)" ;
VAL_ 1321 ICC_ReOperPanSwtCmd 0 "off" 1 "on" ;
VAL_ 1321 ICC_ReOperPanSwtSts 0 "off" 1 "on" ;
VAL_ 1321 ICC_SteerWhlPhnKeyBackLi 0 "Normal_state" 1 "Incoming_Call" 2 "Call_Bluetooth_Call_Call_Call" 3 "Reserved" ;
VAL_ 1321 ICC_BackgndBriLvl 0 "Level_0" 1 "Level_1" 2 "Level_2" 3 "Level_3" 4 "Level_4" 5 "Level_5" 6 "Level_6" 7 "Level_7" 8 "Level_8" 9 "Level_9" 10 "Level_10" ;
VAL_ 1321 ICC_TempUnit 0 "Celsius" 1 "Fahrnheit" ;
VAL_ 1321 ICC_V2G_Ena 0 "No" 1 "Yes" ;
VAL_ 1321 ICC_V2H_Ena 0 "No" 1 "Yes" ;
VAL_ 1321 ICC_V2V_Ena 0 "No" 1 "Yes" ;
VAL_ 1321 ICC_V2L_ChrgPortEna 0 "No" 1 "Yes" ;
VAL_ 1321 ICC_V2L_TrEna 0 "No" 1 "Yes" ;
VAL_ 1321 ICC_ReOperPanLockCmd 0 "Not_ON" 1 "On" ;
VAL_ 1321 ICC_RollingCounter 0 "0" 1 "1" 2 "2" 3 "3" 4 "4" 5 "5" 6 "6" 7 "7" 8 "8" 9 "9" 10 "10" 11 "11" 12 "12" 13 "13" 14 "14" 15 "15" ;
VAL_ 1321 ICC_WiprSrvPosn 0 "Inactive" 1 "On" 2 "Off" 3 "Reserved" ;
VAL_ 1321 ICC_SpclTerrainModReq 0 "Initial_value" 1 "All_terrain_mode_OFF" 2 "Snow_mode_request" 3 "Mud_mode_request" 4 "Sand_mode_request" ;
VAL_ 1321 ICC_NavOnSts 0 "Guisance_Active" 1 "Guisance_Inactive" ;
VAL_ 1321 ICC_DoorCtrlSwtSts 0 "Default" 1 "Inactive" 2 "Active" 3 "Reserved" ;
VAL_ 1321 ICC_CrtLanguage 0 "English_(US)" 1 "Spanish_(MX)" 2 "French_(CA)" 3 "English_(CA)" 4 "English_(GB)" 5 "German_(DE)" 6 "German_(AUS)" 7 "Norwegian" 8 "Sami" 9 "Swedish" 10 "Danish" 11 "French_(FR)" 12 "Dutch_(NL)" 13 "Dutch_(B)" 14 "Spanish_(SP)" 15 "Italian" 16 "Portuguese" 17 "Polish" 18 "Russian" 19 "Turkish" 20 "Japanese" 21 "Mandarin_(Modern)" 22 "Mandarin_(Traditional)" 23 "Cantonese" 24 "English_(AUS)" 25 "Hebrew" 26 "Arabic" 27 "Korean" 28 "Hindi" ;
VAL_ 1321 ICC_NavBarShift 0 "No_Display" ;
VAL_ 1328 ICC_DrvrTSet 0 "Inactive" 36 "18℃" 37 "18.5℃" 38 "19℃" 39 "19.5℃" 40 "20℃" 41 "20.5℃" 42 "21℃" 43 "21.5℃" 44 "22℃" 45 "22.5℃" 46 "23℃" 47 "23.5℃" 48 "24℃" 49 "24.5℃" 50 "25℃" 51 "25.5℃" 52 "26℃" 53 "26.5℃" 54 "27℃" 55 "27.5℃" 56 "28℃" 57 "28.5℃" 58 "29℃" 59 "29.5℃" 60 "30℃" 61 "30.5℃" 62 "31℃" 63 "31.5℃" 64 "32℃" 255 "Invalid" ;
VAL_ 1328 ICC_PassTSet 0 "Inactive" 36 "18℃" 37 "18.5℃" 38 "19℃" 39 "19.5℃" 40 "20℃" 41 "20.5℃" 42 "21℃" 43 "21.5℃" 44 "22℃" 45 "22.5℃" 46 "23℃" 47 "23.5℃" 48 "24℃" 49 "24.5℃" 50 "25℃" 51 "25.5℃" 52 "26℃" 53 "26.5℃" 54 "27℃" 55 "27.5℃" 56 "28℃" 57 "28.5℃" 58 "29℃" 59 "29.5℃" 60 "30℃" 61 "30.5℃" 62 "31℃" 63 "31.5℃" 64 "32℃" 255 "Invalid" ;
VAL_ 1328 ICC_VSPVoiceTypSwt 0 "Sound_I" 1 "Sound_II" ;
VAL_ 1328 ICC_ECCAUTOReq 0 "Inactive" 1 "Active" ;
VAL_ 1328 ICC_DrvrSYNCReq 0 "Inactive" 1 "Active" ;
VAL_ 1328 ICC_ACSwtReq 0 "Inactive" 1 "Active" ;
VAL_ 1328 ICC_AirVolSet 0 "Inactive" 1 "First_gear_of_wind_speed" 2 "Wind_speed_second_gear" 3 "third_gear_of_wind_speed" 4 "wind_speed_fourth_gear" 5 "Wind_speed_fifth_gear" 6 "Wind_speed_six" 7 "Wind_speed_seven_gear" 15 "windless_gear" ;
VAL_ 1328 ICC_ECCIntExtCircReq 0 "Inactive" 1 "Active" ;
VAL_ 1328 ICC_AirClnSwtReq 0 "Closing_request" 1 "Opening_request" ;
VAL_ 1328 ICC_MaxFrntDefrstSet 0 "No_request" 1 "Switching_request" ;
VAL_ 1328 ICC_VSPCtrlCmd 0 "Disable_disabled" 1 "Enable_Enable" ;
VAL_ 1328 ICC_NavCtryCod 255 "Invalid" ;
VAL_ 1328 ICC_NavRoadTyp 15 "Invalid" ;
VAL_ 1328 ICC_NavSpdLimUnit 0 "Unknown" 1 "MPH" 2 "KMH" 3 "Reserved" ;
VAL_ 1328 ICC_NavSpdLimSts 0 "SL_Unknown" 1 "SL_Exists" 2 "SL_Nolimit" 3 "SL_Plural" ;
VAL_ 1328 ICC_NavSpdLim 0 "No_Display" 1 "SPL_5" 2 "SPL_10" 3 "SPL_15" 4 "SPL_20" 5 "SPL_25" 26 "SPL_130" ;
VAL_ 1328 ICC_BlowWinBtn 0 "Inactive" 1 "Pressed" ;
VAL_ 1328 ICC_NavSpdLimExitDst 255 "Invalid" ;
VAL_ 1329 ICC_TotMilgVld_ODO 0 "Value_OK" 1 "Value_Unreliable" ;
VAL_ 1329 ICC_DispVehSpdUnit 0 "KMH" 1 "MPH" ;
VAL_ 1329 ICC_ADASSigFlt 0 "No_Failure" 1 "Reversible_Failure" 2 "Irrversible_Failure" 3 "Reserved" ;
VAL_ 1329 ICC_DispFlt 0 "No_Error_No_error" 1 "Error_error" ;
VAL_ 1329 ICC_WorkshopMode 0 "Init" 1 "Active" 2 "Inactive" 3 "Invalid" ;
VAL_ 1330 ICC_MilgDataVld_ODO 0 "Value_OK" 1 "Value_Unreliable" ;
VAL_ 1330 ICC_MilgRstCntr_ODO 0 "Not_cleared" 1 "1_clearing" 2 "Clean_2_times" 3 "Clean_3_times" ;
VAL_ 1331 ICC_DrvrSeatTrackManReq 0 "Off" 1 "Fwd" 2 "Rwd" 3 "Reserved" ;
VAL_ 1331 ICC_DrvrSeatTiltManReq 0 "Off" 1 "Up" 2 "Down" 3 "Reserved" ;
VAL_ 1331 ICC_DrvrHeiManReq 0 "Off" 1 "Up" 2 "Down" 3 "Reserved" ;
VAL_ 1331 ICC_DrvrSeatBackManReq 0 "Off" 1 "Fwd" 2 "Rwd" 3 "Reserved" ;
VAL_ 1331 ICC_PassSeatTrackManReq 0 "Off" 1 "Fwd" 2 "Rwd" 3 "Reserved" ;
VAL_ 1331 ICC_PassSeatBackManReq 0 "Off" 1 "Fwd" 2 "Rwd" 3 "Reserved" ;
VAL_ 1331 ICC_LumbarUpd 0 "Release" 1 "Press" ;
VAL_ 1331 ICC_LumbarDwn 0 "Release" 1 "Press" ;
VAL_ 1331 ICC_LumbarFwd 0 "Release" 1 "Press" ;
VAL_ 1331 ICC_LumbarBackw 0 "Release" 1 "Press" ;
VAL_ 1331 ICC_AutoPassSeatVentnEna 0 "Void" 1 "Turn_on_automatic_ventilation_for_high_air_volume" 2 "Turn_on_automatic_ventilation_medium_air_volume" 3 "Turn_on_automatic_ventilation_for_low_air_volume" 4 "turn_off_automatic_ventilation" ;
VAL_ 1331 ICC_AutoPassSeatHeatEna 0 "Void" 1 "automatic_heating_high_temperature_position_ON" 2 "Switch_automatic_heating_medium_temperature_gear_on" 3 "Switch_automatic_heating_to_low_temperature" 4 "Turn_off_automatic_heating" ;
VAL_ 1331 ICC_AutoDrvrSeatVentnEna 0 "void" 1 "Turn_on_automatic_ventilation_for_high_air_volume" 2 "Turn_on_automatic_ventilation_medium_air_volume" 3 "Turn_on_automatic_ventilation_for_low_air_volume" 4 "turn_off_automatic_ventilation" ;
VAL_ 1331 ICC_AutoDrvrSeatHeatEna 0 "Void" 1 "automatic_heating_high_temperature_position_ON" 2 "Switch_automatic_heating_medium_temperature_gear_on" 3 "Switch_automatic_heating_to_low_temperature" 4 "Turn_off_automatic_heating" ;
VAL_ 1332 ICC_MinChrgSoc_Setting 254 "Minimum_Charge_Not_Actived" 255 "Invalid" ;
VAL_ 1332 ICC_PwrBattDrvgHeatSwtSts 0 "Off_state" 1 "On_state" ;
VAL_ 1332 ICC_DrvrBlowFaceBtn 0 "Inactive" 1 "Pressed" ;
VAL_ 1332 ICC_PassBlowFacetBtn 0 "Inactive" 1 "Pressed" ;
VAL_ 1332 ICC_DrvrBlowFootBtn 0 "Inactive" 1 "Pressed" ;
VAL_ 1332 ICC_PassBlowFootBtn 0 "Inactive" 1 "Pressed" ;
VAL_ 1332 ICC_BackRowAirOutlModReq 0 "Inactive" 1 "Rear_face_blowing" 2 "Face_blowing_foot_blowing_of_rear_row" 3 "Rear_row_foot_blowing" 4 "Rear_row_cutoff" ;
VAL_ 1332 ICC_DchaBtnAvlFlg 0 "Not_pressed" 1 "pressed" ;
VAL_ 1332 ICC_ECCSysSwtCmd 0 "Inactive" 1 "Air_conditioning_power_on_(Short)" 2 "Air_conditioning_shutdown_(Long)" 3 "Reserved" ;
VAL_ 1332 ICC_DrvrBlowModReq 0 "Inactive" 1 "driver_face_blowing_mode" 2 "driver_face_blowing/foot_blowing_mode" 3 "Driver_foot_blowing_mode" 4 "driver_foot/window_mode" 5 "Window_blowing_mode" ;
VAL_ 1332 ICC_PassBlowModReq 0 "Inactive" 1 "front_passenger_face_blowing_mode" 2 "front_passenger_face_blowing/foot_blowing_mode" 3 "Front_passenger_foot_mode" 4 "Front_passenger_foot/window_mode" ;
VAL_ 1364 VCU_PwrGridBreakFlg 0 "Not_power_off" 1 "power_off" ;
VAL_ 1364 VCU_ACChrgDchaIndcrLampSts 0 "off" 1 "White_(illumination/half_connection)" 2 "green_(fully_connected_without_charge_and_discharge)" 3 "Green_Breath_(AC_charging)" 4 "Blue_(charging_complete)" 5 "Orange_(charging_fault)" 6 "Purple_(Discharging_process_started)" 7 "Aqua_Blue_(Discharging_process_stopped)" ;
VAL_ 1364 VCU_VCUWakeUpSig 0 "Not_waken_up" 1 "Waken_up" ;
VAL_ 1364 VCU_DCChrgDchaIndcrLampSts 0 "off" 1 "White_(illumination/half_connection)" 2 "green_(fully_connected_without_charge_and_discharge)" 3 "Green_Breath_(DC_charging)" 4 "Blue_(charging_complete)" 5 "Orange_(charging_fault)" 6 "Purple_(Discharging_process_started)" 7 "Aqua_Blue_(Discharging_process_stopped)" ;
VAL_ 1364 VCU_PrplsnEPwrReq 16383 "Invalid" ;
VAL_ 1364 VCU_HVBattActPwr 16383 "Invalid" ;
VAL_ 1379 ICC_CID_Pos_Learn 0 "no_action" 1 "learn_position_as_0°" 2 "Learn_position_as_-90°" 3 "Learn_postion_as_+90°" 4 "Learn_position_as_180°" ;
VAL_ 1379 ICC_CID_Command_Valid 0 "not_valid" 1 "valid" ;
VAL_ 1404 VCU_ActEgyCnsTyp 0 "Default" 1 "Active_(Power_consumption_W)" 2 "Inactive_(energy_consumption_Wh_per_km)" 3 "Invalid" ;
VAL_ 1413 FloatingButtons_LeT 0 "No_pressed" 1 "Up" 2 "DOWN" 3 "Long_Press_Up" 4 "Long_Press_Down" 5 "BOTH(UP_&_Down)" 6 "Reserved" 7 "Signal_invalid" ;
VAL_ 1413 FloatingButtons_LEDsFail1 0 "No_failure" 1 "Failure" ;
VAL_ 1413 FloatingButtons_RiT 0 "No_pressed" 1 "Up" 2 "DOWN" 3 "Long_Press_Up" 4 "Long_Press_Down" 5 "BOTH(UP_&_Down)" 6 "Reserved" 7 "Signal_invalid" ;
VAL_ 1413 FloatingButtons_FanCtrl 0 "No_pressed" 1 "Up" 2 "DOWN" 3 "Long_Press_Up" 4 "Long_Press_Down" 5 "BOTH(UP_&_Down)" 6 "Reserved" 7 "Signal_invalid" ;
VAL_ 1413 FloatingButtons_ButnsFail2 0 "No_failure" 1 "Failure" ;
VAL_ 1413 FloatingButtons_HomeButnFail3 0 "No_failure" 1 "Failure" ;
VAL_ 1413 FloatingButtons_VolCtrl 0 "No_pressed" 1 "Up" 2 "DOWN" 3 "Long_Press_Up" 4 "Long_Press_Down" 5 "BOTH(UP_&_Down)" 6 "Reserved" 7 "Signal_invalid" ;
VAL_ 1413 FloatingButtons_HomeCtrl 0 "not_pressed" 1 "Press" 2 "Long_press" 3 "Signal_invalid" ;
VAL_ 1415 Rotator_ECUSts 0 "Idle" 1 "Rotating_clockwise" 2 "Invalid_command" 3 "Stuck" 4 "Rotating_counterclockwise" ;
VAL_ 1415 Rotator_PosVld 0 "invalid" 1 "valid" ;
VAL_ 1415 Rotator_Pos_rotator 0 "init" 1 "0_degree" 2 "+90_degree" 7 "Invalid" ;
VAL_ 1415 Rotator_OpticSnsrFlt 0 "None" 1 "Fail_High" 2 "Fail_Low" 3 "Invalid" ;
VAL_ 1415 Rotator_HallSnsrFlt 0 "None" 1 "Fail_High" 2 "Fail_Low" 3 "Invalid" ;
VAL_ 1415 Rotator_RotationReqSteerClmn 0 "no_rotation" 1 "Rotation_request" ;
VAL_ 1416 VSP_SwtInpIndcrLampSts 0 "Indicator_Off_(VSP_Enable)_indicator_off" 1 "Indicator_On_(VSP_Disable)_indicator_on" ;
VAL_ 1416 VSP_SwtOutpSts 0 "No_Output_No_input" 1 "Outputting_has_input" ;
VAL_ 1416 VSP_WngSts 0 "Initalisation_initialization" 1 "Working_Status" 2 "Fault_Status_Fault_state" 3 "Stall_Status_Stall_Status" ;
VAL_ 1416 VSP_VoiceTypFb 0 "Sound_I" 1 "Sound_II" ;
VAL_ 1416 VSP_HornWngSts 0 "Speaker_Not_Working_horn_not_ringing" 1 "Speaker_Is_Working_Horn" ;
VAL_ 1416 VSP_WngMod 0 "Not_Work_Inoperative" 1 "Forward_Driving_Vehicle_Sound_Low-speed_Pedestrian_Warning" 2 "Reverse_Warning_Reverse_gear_prompt" 3 "Anti-theft_Alarm_Parking_anti-theft_alarm" 4 "Unlock_Warning_Unlock_Prompt" 5 "Lock_Warning_Prompt" 6 "Lock_Failure_Warning_Lock_abnormal_prompt" 7 "Fast/Slow_Charge_Warning_Prompt" 8 "Remote_Vehicle_Control_remote_body_control_prompt" 9 "Remote_Car_Search_Warning_APP_Vehicle_Search_Response" 10 "Remote_Driving_Warning" ;
VAL_ 1416 VSP_OTARdy_Fb 0 "Initial" 1 "Ready" 2 "Not_Ready" 3 "Invalid" ;
VAL_ 1450 TBOX_Wifi_ConnectSts 0 "Default" 1 "Connection_Sucessful" 2 "Connection_Unsucessful" 3 "Reserved" ;
VAL_ 1450 TBOX_Wifi_ConnectStrgthSts 63 "Invalid" ;
VAL_ 1456 TBOX_Wifi_Net_NameID 255 "Invalid" ;
VAL_ 1456 TBOX_Wifi_Net_TotalMsgs 15 "Invalid" ;
VAL_ 1456 TBOX_Wifi_Net_CurrentMsgNm 15 "Invalid" ;
VAL_ 1461 ICC_Wifi_SSID_TotalMsgs 15 "Invalid" ;
VAL_ 1461 ICC_Wifi_SSID_CurrentMsgNm 15 "Invalid" ;
VAL_ 1466 ICC_Wifi_PW_TotalMsgs 15 "Invalid" ;
VAL_ 1466 ICC_Wifi_PW_CurrentMsgNm 15 "Invalid" ;
VAL_ 1471 TBOX_Wifi_Net_StrgthID 255 "Invalid" ;
VAL_ 1471 TBOX_Wifi_Net_StrgthSts 63 "Invalid" ;
VAL_ 1471 TBOX_Wifi_Net_Encryp 0 "Default" 1 "Yes" 2 "No" 3 "Reserved" ;
VAL_ 1480 TBOX_OTA_ownCondchk 0 "No_Request" 1 "Request" 3 "Invalid" ;
VAL_ 1480 TBOX_TerminalRemWakeupSig 0 "Not_waken_up" 1 "Waken_up" ;
VAL_ 1480 TBOX_RemSCModReq 0 "No_remote_control" 1 "Turn_on_remote_charging" 2 "Turn_off_remote_charging" 3 "Reserved" ;
VAL_ 1480 TBOX_RemPwrBattOpenHeatgReq 0 "No_remote_control" 1 "Turn_on_remote_power_battery_heating_mode" 2 "Turn_off_remote_power_battery_heating_mode" 3 "Reserved" ;
VAL_ 1480 TBOX_RemPwrBattResvHeatgReq 0 "No_request" 1 "Request" ;
VAL_ 1480 TBOX_RemInsdInfoDispEna 0 "Disable" 1 "Enable" ;
VAL_ 1480 TBOX_RemECCDefrstModReq 0 "No_remote_control" 1 "Turn_on_remote_AC_defrost_mode" 2 "Turn_off_remote_AC_defrost_mode" 3 "Reserved" ;
VAL_ 1480 TBOX_RemECCResvDefrstReq 0 "No_remote_control" 1 "Reserve_remote_AC_deforst_mode" ;
VAL_ 1480 TBOX_RemECCSetT 0 "Inactive" 36 "18°C" 37 "18.5°C" 38 "19°C" 39 "19.5°C" 40 "20°C" 41 "20.5°C" 42 "21°C" 43 "21.5°C" 44 "22°C" 45 "22.5°C" 46 "23°C" 47 "23.5°C" 48 "24°C" 49 "24.5°C" 50 "25°C" 51 "25.5°C" 52 "26°C" 53 "26.5°C" 54 "27°C" 55 "27.5°C" 56 "28°C" 57 "28.5°C" 58 "29°C" 59 "29.5°C" 60 "30°C" 61 "30.5°C" 62 "31°C" 63 "31.5°C" 64 "32°C" 255 "Invalid" ;
VAL_ 1480 TBOX_RemResvECCSetT 0 "Inactive" 36 "18°C" 37 "18.5°C" 38 "19°C" 39 "19.5°C" 40 "20°C" 41 "20.5°C" 42 "21°C" 43 "21.5°C" 44 "22°C" 45 "22.5°C" 46 "23°C" 47 "23.5°C" 48 "24°C" 49 "24.5°C" 50 "25°C" 51 "25.5°C" 52 "26°C" 53 "26.5°C" 54 "27°C" 55 "27.5°C" 56 "28°C" 57 "28.5°C" 58 "29°C" 59 "29.5°C" 60 "30°C" 61 "30.5°C" 62 "31°C" 63 "31.5°C" 64 "32°C" 255 "Invalid" ;
VAL_ 1480 TBOX_4GSigIND 0 "No_signal" 1 "Weak" 2 "Moderate" 3 "Strong" ;
VAL_ 1480 TBOX_Conn_Typ 0 "Not_Connected" 1 "3G_or_4G_LTE_CAT-1_and_below_(downllink_less_than_10_Mbps)" 2 "4G_LTE_CAT-2_and_above_(downlink_greater_than_10_Mbps)" 3 "WiFi_2,4_GHz" 4 "WiFi_5_GHz" 5 "Reserved_for_5G_FR1_(Less_than_1_Gbps)" 6 "Reserved_for_5G_FR2_(Greater_than_1_Gbps)" 7 "Reserved_for_5G_mmWave" ;
VAL_ 1480 TBOX_TSPNotConn 0 "Normal" 1 "fault" ;
VAL_ 1480 TBOX_EHUNotCONN 0 "Normal" 1 "fault" ;
VAL_ 1480 TBOX_WIFIError 0 "Normal" 1 "fault" ;
VAL_ 1480 TBOX_InnerBattError 0 "Normal" 1 "fault" ;
VAL_ 1480 TBOX_VoltLow 0 "Normal" 1 "fault" ;
VAL_ 1480 TBOX_VoltHigh 0 "Normal" 1 "fault" ;
VAL_ 1480 TBOX_4GLoss 0 "Normal" 1 "fault" ;
VAL_ 1480 TBOX_RemSWH_Req 0 "No_request" 1 "SWH_ON" 2 "Reserved" 3 "Invalid" ;
VAL_ 1480 TBOX_OTAInhbReq 0 "No_Inhibit_request" 1 "Inhibit_Request" 2 "Reserved" 3 "Invalid" ;
VAL_ 1552 ICC_UsrSetChrgRmnMilg 255 "Invalid" ;
VAL_ 1552 ICC_EPedlSts 0 "OnePedalDrive" 1 "Roll" 2 "Creep" 3 "Invalid" ;
VAL_ 1552 ICC_AccelMod 0 "Low" 1 "Medium" 2 "High" 3 "Invalid" ;
VAL_ 1552 ICC_BoostMode 0 "Default" 1 "Active_(On)" 2 "Inactive_(Off)" 3 "Reserved" ;
VAL_ 1552 ICC_EgyCnseClrFlg 0 "flag_bit_not_reached" 1 "average_energy_consumption_zeroed" 2 "Cumulative_average_energy_consumption_zeroed" 3 "Average_energy_consumption_&_cumulative_average_energy_consumption_zeroed" ;
VAL_ 1552 ICC_VehiMod 0 "Default_Mode" 1 "Mode1" 2 "Mode2" 3 "Mode3" 4 "Mode4" 5 "Mode5" 6 "Mode6" 7 "Mode7" 8 "Mode8" 9 "Mode9" 10 "Mode10" 11 "Mode11" 12 "Mode12" 13 "Mode13" 14 "Mode14" 15 "Mode15" ;
VAL_ 1552 ICC_EgyCnseStcClrFlg 0 "flag_bit_not_reached" 1 "Charging_interface_zeroed" 2 "Non-charging_interface_zeroed" 3 "Reserved" ;
VAL_ 1552 ICC_UsrSetDchaEndDrvgMilg 1023 "Invalid" ;
VAL_ 1552 ICC_PollingFctOpenSts 0 "Default" 1 "Active" 2 "Inactive" 3 "Reserved" ;
VAL_ 1552 ICC_KickFctOpenSts 0 "Default" 1 "Active" 2 "Inactive" 3 "Reserved" ;
VAL_ 1552 ICC_UsrSetChrgGunAntithft 0 "Anti-theft" 1 "No_anti-theft" ;
VAL_ 1552 ICC_ChrgInsulFctReq 0 "No_action" 1 "On" 2 "Off" 3 "Reserved" ;
VAL_ 1552 ICC_StopChrgBtn 0 "No_action" 1 "Stop_charging" ;
VAL_ 1552 ICC_DrvModSig 0 "Eco" 1 "Normal" 2 "Sport" 3 "Custom" 4 "Snow" 5 "Offroad" 6 "Valet" 7 "Invalid" ;
VAL_ 1552 ICC_SetACChrgLmtCrt 0 "Invalid_(treat_same_as_0x3)" 1 "Lvl1_(25%_of_MaxAllowable)" 2 "Lvl2_(50%_of_MaxAllowable)" 3 "Lvl3_(100%_of_MaxAllowable)" ;
VAL_ 1552 ICC_SetTrvlMod 0 "Initial_value" 1 "Daily_commuter_mode" 2 "Long-distance_travel_mode" 3 "Reserved" ;
VAL_ 1552 ICC_RegenLvl 0 "Off" 1 "Normal" 2 "High" 3 "Invalid" ;
VAL_ 1552 ICC_SetChrgEndSOC 127 "Invalid" ;
VAL_ 1552 ICC_StartChrgBtn 0 "No_action" 1 "Start_charging" ;
VAL_ 1583 TBOX_CrtTi_Day 0 "Day1" 30 "Day31" ;
VAL_ 1583 TBOX_CrtTi_Hr 0 "Hour_0" 23 "Hour_23" ;
VAL_ 1583 TBOX_CrtTi_Mins 0 "Mintue_0" 59 "Mintue_59" ;
VAL_ 1583 TBOX_CrtTi_Yr 0 "Year_2015" 255 "Year2270" ;
VAL_ 1583 TBOX_CrtTi_Mth 0 "January" 11 "December" ;
VAL_ 1583 TBOX_CrtTi_Sec 0 "Second_0" 59 "Second_59" ;
VAL_ 1696 BMS_mxCounterActEnergy 0 "no_information" 1 "Byte1_ActEngyHour,_Byte4_ActEngyDay" 2 "Byte1_ActEngyWeek,_Byte4_SctEngyMonth" ;
VAL_ 1756 BMS_mxCounterEnergy 0 "no_information" 1 "Byte1_EgyHr1,Byte4_EgyHr2" 2 "Byte1_EgyHr3,Byte4_EgyHr4" 3 "Byte1_EgyHr5,Byte4_EgyHr6" 4 "Byte1_EgyHr7,Byte4_EgyHr8" 5 "Byte1_EgyHr9,Byte4_EgyHr10" 6 "Byte1_EgyHr11,Byte4_EgyHr12" 7 "Byte1_EgyHr13,Byte4_EgyHr14" 8 "Byte1_EgyHr15,Byte4_EgyHr16" 9 "Byte1_EgyHr17,Byte4_EgyHr18" 10 "Byte1_EgyHr19,Byte4_EgyHr20" 11 "Byte1_EgyHr21,Byte4_EgyHr22" 12 "Byte1_EgyHr23,Byte4_EgyHr24" 13 "Byte1_EgyHr25,Byte4_EgyHr26" 14 "Byte1_EgyHr27,Byte4_EgyHr28" 15 "Byte1_EgyHr29,Byte4_EgyHr30" 16 "Byte1_EgyHr31,Byte4_EgyHr32" 17 "Byte1_EgyHr33,Byte4_EgyHr34" 18 "Byte1_EgyHr35,Byte4_EgyHr36" 19 "Byte1_EgyHr37,Byte4_EgyHr38" 20 "Byte1_EgyHr39,Byte4_EgyHr40" 21 "Byte1_EgyHr41,Byte4_EgyHr42" 22 "Byte1_EgyHr43,Byte4_EgyHr44" 23 "Byte1_EgyHr45,Byte4_EgyHr46" 24 "Byte1_EgyHr47,Byte4_EgyHr48" 33 "Byte1_EgyDy1,Byte4_EgyDy2" 34 "Byte1_EgyDy3,Byte4_EgyDy4" 35 "Byte1_EgyDy5,Byte4_EgyDy6" 36 "Byte1_EgyDy7" 37 "Byte1_EgyWk1,Byte4_EgyWk2" 38 "Byte1_EgyWk3,Byte4_EgyWk4" 39 "Byte1_EgyWk5" 40 "Byte1_EgyMth1,Byte4_EgyMth2" 41 "Byte1_EgyMth3,Byte4_EgyMth4" 42 "Byte1_EgyMth5,Byte4_EgyMth6" 43 "Byte1_EgyMth7,Byte4_EgyMth8" 44 "Byte1_EgyMth9,Byte4_EgyMth10" 49 "Byte1_EgyMth9,Byte4_EgyMth10" 50 "Byte1_EgyYr3,Byte4_EgyYr4" 51 "Byte1_EgyYr5,Byte4_EgyYr6" 52 "Byte1_EgyYr7,Byte4_EgyYr8" 53 "Byte1_EgyYr9,Byte4_EgyYr10" 54 "Byte1_EgyYr11,Byte4_EgyYr12" 55 "Byte1_EgyYr13,Byte4_EgyYr14" ;
VAL_ 261 VCU_DmdTqFltFlg 0 "Normal" 1 "Abnormal" ;
VAL_ 261 VCU_AllwMntnIndcrLamp 0 "Light_out" 1 "light_on" ;
VAL_ 261 VCU_AlrmLamp_FS 0 "Light_out" 1 "light_on" ;
VAL_ 279 ADAS_OTARdy_Fb 0 "Initial" 1 "Ready" 2 "Not_Ready" 3 "Invalid" ;
VAL_ 279 ADAS_OTAInhbRdy 0 "Initial" 1 "Inhibit" 2 "Not_Inhibit" 3 "Invalid" ;
VAL_ 279 ADAS_LgtCtrl_Sts 0 "Off" 1 "Reserved" 2 "Standby" 3 "Active" 4 "Fault" 5 "Dyno_Mode_On_(controller_inactive)" 6 "Workshop_Mode_On_(controller_inactive)" 7 "Reserved" ;
VAL_ 279 ADAS_LgtCtrl_StsVld 0 "Initializing" 1 "Valid" 2 "Invalid" 3 "Reserved" ;
VAL_ 279 ADAS_LgtCtrl_DrvrOvrdSts 0 "No_driver_overide" 1 "Driver_override_request" ;
VAL_ 279 ADAS_LgtCtrl_DrvrOvrdVld 0 "Initializing" 1 "Valid" 2 "Invalid" 3 "Reserved" ;
VAL_ 279 ADAS_HAP_EmgyStandstillVld 0 "Initializing" 1 "Valid" 2 "Invalid" 3 "Reserved" ;
VAL_ 279 ADAS_HAP_EmgyEPBVld 0 "Initializing" 1 "Valid" 2 "Invalid" 3 "Reserved" ;
VAL_ 279 ADAS_HAP_EmgyStandstillReq 0 "No_standstill_request" 1 "Standstill_request" ;
VAL_ 279 ADAS_ParkStandstillReq 0 "No_standstill_request" 1 "Standstill_request" ;
VAL_ 279 ADAS_ParkStandstillVld 0 "Initializing" 1 "Valid" 2 "Invalid" 3 "Reserved" ;
VAL_ 279 ADAS_ParkGearReq 0 "No_request" 1 "P" 2 "N" 3 "R" 4 "D" 5 "Reserved" 6 "E" 7 "S" ;
VAL_ 279 ADAS_ParkGearReqVld 0 "Initializing" 1 "Valid" 2 "Invalid" 3 "Reserved" ;
VAL_ 279 ADAS_ISA_CutOffReqVld 0 "Initializing" 1 "Valid" 2 "Invalid" 3 "Reserved" ;
VAL_ 279 ADAS_LgtCtrl_Typ 0 "Not_Active" 1 "ACC" 2 "ACC_Stop_and_Go" 3 "Intelligent_Speed_Assist" 4 "DRA" 5 "Cruise_Control" 6 "Full_Automatic_Park_Assist_System(APA)" 7 "Trained_Parking" 8 "Remote_Automated_Parking" 9 "Wheel_Scratch_Prevention_Park_Assist" ;
VAL_ 279 ADAS_HAP_EmgyEPBReq 0 "No_EPB_request" 1 "EPB_request" ;
VAL_ 279 ADAS_ISA_CutOffReq 0 "No_ISA_CutOff_request" 1 "ISA_CutOff_request" ;
VAL_ 280 ADAS_LgtCtrl_ESP_Sts 0 "Off" 1 "Reserved" 2 "Standby" 3 "Active" 4 "Fault" 5 "Dyno_Mode_On_(controller_inactive)" 6 "Workshop_Mode_On_(controller_inactive)" 7 "Reserved" ;
VAL_ 280 ADAS_LgtCtrl_ESP_Vld 0 "Initializing" 1 "Valid" 2 "Invalid" 3 "Reserved" ;
VAL_ 280 ADAS_ESP_DrvrOvrdSts 0 "No_driver_overide_" 1 "Driver_override_request" ;
VAL_ 280 ADAS_ESP_DrvrOvrdVld 0 "Initializing" 1 "Valid" 2 "Invalid" 3 "Reserved" ;
VAL_ 280 ADAS_HBAReq 0 "No_HBA_request" 1 "HBA_type_1" 2 "HBA_type_2" 3 "HBA_type_3" ;
VAL_ 280 ADAS_HBAVld 0 "Initializing" 1 "Valid" 2 "Invalid" 3 "Reserved" ;
VAL_ 280 ADAS_ESP_StandstillReq 0 "No_standstill_request" 1 "Standstill_request" ;
VAL_ 280 ADAS_ESP_StandstillVld 0 "Initializing" 1 "Valid" 2 "Invalid" 3 "Reserved" ;
VAL_ 280 ADAS_JerkReq 0 "No_jerk" 1 "Jerk_request" ;
VAL_ 280 ADAS_JerkReqVld 0 "Initializing" 1 "Valid" 2 "Invalid" 3 "Reserved" ;
VAL_ 280 ADAS_BrkPrefillReq 0 "No_brake_prefill" 1 "Brake_prefill_request" ;
VAL_ 280 ADAS_BrkPrefillVld 0 "Initializing" 1 "Valid" 2 "Invalid" 3 "Reserved" ;
VAL_ 280 ADAS_AEB_ActvTyp 0 "Not_Active" 1 "AEB_standard" 2 "AEB_VRU" 3 "LTAP_AEB" 4 "SCP_AEB" 5 "Rear_AEB" 6 "RCTB" ;
VAL_ 280 ADAS_AEB_DecelVld 0 "Initializing" 1 "Valid" 2 "Invalid" 3 "Reserved" ;
VAL_ 281 iBooster_OTARdy_Fb 0 "Initial" 1 "Ready" 2 "Not_Ready" 3 "Invalid" ;
VAL_ 281 iBooster_WarnOn 0 "No_Request_To_The_Warning_Lamp" 1 "Warning_Lamp_Requested" ;
VAL_ 281 iBooster_BrkPedlAppldFlg 0 "Brake_Pedal_Not_Applied" 1 "Brake_Pedal_Applied" ;
VAL_ 281 iBooster_BrkPedlAppldVld 0 "Initializing" 1 "Valid" 2 "Invalid" 3 "Reserved" ;
VAL_ 369 ICC_Start_X_Coordinate 65535 "No_Touch" ;
VAL_ 369 ICC_Start_Y_Coordinate 65535 "No_Touch" ;
VAL_ 369 ICC_dX_Coordinate 65535 "No_Touch" ;
VAL_ 369 ICC_dY_Coordinate 65535 "No_Touch" ;
VAL_ 425 ECC_VCU_ReqChgPwrLim 0 "No_Request" 1 "Req_increase" 2 "Req_decrease" 7 "SNV" ;
VAL_ 425 ECC_OTARdy_Fb 0 "Initial" 1 "Ready" 2 "Not_Ready" 3 "Invalid" ;
VAL_ 438 PKC_TpMnvrCancel 0 "Reserved" 1 "Cancel_request" 2 "Request_not_canceled" 3 "Invalid" ;
VAL_ 438 PKC_TpActDeactInp 0 "Reserved" 1 "Activation" 2 "Deactivation" 3 "Invalid" ;
VAL_ 438 PKC_RemPwrOnOffReq 0 "Invalid" 1 "Power_on" 2 "Power_off" 3 "Reserved" ;
VAL_ 438 PKC_RemDrvgReq 0 "Standby" 1 "Forward" 2 "Reverse" 3 "Turn_left" 4 "Right_turn" 5 "Turn_left" 6 "Forward_right" 7 "Backward_turn_left" 8 "Reverse:Turn_right" 9 "Steering_returnability" ;
VAL_ 438 PKC_RemChrgDchaGunUnlckCmd 0 "Initial_value" 1 "Not_unlocked" 2 "Unlocking" 3 "No_demand" ;
VAL_ 438 PKC_BLE_Online 0 "Not_on_line" 1 "On_line" ;
VAL_ 438 PKC_DviceRngeDist 0 "None" 1 "3_meters_or_less" 2 "Between_3_and_6_meters" 3 "More_than_6_meters" ;
VAL_ 438 PKC_MnvreEnblInput 0 "Not_Pressed" 1 "Pressed_Forward" 2 "Pressed_Backward" 3 "Invalid" ;
VAL_ 438 PKC_RapActDeactInp 0 "Reserved" 1 "Activation" 2 "Deactivation" 3 "Invalid" ;
VAL_ 438 PKC_MnvrRemsumeKey 0 "None" 1 "Not_Pressed" 2 "Pressed" 3 "Reserved" ;
VAL_ 438 PKC_MnvrRtnStartKey 0 "None" 1 "Not_Pressed" 2 "Pressed" 3 "Reserved" ;
VAL_ 438 PKC_AuthUsr 0 "Invalid" 1 "Authentication_Valid" 2 "Authentication_Invalid" 3 "Reserved" ;
VAL_ 438 PKC_AlcInterlockReqPromt 0 "Inactive" 1 "Permission_not_granted_to_drive,_alcohol_test_missing" 2 "Permission_not_granted_to_drive,_alcohol_test_failed_or_invalid" 3 "Invalid" ;
VAL_ 438 PKC_NFCReminderPromt 0 "Inactive" 1 "Timeout_elapsed._Put_Key_Fob/Smartphone_on_the_NFC_reader" 2 "Reserved" 3 "Invalid" ;
VAL_ 448 ADAS_LatCtrl_Sts 0 "Inactive" 1 "Active" 2 "Degraded" 3 "Failure" 4 "Severe_Failure" 5 "Dyno_Mode_On_(controller_inactive)" 6 "Workshop_Mode_On_(controller_inactive)" 7 "Reserved" ;
VAL_ 448 ADAS_LatCtrl_StsVld 0 "Initializing" 1 "Valid" 2 "Invalid" 3 "Reserved" ;
VAL_ 448 ADAS_LatCtrl_DrvrOvrd 0 "No_override" 1 "driver_override" ;
VAL_ 448 ADAS_LatCtrl_DrvrOvrdVld 0 "Initializing" 1 "Valid" 2 "Invalid" 3 "Reserved" ;
VAL_ 448 ADAS_LatCtrl_Typ 0 "Not_active" 1 "LKA_angle_request" 2 "ELKA_angle_request" 3 "LCA_or_TJA_angle_request" 4 "ESA_angle_request" 5 "FAP_angle_request" 6 "TP_angle_request" 7 "RAP_angle_request" ;
VAL_ 448 ADAS_LatCtrl_ReqVld 0 "Not_valid" 1 "Steering_angle_request_valid" ;
VAL_ 448 ADAS_LatCtrl_Req 0 "Not_active" 1 "Angle_request_active" ;
VAL_ 522 ADAS_LeLine2LnTyp 0 "Unknown" 1 "SingleLine_Solid" 2 "SingleLine_dashed" 3 "SingleLine_BottsDots" 4 "DoubleLine_Solid_Dashed" 5 "DoubleLine_Dash_Dash" 6 "DoubleLine_Dash_Solid" 7 "DoubleLine_Solid_Solid" 8 "Road_Edge" ;
VAL_ 522 ADAS_LeLine2LnColor 0 "Gray" 1 "White" 2 "Blue(ALC)" 3 "Invalid" ;
VAL_ 522 ADAS_LeLine2Crvt 63 "Straight_Lane" 127 "No_Display" ;
VAL_ 522 ADAS_LeLine2Conf 0 "12_5_percent" 1 "25_percent" 2 "37_5_percent" 3 "50_percent" 4 "62_5_percent" 5 "75_percent" 6 "87_5_percent" 7 "100_percent" ;
VAL_ 523 ADAS_LeLine3LnTyp 0 "Unknown" 1 "SingleLine_Solid" 2 "SingleLine_dashed" 3 "SingleLine_BottsDots" 4 "DoubleLine_Solid_Dashed" 5 "DoubleLine_Dash_Dash" 6 "DoubleLine_Dash_Solid" 7 "DoubleLine_Solid_Solid" 8 "Road_Edge" ;
VAL_ 523 ADAS_LeLine3LnColor 0 "Gray" 1 "White" 2 "Blue(ALC)" 3 "Invalid" ;
VAL_ 523 ADAS_LeLine3Crvt 63 "Straight_Lane" 127 "No_Display" ;
VAL_ 523 ADAS_LeLine3Conf 0 "12_5_percent" 1 "25_percent" 2 "37_5_percent" 3 "50_percent" 4 "62_5_percent" 5 "75_percent" 6 "87_5_percent" 7 "100_percent" ;
VAL_ 524 ADAS_RiLine1LnTyp 0 "Unknown" 1 "SingleLine_Solid" 2 "SingleLine_dashed" 3 "SingleLine_BottsDots" 4 "DoubleLine_Solid_Dashed" 5 "DoubleLine_Dash_Dash" 6 "DoubleLine_Dash_Solid" 7 "DoubleLine_Solid_Solid" 8 "Road_Edge" ;
VAL_ 524 ADAS_RiLine1LnColor 0 "Gray" 1 "White" 2 "Blue(ALC)" 3 "Invalid" ;
VAL_ 524 ADAS_RiLine1Crvt 63 "Straight_Lane" 127 "No_Display" ;
VAL_ 524 ADAS_RiLine1Conf 0 "12_5_percent" 1 "25_percent" 2 "37_5_percent" 3 "50_percent" 4 "62_5_percent" 5 "75_percent" 6 "87_5_percent" 7 "100_percent" ;
VAL_ 525 ADAS_RiLine2LnTyp 0 "Unknown" 1 "SingleLine_Solid" 2 "SingleLine_dashed" 3 "SingleLine_BottsDots" 4 "DoubleLine_Solid_Dashed" 5 "DoubleLine_Dash_Dash" 6 "DoubleLine_Dash_Solid" 7 "DoubleLine_Solid_Solid" 8 "Road_Edge" ;
VAL_ 525 ADAS_RiLine2LnColor 0 "Gray" 1 "White" 2 "Blue(ALC)" 3 "Invalid" ;
VAL_ 525 ADAS_RiLine2Crvt 63 "Straight_Lane" 127 "No_Display" ;
VAL_ 525 ADAS_RiLine2Conf 0 "12_5_percent" 1 "25_percent" 2 "37_5_percent" 3 "50_percent" 4 "62_5_percent" 5 "75_percent" 6 "87_5_percent" 7 "100_percent" ;
VAL_ 526 ADAS_RiLine3LnTyp 0 "Unknown" 1 "SingleLine_Solid" 2 "SingleLine_dashed" 3 "SingleLine_BottsDots" 4 "DoubleLine_Solid_Dashed" 5 "DoubleLine_Dash_Dash" 6 "DoubleLine_Dash_Solid" 7 "DoubleLine_Solid_Solid" 8 "Road_Edge" ;
VAL_ 526 ADAS_RiLine3LnColor 0 "Gray" 1 "White" 2 "Blue(ALC)" 3 "Invalid" ;
VAL_ 526 ADAS_RiLine3Crvt 63 "Straight_Lane" 127 "No_Display" ;
VAL_ 526 ADAS_RiLine3Conf 0 "12_5_percent" 1 "25_percent" 2 "37_5_percent" 3 "50_percent" 4 "62_5_percent" 5 "75_percent" 6 "87_5_percent" 7 "100_percent" ;
VAL_ 527 ADAS_RealLaneWidth 63 "Invalid" ;
VAL_ 527 ADAS_EgoDecelLane 0 "TRUE" 1 "FALSE" ;
VAL_ 527 ADAS_EgoCarpoolLane 0 "TRUE" 1 "FALSE" ;
VAL_ 527 ADAS_EgoLnTyp 0 "Through_Lane" 1 "Passing_Lane" 2 "Acceleration_Lane" 3 "Deceleration_Lane" 4 "Merging_Lane" 5 "Carpool_Lane" 6 "not_used" 7 "Bike_Lane" 8 "Left_Turn_Lane" 9 "Right_Turn_Lane" 10 "Fire_Lane" 11 "Road_edge" 12 "Barrier" 13 "Exit" ;
VAL_ 527 ADAS_LeLn1Typ 0 "Through_Lane" 1 "Passing_Lane" 2 "Acceleration_Lane" 3 "Deceleration_Lane" 4 "Merging_Lane" 5 "Carpool_Lane" 6 "Through_Lane" 7 "Bike_Lane" 8 "Left_Turn_Lane" 9 "Right_Turn_Lane" 10 "Fire_Lane" 11 "Road_edge" 12 "Barrier" 13 "Exit" ;
VAL_ 527 ADAS_LeLn2Typ 0 "Through_Lane" 1 "Passing_Lane" 2 "Acceleration_Lane" 3 "Deceleration_Lane" 4 "Merging_Lane" 5 "Carpool_Lane" 6 "Through_Lane" 7 "Bike_Lane" 8 "Left_Turn_Lane" 9 "Right_Turn_Lane" 10 "Fire_Lane" 11 "Road_edge" 12 "Barrier" 13 "Exit" ;
VAL_ 527 ADAS_RiLn1Typ 0 "Through_Lane" 1 "Passing_Lane" 2 "Acceleration_Lane" 3 "Deceleration_Lane" 4 "Merging_Lane" 5 "Carpool_Lane" 6 "Through_Lane" 7 "Bike_Lane" 8 "Left_Turn_Lane" 9 "Right_Turn_Lane" 10 "Fire_Lane" 11 "Road_edge" 12 "Barrier" 13 "Exit" ;
VAL_ 527 ADAS_RiLn2Typ 0 "Through_Lane" 1 "Passing_Lane" 2 "Acceleration_Lane" 3 "Deceleration_Lane" 4 "Merging_Lane" 5 "Carpool_Lane" 6 "Through_Lane" 7 "Bike_Lane" 8 "Left_Turn_Lane" 9 "Right_Turn_Lane" 10 "Fire_Lane" 11 "Road_edge" 12 "Barrier" 13 "Exit" ;
VAL_ 528 ADAS_TLR_EgoLaneTyp 0 "No_light_detected" 1 "Traffic_light_Circle_shape" 2 "Left_Arrow" 3 "Right_Arrow" 7 "Unkown" ;
VAL_ 528 ADAS_TLR_EgoLaneSts 0 "No_light_detected" 1 "Off" 2 "On_or_Solid" 3 "Blinking" 7 "Unkown" ;
VAL_ 528 ADAS_WSP_LeftCurb 0 "No_Detection" 1 "Front_Left_Curb_detection" 2 "Rear_Left_Curb_detection" 3 "Front/Rear_Left_Curb_detection" ;
VAL_ 528 ADAS_TLR_EgoLaneColor 0 "No_light_detected" 1 "Red" 2 "Amber" 3 "Green" 4 "Red_Orange" 5 "Red_With_Supp_green" 6 "Orange_with_Supp_green" 7 "Red_with_Supp_Orange" 8 "Unknown" ;
VAL_ 528 ADAS_TrafficLightShape 0 "No_light_detected" 1 "Red" 2 "Amber" 3 "Green" 7 "Unkown" ;
VAL_ 528 ADAS_TSRPassingCondition 0 "Overtaking_allowed" 1 "No_Overtaking_allowed" ;
VAL_ 528 ADAS_TLR_WarnReq 0 "No_TLR_Alert" 1 "TLR_Red_Light_Warning" 2 "TLR_Green_Light_Reminder" ;
VAL_ 528 ADAS_WSP_RightCurb 0 "No_Detection" 1 "Front_Right_Curb_detection" 2 "Rear_Right_Curb_detection" 3 "Front/Rear_Right_Curb_detection" ;
VAL_ 528 ADAS_ISAWarnReq 0 "No_Warning" 1 "Visual_Warning" ;
VAL_ 528 ADAS_TLRStructOrient 0 "No_Structure_Detected" 1 "Vertical" 2 "Horizontal" 7 "Unknown" ;
VAL_ 528 ADAS_TLRNumSpots 0 "No_light_Detected" 1 "1_Light" 2 "2_lights" 3 "3_Lights" 4 "4_Lights" 5 "5_Lights" 6 "Reserved" 7 "Unknown" ;
VAL_ 528 ADAS_ISAOverSpeedWarning 0 "No_warning" 1 "Warning_stage_1" 2 "Warning_stage_2" 3 "Warning_stage_3" 4 "Warning_stage_4" ;
VAL_ 528 ADAS_TSRSignCondition 0 "Unknown" 1 "None" 2 "Generic" 3 "Rain" 4 "Snow" 5 "Snow-Rain" 6 "Rain-Cloud" 7 "Fog" 8 "Time" 9 "Wet_conditions" 10 "Trailer" 11 "Arrow_Left" 12 "Arrow_Right" 13 "Distance_Arrow" 14 "School" 15 "Where_Workers_Present" 16 "End_of_Speed_Limit" 17 "School_when_flashing" 18 "Ice" 31 "Invalid" ;
VAL_ 528 ADAS_TSRSpdLimConfidenceLvl 0 "No_request" 1 "High_level_of_confidence" 2 "Medium_level_of_confidence" 3 "Low_level_of_confidence" ;
VAL_ 533 BMS_PwrBattOverTFlt_FS 0 "Normal" 1 "Abnormal" ;
VAL_ 533 BMS_PwrBattOverCrtFlt_FS 0 "Normal" 1 "Abnormal" ;
VAL_ 533 BMS_PwrBattNegRlyAdh_FS 0 "Normal" 1 "Abnormal" ;
VAL_ 533 BMS_PwrBattPosRlyAdh_FS 0 "Normal" 1 "Abnormal" ;
VAL_ 533 BMS_CellUnderrVoltFlt_FS 0 "Normal" 1 "Abnormal" ;
VAL_ 533 BMS_PwrBattCellOverVolt_FS 0 "Normal" 1 "Abnormal" ;
VAL_ 533 BMS_BattInlTSnsrFlt 0 "Normal" 1 "Abnormal" ;
VAL_ 533 BMS_BattOutlTSnsrFlt 0 "Normal" 1 "Abnormal" ;
VAL_ 533 BMS_PwrBattPrecRlyAdh_FS 0 "Normal" 1 "Abnormal" ;
VAL_ 533 BMS_AlrmLamp_FS 0 "Normal" 1 "Abnormal" ;
VAL_ 533 BMS_PwrBattLoadTotVoltV3_FS 65535 "Invalid" ;
VAL_ 533 BMS_FctSftyErrCod 255 "Invalid" ;
VAL_ 566 VCU_DCChrgDchaGunCnctnSts 0 "Initial_value" 1 "Not_connected" 2 "DCCharging/discharging_gun_fully_connnected" 3 "Invalid" ;
VAL_ 566 VCU_OutpACWakeupSigSts 0 "Initial_value" 1 "Not_waken_up" 2 "Waken_up" 3 "Invalid" ;
VAL_ 566 VCU_OutpFCWakeupSigSts 0 "Initial_value" 1 "Not_waken_up" 2 "Waken_up" 3 "Invalid" ;
VAL_ 566 VCU_ACChrgDchaGunCnctnSts 0 "Initial_value" 1 "Not_connected" 2 "ACCharging/discharging_gun_fully_connnected" 3 "V2V_adapter_plugged" 4 "V2L_adapter_plugged" 7 "Invalid" ;
VAL_ 566 VCU_VcuErrCtgy 0 "No_Error" 1 "Component" 2 "Level_2" 3 "Cp_Lv2" 4 "Signal_Status" 5 "Cp_SigSts" 6 "Lv2_SigSts" 7 "Cp_Lv2_SigSts" ;
VAL_ 566 VCU_VcuState 0 "Undefined" 1 "Wakeup" 2 "Startup_LV" 3 "Startup_HV" 4 "Startup_Boardnet_Supply" 5 "Standby" 6 "Drive" 7 "Charge" 8 "Postrun_Conditioning" 9 "Postrun_Auxiliaries_Idle" 10 "Postrun_HV_Deactivation" 11 "Postrun_HV_Active_Discharge" 12 "Postrun_LV_Deactivation" 13 "Sleep" 14 "Emergency_OFF_Auxiliaries_Idle" 15 "Emergency_OFF_HV_Deactivation" 16 "Emergency_OFF_HV_Act_Dischrg" 17 "Emergency_OFF_LV_Deactivation" 18 "Safestate" 31 "Invalid" ;
VAL_ 566 VCU_VcuErrBitVect 0 "no_Error" 1 "Vehicle_Speed_Error" 2 "Accelerator_Pedal_Error" 4 "Cl15_Error" 8 "GSL_Logic_Error" 16 "Charging_Connection_Error" 32 "Lvl2_Static_Torque_Error" 64 "Lvl2_Dynamic_Torque_Dd" 128 "Lvl2_Dynamic_Torque_ESC" 256 "Lvl2_Dynamic_Torque_Rng" 512 "Battery_Error" 1024 "EFA_Error" 2048 "ERA_Error" 4096 "DcDc12_Error" 8192 "GSL_Error" 16384 "PLC_Error" 32768 "THM_Error" 65536 "LadAc_Error" 131072 "LadDc_Error" 262144 "Isolation_error" 524288 "HVIL_Error" 1048576 "Batt_Precharge_Error" 2097152 "Batt_Level_Error" 8388608 "Batt_Main_Contactor_Error" 16777216 "Batt_COM_Lost_Error" 33554432 "EFA_COM_Lost_Error" 67108864 "Dc_Charging_Contactor_Error" ;
VAL_ 566 VCU_PwrSplyEquipSts 0 "Initial_value" 1 "State_2" 2 "State_2'" 3 "State_3'" 4 "Charging_stopped" 5 "Plug_and_charge" 6 "Reserved" 7 "Invalid" ;
VAL_ 586 BMS_PwrBattChrgDchaCrt1 65535 "Invalid" ;
VAL_ 586 BMS_PwrBattChrgDchaCrt2 65535 "Invalid" ;
VAL_ 586 BMS_PwrBattIntTotVoltV1 65535 "Invalid" ;
VAL_ 592 ICC_SegMsgType 0 "System_Specific" 1 "Position" 2 "Segment" 3 "Stub" 4 "Profile_Short" 5 "Profile_Long" 6 "Meta-data" 7 "Reserved" ;
VAL_ 592 ICC_SegOffset 8191 "Invalid" ;
VAL_ 592 ICC_SegUpdate 0 "False" 1 "True" ;
VAL_ 592 ICC_SegRetr 0 "False" 1 "True" ;
VAL_ 592 ICC_SegBuildUpArea 0 "Segment_is_not_part_of_a_built-up_area" 1 "Segment_is_part_of_a_built-up_area" 2 "Unknown" 3 "N/A_The_field_value_is_based,_but_not_lim_to,_the_presence_of_a_sign_or_polygon" ;
VAL_ 592 ICC_SegBridge 0 "Segment_is_not_part_of_a_bridge" 1 "Segment_is_part_of_a_bridge" 2 "Unknown" 3 "Invalid" ;
VAL_ 592 ICC_SegTunnel 0 "Segment_is_not_part_of_a_tunnel" 1 "Segment_is_part_of_a_tunnel" 2 "Unknown" 3 "Invalid" ;
VAL_ 592 ICC_SegFuncRoadClass 0 "Unknown" 1 "Expressway" 2 "Urban_Expressway" 3 "National_Road" 4 "Provincial_Road" 5 "Urban_trunk_road；County_road" 6 "Secondary_Road；Tyre_road" 7 "Normal_roads；County_rural_roads；Path" ;
VAL_ 592 ICC_SegRelProbb 0 "path_is_not_allowed" 31 "N/A" ;
VAL_ 592 ICC_SegFormOfWay 0 "Unknown" 1 "Freeway_or_Controlled_Access_road_that_is_not_a_slip_road_or_ramp" 2 "Multiple_Carriageway_or_Multiply_Digitized_Road" 3 "Single_Carriageway(default)" 4 "Roundabout_Circle" 5 "Traffic_Square_or_Special_Traffic_Figure" 8 "Parallel_Road" 9 "Slip_Road_or_Ramp_on_a_Freeway_or_Controlled_Access_road" 10 "Slip_Road_or_Ramp_not_on_a_Freeway_or_Controlled_Access_road" 11 "Service_Road_or_Frontage_Road" 12 "Entrance_to_or_exit_of_a_Car_Park" 13 "Entrance_to_or_exit_to_Service" 14 "Pedestrian_Zone" 15 "N/A" ;
VAL_ 592 ICC_SegCmplxInsct 0 "Segment_is_not_part_of_complexintersection" 1 "Segment_is_part_of_a_complexintersection" 2 "Unknown" 3 "Invalid" ;
VAL_ 592 ICC_SegPartOfCalcRoute 0 "Segment_is_not_part_of_Calculated_Route" 1 "Segment_is_part_of_Calculated_Route" 2 "Unknown" 3 "Invalid" ;
VAL_ 592 ICC_SegEffSpdLmtType 0 "Implicit(For_Instance,Default_Speed_Limit_In_The_Cities)" 1 "Explicit_-_On_Traffic_Sign" 2 "Explicit_-_By_Night" 3 "Explicit_-_By_Day" 4 "Explicit_-_Time_Of_Day" 5 "Explicit_-_Rain" 6 "Explicit_-_Snow" 7 "unknown" ;
VAL_ 592 ICC_SegEffSpdLmt 0 "Unknown" 1 "value<=5km/h[mph]" 2 "5<value<=7km/h[mph]" 3 "7<value<=10km/h[mph]" 4 "10<value<=15km/h[mph]" 5 "15<value<=20km/h[mph]" 6 "20<value<=25km/h[mph]" 7 "25<value<=30km/h[mph]" 8 "30<value<=35km/h[mph]" 9 "35<value<=40km/h[mph]" 10 "40<value<=45km/h[mph]" 11 "45<value<=50km/h[mph]" 12 "50<value<=55km/h[mph]" 13 "55<value<=60km/h[mph]" 14 "60<value<=65km/h[mph]" 15 "65<value<=70km/h[mph]" 16 "70<value<=75km/h[mph]" 17 "75<value<=80km/h[mph]" 18 "80<value<=85km/h[mph]" 19 "85<value<=90km/h[mph]" 20 "90<value<=95km/h[mph]" 21 "95<value<=100km/h[mph]" 22 "100<value<=105km/h[mph]" 23 "105<value<=110km/h[mph]" 24 "110<value<=115km/h[mph]" 25 "115<value<=120km/h[mph]" 26 "120<value<=130km/h[mph]" 27 "130<value<=140km/h[mph]" 28 "140<value<=150km/h[mph]" 29 "150<value<unlimited" 30 "Unlimited" 31 "N/A" ;
VAL_ 592 ICC_SegNumOfLaneDrvDir 0 "denotes_one-direction_road_driven_in_wrong_direction" 6 "indicate_6_or_more_lanes" 7 "Invalid" ;
VAL_ 592 ICC_SegNumOfLaneOppDir 0 "denotes_one-direction_road" 1 "for_one_lane_only" 2 "indicates_2_or_more_lanes" 3 "Invalid" ;
VAL_ 592 ICC_SegDividedRoad 0 "Segment_is_not_part_of_a_divided_road/dual_carriageway" 1 "Segment_is_part_of_a_divided_road/dual_carriageway" 2 "Unknown" 3 "Invalid" ;
VAL_ 593 ICC_StubMsgType 0 "System_Specific" 1 "Position" 2 "Segment" 3 "Stub" 4 "Profile_Short" 5 "Profile_Long" 6 "Meta-data" 7 "Reserved" ;
VAL_ 593 ICC_StubOffset 8191 "Invalid" ;
VAL_ 593 ICC_StubUpdate 0 "False" 1 "True" ;
VAL_ 593 ICC_StubRetr 0 "False" 1 "True" ;
VAL_ 593 ICC_StubStubPathIdx 0 "Segment_is_not_part_of_a_built-up_area" 1 "Segment_is_part_of_a_built-up_area" 2 "Unknown" 3 "N/A_The_field_value_is_based,_but_not_lim_to_a_posted_sign_or_polygon" ;
VAL_ 593 ICC_StubFuncRoadClass 7 "other_roads" ;
VAL_ 593 ICC_StubRelProbb 0 "(=_0%)_Indicates_that_turn_is_not_allowed" 30 "(=_100%)_Indicates_that_this_is_the_only_possible_turn" 31 "Invalid" ;
VAL_ 593 ICC_StubFormOfWay 15 "Invalid" ;
VAL_ 593 ICC_StubCmplxInsct 0 "New_path_is_not_part_of_complexintersection" 1 "New_path__is_part_of_a_complexintersection" 2 "Unknown" 3 "Invalid" ;
VAL_ 593 ICC_StubPartOfCalcRout 0 "New_path_from_this_point_on_is_not_part_of_Calculated_Route" 1 "New_path_from_this_point_on_is_part_of_Calculated_Route" 2 "Unknown" 3 "Invalid" ;
VAL_ 593 ICC_StubTurnAngl 0 "In_Path_Direction" 1 "1.417_Degrees_Right" 126 "178.583_Degrees_Right" 127 "Opposite_Direction" 128 "178.583_Degrees_Left_(181.417_Degrees_Right)+R[6]C" 253 "1.417_Degrees_left_(358.583_Degrees_Right)" 254 "Unknown" 255 "Invalid" ;
VAL_ 593 ICC_StubNumOfLaneDrvDir 0 "Denotes_one-direction_road_driven_in_wrong_direction" 6 "Indicate_6_Or_More_Lanes" 7 "Invalid" ;
VAL_ 593 ICC_StubNumOfLaneOppDir 0 "Denotes_one-direction_road" 1 "For_one_lane_only" 2 "Indicates_2_or_more_lanes" 3 "Invalid" ;
VAL_ 593 ICC_StubRtOfWay 0 "Driving_towards_this_stub_has_priority_over_all_conflicting_vehicle_movements" 1 "Driving_towards_this_stub_might_require_yielding_to_conflicting_vehicle_movements" 2 "Unknown" 3 "Invalid" ;
VAL_ 593 ICC_StubLastStub 0 "False" 1 "True" ;
VAL_ 594 ICC_ProfLongMsgType 0 "System_Specific" 1 "Position" 2 "Segment" 3 "Stub" 4 "Profile_Short" 5 "Profile_Long" 6 "Meta-data" 7 "Reserved" ;
VAL_ 594 ICC_ProfLongOffset 8191 "Invalid" ;
VAL_ 594 ICC_ProfLongUpdate 0 "False" 1 "True" ;
VAL_ 594 ICC_ProfLongRetr 0 "False" 1 "True" ;
VAL_ 594 ICC_ProfLongCtrlPoint 0 "False" 1 "True" ;
VAL_ 594 ICC_ProfLongProfType 0 "unknown" ;
VAL_ 594 ICC_ProfLongSignType 255 "Invalid" ;
VAL_ 594 ICC_ProfLongSignTimeSpec 0 "Not_time_dependent" 1 "Applies_now_but_not_all_the_time" 2 "Does_not_apply_now_but_at_other_times" 3 "It’s_not_known_whether_the_sign_applies_now" ;
VAL_ 594 ICC_ProfLongSignVehSpec 0 "Not_vehicle_specific" 1 "Applies_to_this_vehicle_but_not_to_all_vehicles" 2 "Does_not_apply_to_this_vehicle_but_possibly_to_other_vehicles" 3 "It’s_not_known_whether_the_sign_applies_to_this_vehicle" ;
VAL_ 594 ICC_ProfLongSignLane 1 "Not_specific_to_any_lane" 15 "Unknown,_or_N/A" ;
VAL_ 594 ICC_ProfLongSignLocation 0 "Unknown" 1 "Right_of_the_road" 2 "Left_of_the_road" 3 "Above_the_road" 4 "On_the_road_surface" 5 "Sign_is_not_physically_located_at_this_position,_see_remark_1" 6 "The_stretch_of_road_that_a_sign_applies_to_ends_at_this_position,_see_remark_1" 7 "N/A" ;
VAL_ 594 ICC_ProfLongSignCondition 0 "Always_valid" 1 "Has_other_conditions_that_are_fulfilled_for_all_vehicles" 2 "Has_other_cond_that_are_fulfilled_for_this_vehicle_but_not_nec_for_all_veh" 3 "Has_other_cond_that_are_not_fulfilled_for_this_vehicle_but_poss_for_other_veh" 4 "Has_other_conditions_that_are_not_currently_fulfilled_for_any_vehicle" 5 "Sign_is_not_valid_at_all_(e.g._visible_here_but_referring_to_another_road)" 6 "Valid_only_if_snow" 7 "Valid_only_if_fog" 8 "Valid_only_if_rain" 9 "Valid_only_by_day" 10 "Valid_only_by_night" 11 "Valid_depending_on_turn_direction_/_future_path" 12 "Validity_depends_on_cond_or_combinations_of_conditions_that_cannot_be_adequately" 15 "Unknown_whether_validity_depends_on_conditions" ;
VAL_ 597 ICC_ProfShortMsgType 0 "System_Specific" 1 "Position" 2 "Segment" 3 "Stub" 4 "Profile_Short" 5 "Profile_Long" 6 "Meta-data" 7 "Reserved" ;
VAL_ 597 ICC_ProfShortOffset 8191 "Invalid" ;
VAL_ 597 ICC_ProfShortUpdate 0 "False" 1 "True" ;
VAL_ 597 ICC_ProfShortRetr 0 "False" 1 "True" ;
VAL_ 597 ICC_ProfShortCtrlPoint 0 "False" 1 "True" ;
VAL_ 597 ICC_ProfShortProfType 0 "Invalid" ;
VAL_ 597 ICC_ProfShortAccurClass 0 "Means_Highest_Accuracy" 1 "Means_Medium_Accuracy" 2 "Means_Lowest_Accuracy" 3 "Indicates_That_Accuracy_is_Unknown" ;
VAL_ 597 ICC_ProfShortDist1 0 "No_Other_Profile_Values_are_Defined_in_This_Message" 1023 "Invalid" ;
VAL_ 597 ICC_ProfShortValue0 1023 "Invalid" ;
VAL_ 597 ICC_ProfShortValue1 1023 "Invalid" ;
VAL_ 617 VCU_VehChrgDchgMod 0 "Initial_value" 1 "DC_charging" 2 "VTOL_discharging" 3 "VTOV_discharging" 4 "AC_charging" 5 "V2L_trunk_active" 6 "Reserved" 7 "Invalid" ;
VAL_ 617 VCU_DCRlyCtrlCmd 0 "Open" 1 "Close" ;
VAL_ 617 VCU_ChrgSysOperCmd 0 "Initial_value" 1 "Standby" 2 "Working_mode" 3 "Power_mode" 4 "Shutdown" 5 "Sleep" 6 "Reserved" 7 "Invalid" ;
VAL_ 617 VCU_ChrgSts 0 "Initial_value" 1 "Connected_but_not_charging" 2 "AC_charging" 3 "DC_charging" 4 "Charging_completed" 5 "Charging_fault" 6 "Reserved" 7 "Invalid" ;
VAL_ 711 ADAS_APASlot5Typ 0 "Parallel" 1 "Perpendicular" 2 "Fish_bone" 3 "Reserved" ;
VAL_ 711 ADAS_APASlot5Sid 0 "Left" 1 "Right" ;
VAL_ 711 ADAS_APASlot5Sts 0 "Open" 1 "Occupied" ;
VAL_ 717 ADAS_APASlotSelTyp 0 "Parallel" 1 "Perpendicular" 2 "Fish_bone" 3 "Reserved" ;
VAL_ 717 ADAS_APASlotSelSid 0 "Left" 1 "Right" ;
VAL_ 717 ADAS_APASlotSelSts 0 "Open" 1 "Occupied" ;
VAL_ 717 ADAS_APAAvailable 0 "Not_available" 1 "Park_in_available" 2 "Park_out_available" 3 "Reserved" ;
VAL_ 717 ADAS_APAScanngSde 0 "Not_scanning" 1 "Left" 2 "Right" 3 "Both" ;
VAL_ 717 ADAS_CurbPrtcRrLeWhl 0 "Not_warning" 1 "Warning" ;
VAL_ 717 ADAS_CurbPrtcRrRiWhl 0 "Not_warning" 1 "Warning" ;
VAL_ 717 ADAS_CurbPrtcFrLeWhl 0 "Not_warning" 1 "Warning" ;
VAL_ 717 ADAS_CurbPrtcFrRiWhl 0 "Not_warning" 1 "Warning" ;
VAL_ 717 ADAS_APASpdWarn 0 "Vehicle_speed_not_exceeded" 1 "Vehicle_speed_exceeded" ;
VAL_ 723 ADAS_APASlot1Typ 0 "Parallel" 1 "Perpendicular" 2 "Fish_bone" 3 "Reserved" ;
VAL_ 723 ADAS_APASlot1Sid 0 "Left" 1 "Right" ;
VAL_ 723 ADAS_APASlot1Sts 0 "Open" 1 "Occupied" ;
VAL_ 729 ADAS_APASlot2Typ 0 "Parallel" 1 "Perpendicular" 2 "Fish_bone" 3 "Reserved" ;
VAL_ 729 ADAS_APASlot2Sid 0 "Left" 1 "Right" ;
VAL_ 729 ADAS_APASlot2Sts 0 "Open" 1 "Occupied" ;
VAL_ 735 ADAS_APASlot3Typ 0 "Parallel" 1 "Perpendicular" 2 "Fish_bone" 3 "Reserved" ;
VAL_ 735 ADAS_APASlot3Sid 0 "Left" 1 "Right" ;
VAL_ 735 ADAS_APASlot3Sts 0 "Open" 1 "Occupied" ;
VAL_ 741 ADAS_APASlot4Typ 0 "Parallel" 1 "Perpendicular" 2 "Fish_bone" 3 "Reserved" ;
VAL_ 741 ADAS_APASlot4Sid 0 "Left" 1 "Right" ;
VAL_ 741 ADAS_APASlot4Sts 0 "Open" 1 "Occupied" ;
VAL_ 746 ADAS_APASlot6Sid 0 "Left" 1 "Right" ;
VAL_ 746 ADAS_APASlot6Sts 0 "Open" 1 "Occupied" ;
VAL_ 746 ADAS_APASlot6Typ 0 "Parallel" 1 "Perpendicular" 2 "Fish_bone" 3 "Reserved" ;
VAL_ 784 CIM_TurnLampSwtSts 0 "Default_state" 1 "Turn_Left_left_steering_state" 2 "Turn_Right_right_steering_state" 3 "Turn_left_highway_flashing" 4 "Turn_right_highway_flashing" 5 "Mechanical_Failure" 6 "Invalid_left" 7 "Invalid_right" ;
VAL_ 784 CIM_HiBeamSwtSts 0 "Neutral_middle_position" 1 "High_beam_pull" 2 "High_beam_push" 3 "Invalid" ;
VAL_ 784 CIM_FrntWshrSwtSts 0 "Washing_OFF" 1 "Front_wash_1st_position_(MIST)" 2 "Front_wash_2nd_position" 3 "Invalid" ;
VAL_ 784 CIM_FrntWiprSwtSts 0 "Off_default" 1 "AutoLow_wiper_automatic_(low_sensitivity)" 2 "AutoHigh_Automatic_Wiper_(high_sensitivity)" 3 "Low_speed_continuous_scraping" 4 "High_continuous_high-speed_scraping" 7 "Invalid" ;
VAL_ 785 ADAS_HiPrioDegradationSts 0 "No_high_priority_popup_requested" 1 "All_ADAS_features_offline" 2 "ACC_is_being_disabled,_driver_take_control_" 3 "Driver_assist_(ACC_with_LCC)_being_disabled,_Driver_take_control" 4 "Traffic_Jam_Assist_being_disabled,_Driver_take_control" 5 "All_front_AEB_support_is_disabled" 6 "All_rear_AEB_support_is_disabled" 7 "Autopark_operations_being_disabled,_driver_take_control" 8 "Park_Assist_Support_disabled" 9 "Front_Cross_Path_Braking_disabled" 10 "Rear_Cross_Path_Braking_disabled" 11 "Emergency_Steering_Assist_is_disabled" ;
VAL_ 785 ADAS_ISA_PerSpdLim_req 0 "No_Percieved_Speed_Limit_change_notification_request" 1 "Percieved_Speed_Limit_change_notification_request" ;
VAL_ 785 ADAS_LoPrioDegradationSts 0 "No_low_priority_popup_requested" 1 "Blind_Spot_monitoring_is_offline" 2 "Collision_warning_disabled" 3 "Lane_departure_warning_disabled" 4 "Front_Cross_path_warning_disabled" 5 "Rear_Cross_Path_warning_disabled" 6 "Park_Assist_warnings_disabled" 7 "Door_Opening_Warning_disabled" 8 "Wheel_Scratch_Prevention_disabled" 9 "DCAA_disabled" ;
VAL_ 785 ADAS_SpeedLimitUnit 0 "KPH" 1 "MPH" ;
VAL_ 787 BSD 0 "UaCMX" 1 "DsblCMX" 2 "StdbyCMX" 3 "StdbyDgrdCMX" 4 "ActvCMX" 5 "ActvDgrdCMX" 6 "ErrCMX" 7 "ActvDgrd1CMX" 8 "ActvDgrd2CMX" 9 "DsblDgrdCMX" ;
VAL_ 787 ADAS_BACM_Sts 0 "UaCMX" 1 "DsblCMX" 2 "StdbyCMX" 3 "StdbyDgrdCMX" 4 "ActvCMX" 5 "ActvDgrdCMX" 6 "ErrCMX" 7 "ActvDgrd1CMX" 8 "ActvDgrd2CMX" 9 "DsblDgrdCMX" ;
VAL_ 787 AEB_ReAEB_Sts 0 "UaCMX" 1 "DsblCMX" 2 "StdbyCMX" 3 "StdbyDgrdCMX" 4 "ActvCMX" 5 "ActvDgrdCMX" 6 "ErrCMX" 7 "ActvDgrd1CMX" 8 "ActvDgrd2CMX" 9 "DsblDgrdCMX" ;
VAL_ 787 ADAS_Sts_ACC_ICC 0 "ACC_Off" 1 "Initialization" 2 "Standby" 3 "Active" 4 "Override" 5 "Standstill_active" 6 "Standstill_wait" 7 "Deactivation_brake" 8 "Deactivation_other" 9 "Failure_reversible" 10 "Failure_irreversible" 11 "Standstill_GoNotification" ;
VAL_ 787 ADAS_TJA_AutoSteerSts 0 "Off_Unavailable" 1 "Off_Available" 2 "On_Standby" 3 "Active_lane_following" 4 "Active_object_following" 5 "Driver_override" 6 "Fault" 7 "Reserved" ;
VAL_ 787 ADAS_ISASts 0 "Off" 1 "Available" 2 "Active" 3 "Error" ;
VAL_ 787 ADAS_Sts_TLR 0 "Off" 1 "Available" 2 "Active" 3 "Error" ;
VAL_ 787 ADAS_TSRSts 0 "Reserved" 1 "Off" 2 "Fusion_Mode" 3 "Vision_Mode" 4 "Navigation_Mode" 5 "Error" ;
VAL_ 788 ADAS_ESAState 0 "ESA_OffCoded" 1 "ESA_Off" 2 "Inactve" 3 "ESA_Actv_RequestTpfLT" 4 "ESA_Actv_RequestTpfRT" 5 "Actv_SteeringLT" 6 "Actv_SteeringRT" 7 "ESA_RampoutLe" 8 "ESA_RampoutRi" 9 "ESA_Error" 10 "Unavailable" ;
VAL_ 788 ADAS_LKASts 0 "LKA_OffCoded" 1 "LKA_Off" 2 "Inactve" 3 "ReadyToAssist" 4 "LKA_WarningLT" 5 "LKA_WarningRT" 6 "Actv_SteeringLT" 7 "Actv_SteeringRT" 8 "LKA_Error" ;
VAL_ 788 ADAS_LCA_Sts 0 "Off" 1 "Standby" 2 "Prepare_to_left_lane" 3 "Prepare_to_right_lane" 4 "Active_to_left" 5 "Active_to_right" 6 "Return" 7 "Error" ;
VAL_ 788 ADAS_LCA_Maneuver_Status 0 "No_Suppressed" 1 "LCA_Suppressed" ;
VAL_ 788 ADAS_APASts 0 "Off" 1 "Initialize" 2 "Standby" 3 "Scanning" 4 "Slot_selected" 5 "Park_In" 6 "Park_Out" 7 "Aborted" 8 "Parking_complete" 9 "Fault" 10 "Park_Out_ready" ;
VAL_ 788 ADAS_ELKASts 0 "ELKA_OffCoded" 1 "LKA_Off" 2 "Inactve" 3 "ReadyToAssist" 4 "ELKA_WarningLT" 5 "ELKA_WarningRT" 6 "Actv_SteeringLT" 7 "Actv_SteeringRT" 8 "ELKA_Error" ;
VAL_ 788 ADAS_WSPPASts 0 "Off" 1 "On_standby" 2 "On_available" 3 "On_active" 4 "Off_fault" ;
VAL_ 788 ADAS_DOW_Sts 0 "Off" 1 "On_standby" 2 "On_available" 3 "On_active" 4 "Off_fault" ;
VAL_ 788 ADAS_BSDSts 0 "Off" 1 "On_standby" 2 "On_available" 3 "On_active" 4 "Error" ;
VAL_ 788 ADAS_DCAASts 0 "Off" 1 "On_(Standby)" 2 "On_(available)" 3 "On_(active)" 4 "Off_(Fault)" ;
VAL_ 788 ADAS_AHBA_Sts 0 "Off" 1 "On" 2 "Fault" 3 "Reserved" ;
VAL_ 788 ADAS_AHBA_BeamDecisRsn 0 "Default" 1 "Low_speed" 2 "Oncoming" 3 "Preceding" 4 "Reflector" 5 "Illuminated_area" 6 "Failsafe" 7 "LitNight" 8 "Guardrail" 9 "BlinkingTrffcLi" 10 "Junction" 11 "Reserved" 12 "EgoTurning" ;
VAL_ 789 ADAS_DOW_CID_LeDispReq 0 "Display_No_threat_both_door_closed" 1 "Display_threat_both_door_closed" 2 "Display_threat_front_door_open" 3 "Display_threat_rear_door_open" 4 "Display_threat_both_door_open" 5 "Display_no_threat_front_door_open" 6 "Display_no_threat_rear_door_open" 7 "Display_no_threat_both_door_open" ;
VAL_ 789 ADAS_DOW_CID_RiDispReq 0 "No_threat_both_door_closed" 1 "Display_threat_both_door_closed" 2 "Display_threat_front_door_open" 3 "Display_threat_rear_door_open" 4 "Display_threat_both_door_open" 5 "Display_no_threat_front_door_open" 6 "Display_no_threat_rear_door_open" 7 "Display_no_threat_both_door_open" ;
VAL_ 789 ADAS_BSD_CID_LeDispReq 0 "No_threat" 1 "Threat_present_on_left" 2 "Threat_present_on_left_and_turn_indicator_left_on" 3 "Critical_threat_present_on_left" 4 "Error" ;
VAL_ 789 ADAS_BSD_CID_RiDispReq 0 "No_threat" 1 "Threat_present_on_right" 2 "Threat_present_on_right_and_turn_indicator_right_on" 3 "Critical_threat_present_on_right" 4 "Error" ;
VAL_ 789 ADAS_DCAA_WarnLvlReq 0 "Off" 1 "On_Standby" 2 "Drowsy_level_1" 4 "Drowsy_level_2" 5 "Drowsy_level_3" 6 "Distraction_level_1" 7 "Distraction_level_2" 8 "Distraction_level_3" ;
VAL_ 789 ADAS_DCAA_GazeOnWarnReq 0 "No_gaze_on_warning_request" 1 "Gaze_on_warning_request" ;
VAL_ 790 ADASDC_SVS_ViewSts 0 "None" 1 "Front_Normal_View" 2 "Left_Flank_3D_view" 3 "Right_Flank_3D_View" 4 "Rear_Normal_View" 5 "Curb_View" 6 "Front_Cross_Path_View" 7 "Rear_Cross_Path_View" 8 "360_Degree_Free_Floating_View" ;
VAL_ 790 ADASDC_SVS_AvailableSts 0 "SVS_available" 1 "system_fault" 2 "Too_high_speed" 3 "message3" 4 "message4" 5 "message5" 6 "message6" 7 "message7" 8 "message8" 9 "message9" 10 "message10" 11 "message11" 12 "message12" 13 "message13" ;
VAL_ 790 ADASDC_SVS_RrCamBttnShw 0 "Do_not_show_rear_view_camera_button" 1 "Show_rear_view_camera_button" 2 "Show_rear_view_camera_button(fault,_not_Press-able)" 3 "Reserved" ;
VAL_ 790 ADASDC_SVS_WdAnglBttnShw 0 "Don't_show_wide_angle_camera_view_toggle_button" 1 "Show_wide_angle_camera_view_toggle_button" 2 "Show_wide_angle_camera_view_button(fault,_not_Press-able)" 3 "Reserved" ;
VAL_ 790 ADASDC_SVS_FrntWdAnglBttnShw 0 "Do_not_show_front_wide_angle_camera_view_button" 1 "Show_front_wide_angle_camera_view_button" 2 "Show_front_wide_angle_camera_view_button(fault,_not_Press-able)" 3 "Reserved" ;
VAL_ 790 ADASDC_SVS_3DCamBttnShw 0 "Do_not_show_3D_camera_view_button" 1 "Show_3D_camera_view_button" 2 "Show_3D_camera_view_button(fault,_not_Press-able)" 3 "Reserved" ;
VAL_ 790 ADASDC_SVS_AutoVwBttnShw 0 "Do_not_show_auto_camera_view_button" 1 "Show_auto_camera_view_button" 2 "Show_auto_camera_view_button(fault,_not_Press-able)" 3 "Reserved" ;
VAL_ 790 ADASDC_SVS_RearMidBttnShw 0 "Do_not_show_rear_mid_camera_view_button" 1 "Show_rear_mid_camera_view_button" 2 "Show_rear_mid_camera_view_button(fault,_not_Press-able)" 3 "Reserved" ;
VAL_ 790 ADASDC_SVS_FrntMidBttnShw 0 "Do_not_show_front_mid_camera_view_button" 1 "Show_front_mid_camera_view_button" 2 "Show_front_mid_camera_view_button(fault,_not_Press-able)" 3 "Reserved" ;
VAL_ 790 ADASDC_SVS_SplitBttnShw 0 "Do_not_show_split_camera_view_button" 1 "Show_split_camera_view_button" 2 "Show_split_camera_view_button(fault,_not_Press-able)" 3 "Reserved" ;
VAL_ 790 ADASDC_SVS_LeftFlnk3DBttnShw 0 "Do_not_show_left_flank_camera_view_button" 1 "Show_left_flank_camera_view_button" 2 "Show_left_flank_camera_view_button(fault,_not_Press-able)" 3 "Reserved" ;
VAL_ 790 ADASDC_SVS_RightFlnk3DBttnShw 0 "Do_not_show_right_flank_camera_view_button" 1 "Show_right_flank_camera_view_button" 2 "Show_right_flank_camera_view_button(fault,_not_Press-able)" 3 "Reserved" ;
VAL_ 790 ADASDC_SVS_ShowReq 0 "No_Request" 1 "Show_Request" ;
